VERSION ""

NS_ :

BS_:

BU_: ESM HIB HIP HIS SaGE CBC DASM DIAGNOST EBCM ECM EPS ESC ESL ETM HALF HCP IC OCM ORC PTS RF_HUB SCCM SGW

BO_ 1468 ECU_APPL_BSMO: 8 ESC
 SG_ ECU_APPL_BSMO : 7|64@0+ (1,0) [0|0] ""  DIAGNOST,SGW

BO_ 1409 ECU_APPL_CBC: 8 CBC
 SG_ ECU_APPL_CBC : 7|64@0+ (1,0) [0|0] ""  DIAGNOST,SGW

BO_ 1427 ECU_APPL_DASM: 8 DASM
 SG_ ECU_APPL_DASM : 7|64@0+ (1,0) [0|0] ""  DIAGNOST,SGW

BO_ 1467 ECU_APPL_EBCM: 8 EBCM
 SG_ ECU_APPL_EBCM : 7|64@0+ (1,0) [0|0] ""  DIAGNOST,SGW

BO_ 1464 ECU_APPL_ECM: 8 ECM
 SG_ ECU_APPL_ECM : 7|64@0+ (1,0) [0|0] ""  DIAGNOST,SGW

BO_ 1434 ECU_APPL_EPS: 8 EPS
 SG_ ECU_APPL_EPS : 7|64@0+ (1,0) [0|0] ""  DIAGNOST,SGW

BO_ 1416 ECU_APPL_ESL: 8 ESL
 SG_ ECU_APPL_ESL : 7|64@0+ (1,0) [0|0] ""  DIAGNOST,SGW

BO_ 1417 ECU_APPL_ESM: 8 ESM
 SG_ ECU_APPL_ESM : 7|64@0+ (1,0) [0|0] ""  DIAGNOST,SGW

BO_ 1466 ECU_APPL_HCP: 8 HCP
 SG_ ECU_APPL_HCP : 7|64@0+ (1,0) [0|0] ""  DIAGNOST,SGW

BO_ 1444 ECU_APPL_HaLF: 8 HALF
 SG_ ECU_APPL_HaLF : 7|64@0+ (1,0) [0|0] ""  DIAGNOST,SGW

BO_ 1410 ECU_APPL_IC: 8 IC
 SG_ ECU_APPL_IC : 7|64@0+ (1,0) [0|0] ""  DIAGNOST,SGW

BO_ 1438 ECU_APPL_OCM: 8 OCM
 SG_ ECU_APPL_OCM : 7|64@0+ (1,0) [0|0] ""  DIAGNOST,SGW

BO_ 1412 ECU_APPL_ORC: 8 ORC
 SG_ ECU_APPL_ORC : 7|64@0+ (1,0) [0|0] ""  DIAGNOST,SGW

BO_ 1442 ECU_APPL_PTS: 8 PTS
 SG_ ECU_APPL_PTS : 7|64@0+ (1,0) [0|0] ""  DIAGNOST,SGW

BO_ 1408 ECU_APPL_RF_HUB: 8 RF_HUB
 SG_ ECU_APPL_RF_HUB : 7|64@0+ (1,0) [0|0] ""  DIAGNOST,SGW

BO_ 1443 ECU_APPL_SCCM: 8 SCCM
 SG_ ECU_APPL_SCCM : 7|64@0+ (1,0) [0|0] ""  DIAGNOST,SGW

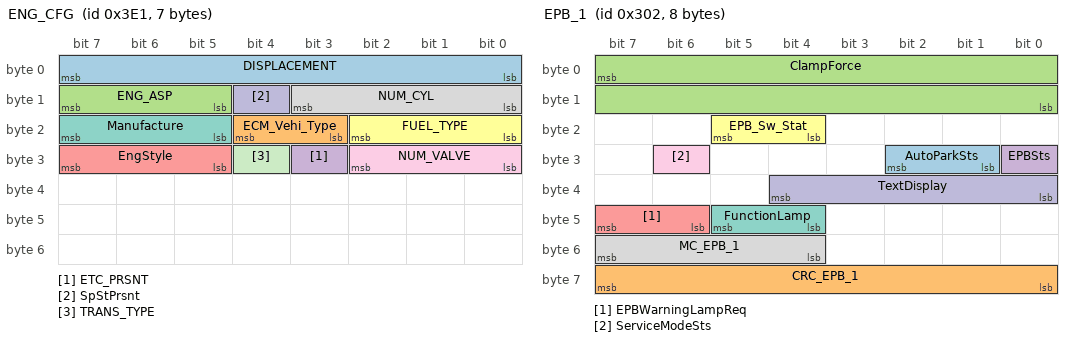
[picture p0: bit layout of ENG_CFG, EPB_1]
BO_ 993 ENG_CFG: 7 ECM
 SG_ DISPLACEMENT : 0|8@1+ (0.1,0) [0|25] "liters"  HIB,ESC,ETM,HALF,ORC,SGW
 SG_ ECM_Vehi_Type : 19|2@1+ (1,0) [0|0] ""  SGW
 SG_ ENG_ASP : 13|3@1+ (1,0) [0|0] ""  ESC,SGW
 SG_ ETC_PRSNT : 27|1@1+ (1,0) [0|0] ""  SGW
 SG_ EngStyle : 29|3@1+ (1,0) [0|0] ""  CBC,ESC,SGW
 SG_ FUEL_TYPE : 16|3@1+ (1,0) [0|0] ""  CBC,ESC,ETM,IC,ORC,SGW
 SG_ Manufacture : 21|3@1+ (1,0) [0|0] ""  SGW
 SG_ NUM_CYL : 8|4@1+ (1,0) [0|14] "cylinders"  HIB,ESC,ETM,HALF,IC,SGW
 SG_ NUM_VALVE : 24|3@1+ (1,0) [0|6] "valve-per-cylinder"  SGW
 SG_ SpStPrsnt : 12|1@1+ (1,0) [0|0] ""  HIB,CBC,EPS,ESC,HALF,IC,PTS,SGW
 SG_ TRANS_TYPE : 28|1@1+ (1,0) [0|0] ""  ETM,SGW

BO_ 770 EPB_1: 8 ESC
 SG_ AutoParkSts : 25|2@1+ (1,0) [0|0] ""  CBC,SGW
 SG_ CRC_EPB_1 : 56|8@1+ (1,0) [0|0] ""  HIB,DASM,ECM,IC,SGW
 SG_ ClampForce : 7|16@0+ (1,0) [0|65535] "N"  ORC,SGW
 SG_ EPBSts : 24|1@1+ (1,0) [0|0] ""  HIB,DASM,ECM,ETM,HCP,SGW
 SG_ EPBWarningLampReq : 46|2@1+ (1,0) [0|0] ""  IC,ORC,SGW
 SG_ EPB_Sw_Stat : 20|2@1+ (1,0) [0|0] ""  ORC,SGW
 SG_ FunctionLamp : 44|2@1+ (1,0) [0|0] ""  IC,SGW
 SG_ MC_EPB_1 : 52|4@1+ (1,0) [0|15] ""  HIB,DASM,ECM,IC,SGW
 SG_ ServiceModeSts : 30|1@1+ (1,0) [0|0] ""  CBC,SGW
 SG_ TextDisplay : 32|5@1+ (1,0) [0|0] ""  CBC,IC,SGW

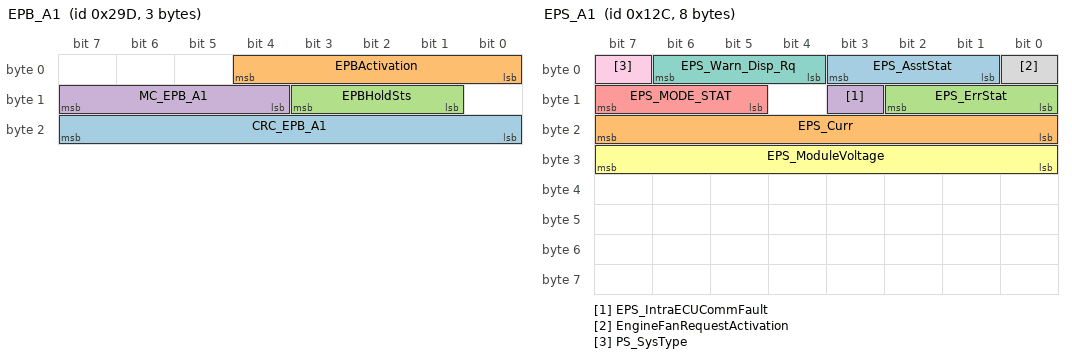
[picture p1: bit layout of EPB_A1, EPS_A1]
BO_ 669 EPB_A1: 3 ESC
 SG_ CRC_EPB_A1 : 16|8@1+ (1,0) [0|0] ""  HIB,DASM,ECM,HCP,PTS,SGW
 SG_ EPBActivation : 0|5@1+ (1,0) [0|0] ""  SGW
 SG_ EPBHoldSts : 9|3@1+ (1,0) [0|0] ""  HIB,CBC,DASM,ECM,HCP,ORC,PTS,SGW
 SG_ MC_EPB_A1 : 12|4@1+ (1,0) [0|15] ""  HIB,DASM,ECM,HCP,PTS,SGW

BO_ 544 EPS_1: 8 EPS
 SG_ DSTTorqueOverlayIntActivated : 37|1@1+ (1,0) [0|0] ""  HALF,ESC
 SG_ AssistanceTorque : 19|12@0+ (0.05,-100) [-100|104.65] "Nm"  HIS,ESC
 SG_ DSTTorqueOverlayFault : 21|1@1+ (1,0) [0|0] ""  HALF,ESC
 SG_ TOI_Act_Sts : 3|4@1+ (1,0) [0|0] ""  ORC,ESC
 SG_ CRC_EPS_1 : 56|8@1+ (1,0) [0|0] ""  HIB,ECM,ESC,HALF,PTS,SGW
 SG_ EPSHandsOnRecognition : 48|1@1+ (1,0) [0|0] ""  PTS,SGW
 SG_ EPSMotorTorque : 34|11@0+ (0.001953125,-2) [-2|1.998047] "Nm"  HIB,HALF,ORC,SGW
 SG_ EPSMotorTorqueValidData : 39|1@1+ (1,0) [0|0] ""  HIB,HALF,SGW
 SG_ EPSTemporaryDeactivationLDW : 38|1@1+ (1,0) [0|0] ""  HIB,HALF,SGW
 SG_ EPSTemporaryDeactivationPPPA : 49|1@1+ (1,0) [0|0] ""  PTS,SGW
 SG_ HALFTorqueOverlayFault : 22|1@1+ (1,0) [0|0] ""  HIB,HALF,SGW
 SG_ HALFTorqueOverlayIntActivated : 23|1@1+ (1,0) [0|0] ""  HIB,HALF,ORC,SGW
 SG_ MC_EPS_1 : 52|4@1+ (1,0) [0|15] ""  HIB,ECM,ESC,HALF,PTS,SGW
 SG_ PTSDriveStyleSts : 20|1@1+ (1,0) [0|0] ""  PTS,SGW
 SG_ PTSTorqueOverlayFault : 50|1@1+ (1,0) [0|0] ""  PTS,SGW
 SG_ PTSTorqueOverlayIntActivated : 51|1@1+ (1,0) [0|0] ""  PTS,SGW
 SG_ StrClmTrq : 2|11@0+ (0.0078125,-8) [-8|7.98] "Nm"  HIB,ECM,HALF,ORC,PTS,SGW
 SG_ StrClmTrqVD : 7|1@1+ (1,0) [0|0] ""  HIB,ECM,HALF,PTS,SGW

BO_ 300 EPS_A1: 8 EPS
 SG_ EPS_AsstStat : 1|3@1+ (1,0) [0|0] ""  HIS,ESC,SGW
 SG_ EPS_Curr : 16|8@1+ (1,-50) [-50|204] "Amp"  HIS,SGW
 SG_ EPS_ErrStat : 8|3@1+ (1,0) [0|0] ""  HIS,SGW
 SG_ EPS_IntraECUCommFault : 11|1@1+ (1,0) [0|0] ""  HIS,SGW
 SG_ EPS_MODE_STAT : 13|3@1+ (1,0) [0|0] ""  HIS,HIB,CBC,HALF,ORC,SGW
 SG_ EPS_ModuleVoltage : 24|8@1+ (0.1,0) [0|25.4] "Volts"  HIS,SGW
 SG_ EPS_Warn_Disp_Rq : 4|3@1+ (1,0) [0|0] ""  HIS,CBC,ETM,IC,ORC,SGW
 SG_ EngineFanRequestActivation : 0|1@1+ (1,0) [0|0] ""  HIS,ECM,SGW
 SG_ PS_SysType : 7|1@1+ (1,0) [0|0] ""  HIS,CBC,ESC,SGW

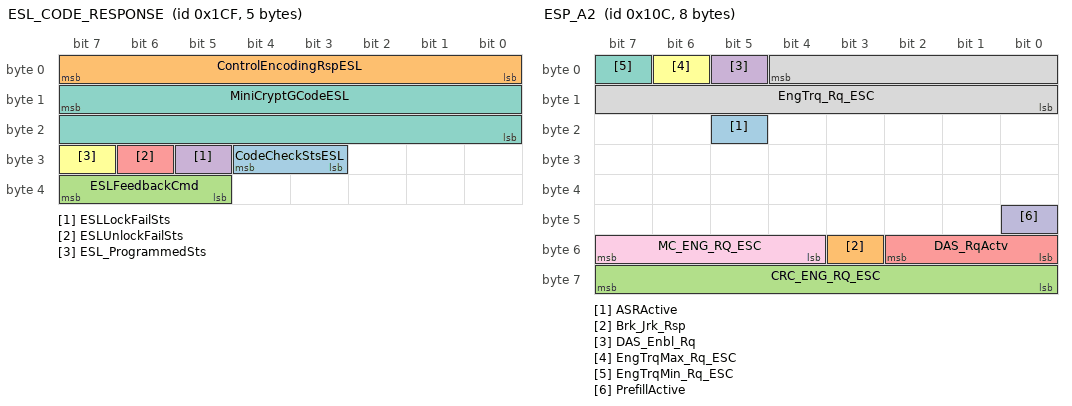
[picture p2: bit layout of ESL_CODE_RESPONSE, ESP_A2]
BO_ 463 ESL_CODE_RESPONSE: 5 ESL
 SG_ CodeCheckStsESL : 27|2@1+ (1,0) [0|0] ""  CBC,SGW
 SG_ ControlEncodingRspESL : 0|8@1+ (1,0) [0|0] ""  CBC,SGW
 SG_ ESLFeedbackCmd : 37|3@1+ (1,0) [0|0] ""  CBC,SGW
 SG_ ESLLockFailSts : 29|1@1+ (1,0) [0|0] ""  CBC,SGW
 SG_ ESLUnlockFailSts : 30|1@1+ (1,0) [0|0] ""  CBC,SGW
 SG_ ESL_ProgrammedSts : 31|1@1+ (1,0) [0|0] ""  SGW
 SG_ MiniCryptGCodeESL : 15|16@0+ (1,0) [0|0] ""  CBC,SGW

BO_ 320 ESP_A1: 8 ESC
 SG_ ABS_BrkEvt : 14|1@1+ (1,0) [0|0] ""  DASM,HALF,ORC,PTS,SGW
 SG_ BrkIntrvntn_Actv_AS : 6|1@1+ (1,0) [0|0] ""  HIB,DASM,ETM,SGW
 SG_ BrkIntrvntn_Actv_ESP : 5|1@1+ (1,0) [0|0] ""  HIB,ETM,HALF,ORC,PTS,SGW
 SG_ BrkIntrvntn_Enbl : 7|1@1+ (1,0) [0|0] ""  ECM,ORC,SGW
 SG_ BrkPdl_Flt : 4|1@1+ (1,0) [0|0] ""  HIB,DASM,ECM,ETM,HALF,SGW
 SG_ BrkPdl_Stat : 2|2@1+ (1,0) [0|0] ""  HIB,CBC,DASM,ECM,HALF,HCP,ORC,RF_HUB,SGW
 SG_ Brk_Stat : 0|2@1+ (1,0) [0|0] ""  HIB,CBC,DASM,ECM,HALF,PTS,SGW
 SG_ Brk_Thermdl : 25|1@1+ (1,0) [0|0] ""  HIB,DASM,SGW
 SG_ CRC_Brk_Stat : 56|8@1+ (1,0) [0|0] ""  HIB,DASM,ECM,HALF,HCP,IC,ORC,PTS,SGW
 SG_ DTR_CC_Enabled : 23|1@1+ (1,0) [0|0] ""  ECM,SGW
 SG_ DTR_CC_Engaged : 15|1@1+ (1,0) [0|0] ""  CBC,ECM,HCP,SGW
 SG_ ESP_Sys_Stat : 10|2@1+ (1,0) [0|0] ""  HIB,DASM,ECM,ETM,HALF,PTS,SGW
 SG_ EmgBrk_Actv : 8|1@1+ (1,0) [0|0] ""  ORC,SGW
 SG_ FullBrk_Actv : 9|1@1+ (1,0) [0|0] ""  ORC,SGW
 SG_ MC_Brk_Stat : 52|4@1+ (1,0) [0|15] ""  HIB,DASM,ECM,HALF,HCP,IC,ORC,PTS,SGW
 SG_ REF_VEH_SPEED : 33|10@0+ (0.5,0) [0|511] "km/h"  HCP,ORC,SGW
 SG_ RollTestMd_Actv : 30|2@1+ (1,0) [0|0] ""  HIB,DASM,SGW
 SG_ SPCR_AS_Off_Rq : 38|2@1+ (1,0) [0|0] ""  HIB,DASM,ECM,SGW

BO_ 268 ESP_A2: 8 ESC
 SG_ ASRActive : 21|1@1+ (1,0) [0|0] ""  HIB,DASM,ORC,SGW
 SG_ Brk_Jrk_Rsp : 51|1@1+ (1,0) [0|0] ""  HIB,DASM,ORC,SGW
 SG_ CRC_ENG_RQ_ESC : 56|8@1+ (1,0) [0|0] ""  HIB,DASM,ECM,SGW
 SG_ DAS_Enbl_Rq : 5|1@1+ (1,0) [0|0] ""  HIB,DASM,ECM,SGW
 SG_ DAS_RqActv : 48|3@1+ (1,0) [0|0] ""  HIB,DASM,HALF,ORC,SGW
 SG_ EngTrqMax_Rq_ESC : 6|1@1+ (1,0) [0|0] ""  SGW
 SG_ EngTrqMin_Rq_ESC : 7|1@1+ (1,0) [0|0] ""  SGW
 SG_ EngTrq_Rq_ESC : 4|13@0+ (0.25,-500) [-500|1547.5] "Nm"  ETM,SGW
 SG_ MC_ENG_RQ_ESC : 52|4@1+ (1,0) [0|15] ""  HIB,DASM,ECM,SGW
 SG_ PrefillActive : 40|1@1+ (1,0) [0|0] ""  HIB,DASM,SGW

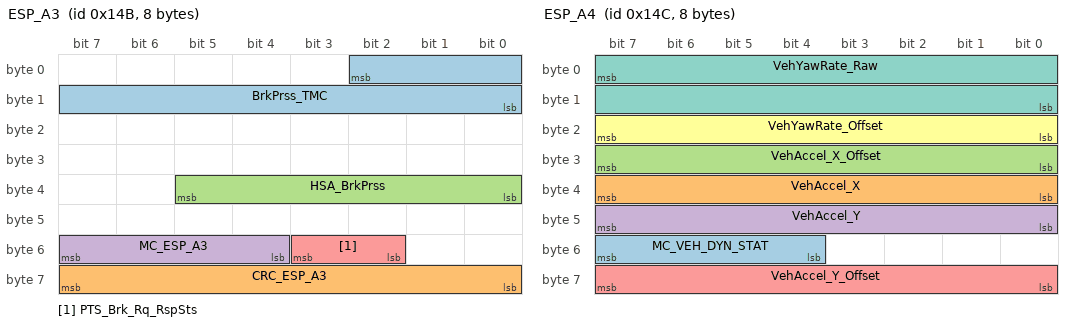
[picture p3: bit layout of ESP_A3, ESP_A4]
BO_ 331 ESP_A3: 8 ESC
 SG_ BrkPrss_TMC : 2|11@0+ (0.1,0) [0|200] "bar"  HIB,ECM,ETM,HALF,HCP,ORC,SGW
 SG_ CRC_ESP_A3 : 56|8@1+ (1,0) [0|0] ""  ECM,HCP,ORC,PTS,SGW
 SG_ HSA_BrkPrss : 32|6@1+ (1,0) [0|50] "bar"  ECM,ETM,ORC,SGW
 SG_ MC_ESP_A3 : 52|4@1+ (1,0) [0|15] ""  ECM,HCP,ORC,PTS,SGW
 SG_ PTS_Brk_Rq_RspSts : 50|2@1+ (1,0) [0|0] ""  IC,PTS,SGW

BO_ 332 ESP_A4: 8 ESC
 SG_ MC_VEH_DYN_STAT : 52|4@1+ (1,0) [0|15] ""  HIB,DASM,ECM,ETM,HALF,ORC,PTS,SGW
 SG_ VehAccel_X : 32|8@1+ (0.08,-10.24) [-10.24|10.08] "m/s²"  HIB,EBCM,CBC,DASM,ECM,HALF,HCP,PTS,SGW
 SG_ VehAccel_X_Offset : 24|8@1+ (0.02,-2.56) [-2.56|2.52] "m/s²"  HIB,EBCM,DASM,ECM,ETM,HALF,HCP,PTS,SGW
 SG_ VehAccel_Y : 40|8@1+ (0.08,-10.24) [-10.24|10.08] "m/s²"  HIB,DASM,ECM,EPS,HALF,HCP,SGW
 SG_ VehAccel_Y_Offset : 56|8@1+ (0.02,-2.56) [-2.56|2.52] "m/s²"  HIB,DASM,ECM,ETM,HALF,HCP,SGW
 SG_ VehYawRate_Offset : 16|8@1+ (0.08,-10.24) [-6.96|6.96] ""  HIB,DASM,HALF,ORC,SGW
 SG_ VehYawRate_Raw : 7|16@0+ (0.01,-327.68) [-327.68|327.66] "°/s"  HIB,CBC,DASM,ETM,HALF,PTS,SGW

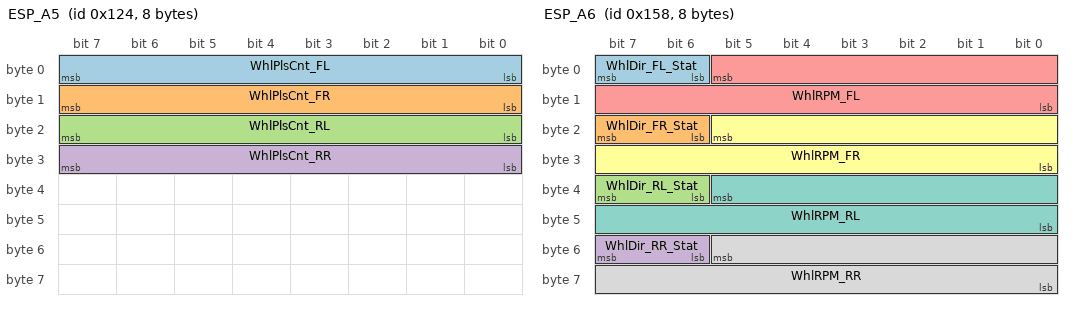
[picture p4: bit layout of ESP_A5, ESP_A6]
BO_ 292 ESP_A5: 8 ESC
 SG_ WhlPlsCnt_FL : 0|8@1+ (1,0) [0|254] "Impulse"  HIB,CBC,DASM,PTS,RF_HUB,SGW
 SG_ WhlPlsCnt_FR : 8|8@1+ (1,0) [0|254] "Impulse"  HIB,CBC,DASM,PTS,RF_HUB,SGW
 SG_ WhlPlsCnt_RL : 16|8@1+ (1,0) [0|254] "Impulse"  HIB,CBC,DASM,EPS,PTS,RF_HUB,SGW
 SG_ WhlPlsCnt_RR : 24|8@1+ (1,0) [0|254] "Impulse"  HIB,CBC,DASM,EPS,PTS,RF_HUB,SGW

BO_ 344 ESP_A6: 8 ESC
 SG_ WhlDir_FL_Stat : 6|2@1+ (1,0) [0|0] ""  HIB,DASM,HCP,SGW
 SG_ WhlDir_FR_Stat : 22|2@1+ (1,0) [0|0] ""  HIB,DASM,HCP,SGW
 SG_ WhlDir_RL_Stat : 38|2@1+ (1,0) [0|0] ""  HIB,DASM,EPS,HCP,ORC,PTS,SGW
 SG_ WhlDir_RR_Stat : 54|2@1+ (1,0) [0|0] ""  HIB,DASM,EPS,HCP,ORC,PTS,SGW
 SG_ WhlRPM_FL : 5|14@0+ (0.5,0) [0|8191] "rpm"  HIB,DASM,HCP,ORC,PTS,SGW
 SG_ WhlRPM_FR : 21|14@0+ (0.5,0) [0|8191] "rpm"  HIB,DASM,HCP,ORC,PTS,SGW
 SG_ WhlRPM_RL : 37|14@0+ (0.5,0) [0|8191] "rpm"  HIB,DASM,HCP,ORC,PTS,SGW
 SG_ WhlRPM_RR : 53|14@0+ (0.5,0) [0|8191] "rpm"  HIB,DASM,HCP,ORC,PTS,SGW

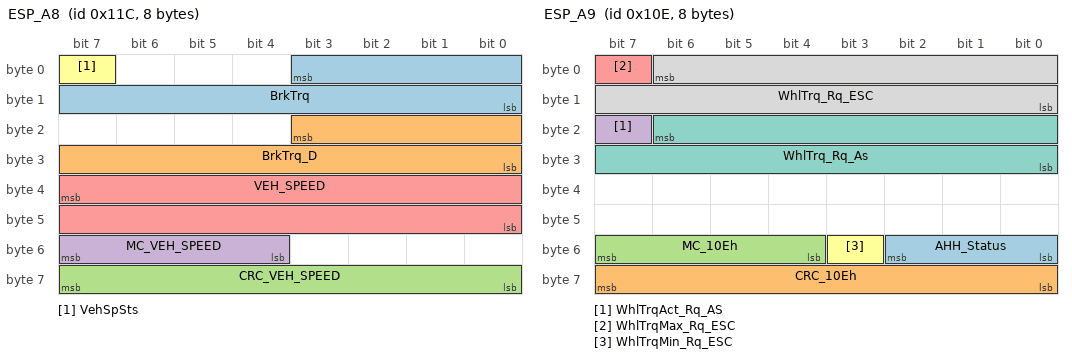
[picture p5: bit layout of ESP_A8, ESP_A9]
BO_ 284 ESP_A8: 8 ESC
 SG_ BrkTrq : 3|12@0+ (3,0) [0|12282] "Nm"  HIB,DASM,ORC,SGW
 SG_ BrkTrq_D : 19|12@0+ (3,0) [0|12282] "Nm"  HIB,DASM,SGW
 SG_ CRC_VEH_SPEED : 56|8@1+ (1,0) [0|0] ""  HIB,DASM,EBCM,ECM,EPS,ESL,HALF,HCP,IC,ORC,PTS,SGW
 SG_ MC_VEH_SPEED : 52|4@1+ (1,0) [0|15] ""  HIB,DASM,EBCM,ECM,EPS,ESL,HALF,HCP,IC,ORC,PTS,SGW
 SG_ VEH_SPEED : 39|16@0+ (0.0078125,0) [0|511.984375] "km/h"  HIB,CBC,DASM,EBCM,ECM,EPS,ESL,HALF,HCP,IC,ORC,PTS,RF_HUB,SGW
 SG_ VehSpSts : 7|1@1+ (1,0) [0|0] ""  HIB,DASM,SGW

BO_ 270 ESP_A9: 8 ESC
 SG_ AHH_Status : 48|3@1+ (1,0) [0|0] ""  HCP,SGW
 SG_ CRC_10Eh : 56|8@1+ (1,0) [0|255] ""  HIB,DASM,ECM,SGW
 SG_ MC_10Eh : 52|4@1+ (1,0) [0|15] ""  HIB,DASM,ECM,SGW
 SG_ WhlTrqAct_Rq_AS : 23|1@1+ (1,0) [0|0] ""  ECM,SGW
 SG_ WhlTrqMax_Rq_ESC : 7|1@1+ (1,0) [0|0] ""  HIB,DASM,ECM,SGW
 SG_ WhlTrqMin_Rq_ESC : 51|1@1+ (1,0) [0|0] ""  ECM,SGW
 SG_ WhlTrq_Rq_As : 22|15@0+ (1,-7767) [-7767|24999] "Nm"  ECM,ORC,SGW
 SG_ WhlTrq_Rq_ESC : 6|15@0+ (1,-7767) [-7767|24999] "Nm"  HIB,DASM,ECM,SGW

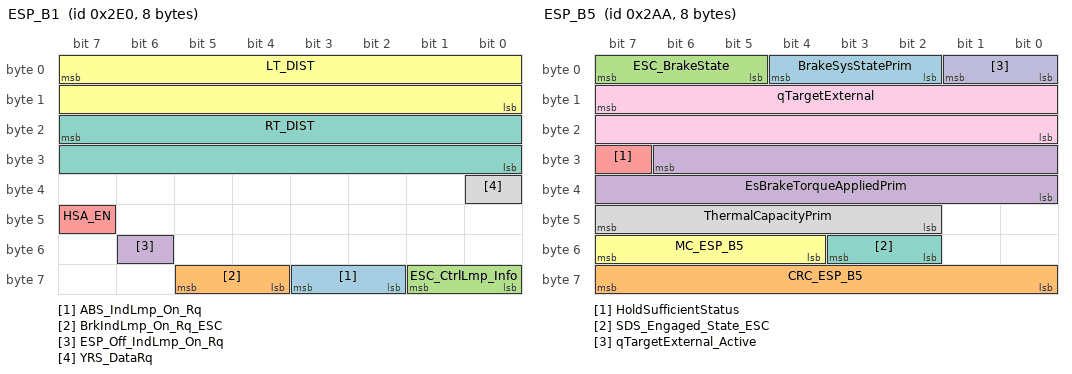
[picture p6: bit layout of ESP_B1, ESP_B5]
BO_ 736 ESP_B1: 8 ESC
 SG_ ABS_IndLmp_On_Rq : 58|2@1+ (1,0) [0|0] ""  ETM,IC,SGW
 SG_ BrkIndLmp_On_Rq_ESC : 60|2@1+ (1,0) [0|0] ""  ETM,IC,ORC,SGW
 SG_ ESC_CtrlLmp_Info : 56|2@1+ (1,0) [0|0] ""  ETM,IC,ORC,SGW
 SG_ ESP_Off_IndLmp_On_Rq : 54|1@1+ (1,0) [0|0] ""  CBC,IC,ORC,SGW
 SG_ HSA_EN : 47|1@1+ (1,0) [0|0] ""  CBC,SGW
 SG_ LT_DIST : 7|16@0+ (4,0) [0|262136] "cm"  CBC,ECM,IC,PTS,SGW
 SG_ RT_DIST : 23|16@0+ (4,0) [0|262136] "cm"  CBC,ECM,IC,PTS,SGW
 SG_ YRS_DataRq : 32|1@1+ (1,0) [0|0] ""  ORC,SGW

BO_ 737 ESP_B2: 8 ESC
 SG_ ESCSysEmsMlfAtv : 18|1@1+ (1,0) [0|0] ""  SGW
 SG_ MIL_OnRq_ESC : 2|1@1+ (1,0) [0|0] ""  ECM,HCP,SGW

BO_ 682 ESP_B5: 8 ESC
 SG_ BrakeSysStatePrim : 2|3@1+ (1,0) [0|0] ""  EBCM,SGW
 SG_ CRC_ESP_B5 : 56|8@1+ (1,0) [0|0] ""  EBCM,SGW
 SG_ ESC_BrakeState : 5|3@1+ (1,0) [0|0] ""  EBCM,SGW
 SG_ EsBrakeTorqueAppliedPrim : 30|15@0+ (2,-65534) [-65534|0] "Nm"  SGW
 SG_ HoldSufficientStatus : 31|1@1+ (1,0) [0|0] ""  SGW
 SG_ MC_ESP_B5 : 52|4@1+ (1,0) [0|15] ""  EBCM,SGW
 SG_ SDS_Engaged_State_ESC : 50|2@1+ (1,0) [0|0] ""  SGW
 SG_ ThermalCapacityPrim : 42|6@1+ (1.5873,0) [0|99.9999] "%"  SGW
 SG_ qTargetExternal : 15|16@0+ (0.0078125,-252) [-252|252] "ml/sec"  SGW
 SG_ qTargetExternal_Active : 0|2@1+ (1,0) [0|0] ""  SGW

BO_ 840 ESP_C1: 8 ESC
 SG_ FailSafeError : 7|16@0+ (1,0) [0|65534] ""  HIB,DASM,SGW

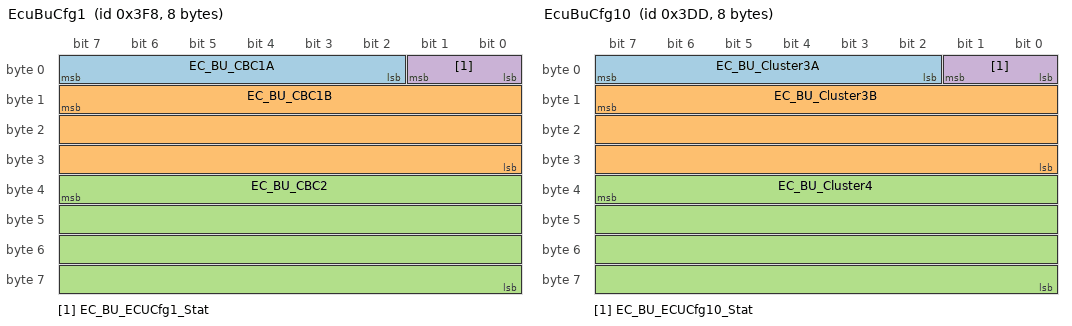
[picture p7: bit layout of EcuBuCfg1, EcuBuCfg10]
BO_ 1016 EcuBuCfg1: 8 RF_HUB
 SG_ EC_BU_CBC1A : 2|6@1+ (1,0) [0|0] ""  CBC,SGW
 SG_ EC_BU_CBC1B : 15|24@0+ (1,0) [0|0] ""  CBC,SGW
 SG_ EC_BU_CBC2 : 39|32@0+ (1,0) [0|0] ""  CBC,SGW
 SG_ EC_BU_ECUCfg1_Stat : 0|2@1+ (1,0) [0|0] ""  CBC,SGW

BO_ 989 EcuBuCfg10: 8 RF_HUB
 SG_ EC_BU_Cluster3A : 2|6@1+ (1,0) [0|0] ""  CBC,SGW
 SG_ EC_BU_Cluster3B : 15|24@0+ (1,0) [0|0] ""  CBC,SGW
 SG_ EC_BU_Cluster4 : 39|32@0+ (1,0) [0|0] ""  CBC,SGW
 SG_ EC_BU_ECUCfg10_Stat : 0|2@1+ (1,0) [0|0] ""  CBC,SGW

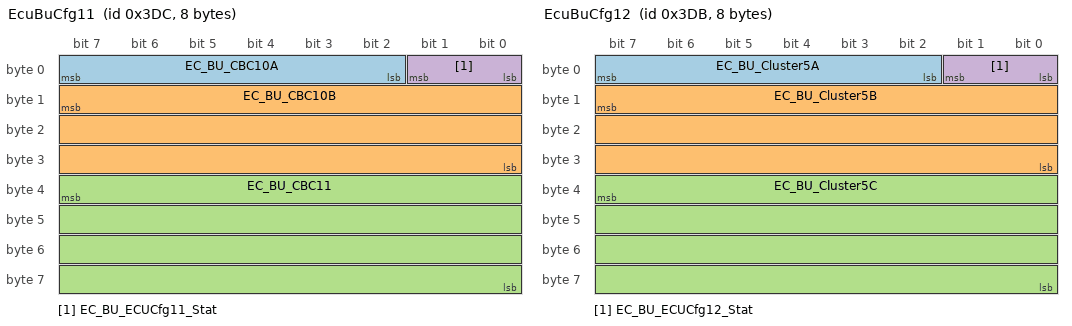
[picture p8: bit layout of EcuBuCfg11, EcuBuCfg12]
BO_ 988 EcuBuCfg11: 8 RF_HUB
 SG_ EC_BU_CBC10A : 2|6@1+ (1,0) [0|0] ""  CBC,SGW
 SG_ EC_BU_CBC10B : 15|24@0+ (1,0) [0|0] ""  CBC,SGW
 SG_ EC_BU_CBC11 : 39|32@0+ (1,0) [0|0] ""  CBC,SGW
 SG_ EC_BU_ECUCfg11_Stat : 0|2@1+ (1,0) [0|0] ""  CBC,SGW

BO_ 987 EcuBuCfg12: 8 RF_HUB
 SG_ EC_BU_Cluster5A : 2|6@1+ (1,0) [0|0] ""  CBC,SGW
 SG_ EC_BU_Cluster5B : 15|24@0+ (1,0) [0|0] ""  CBC,SGW
 SG_ EC_BU_Cluster5C : 39|32@0+ (1,0) [0|0] ""  CBC,SGW
 SG_ EC_BU_ECUCfg12_Stat : 0|2@1+ (1,0) [0|0] ""  CBC,SGW

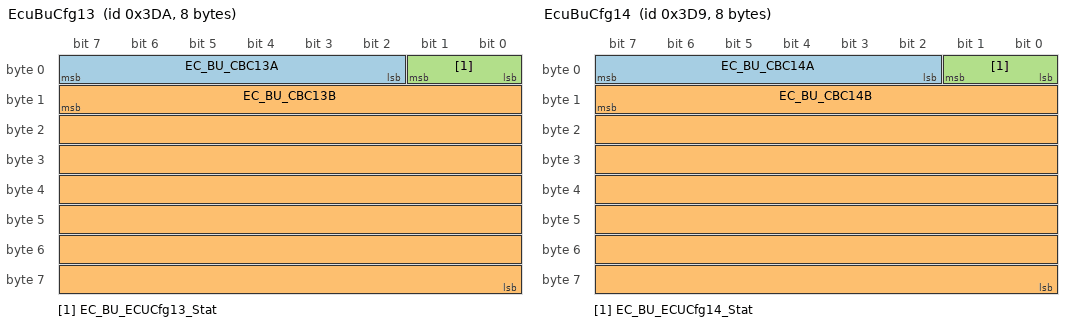
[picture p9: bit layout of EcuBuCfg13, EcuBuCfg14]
BO_ 986 EcuBuCfg13: 8 RF_HUB
 SG_ EC_BU_CBC13A : 2|6@1+ (1,0) [0|0] ""  CBC,SGW
 SG_ EC_BU_CBC13B : 15|56@0+ (1,0) [0|0] ""  CBC,SGW
 SG_ EC_BU_ECUCfg13_Stat : 0|2@1+ (1,0) [0|0] ""  CBC,SGW

BO_ 985 EcuBuCfg14: 8 RF_HUB
 SG_ EC_BU_CBC14A : 2|6@1+ (1,0) [0|0] ""  CBC,SGW
 SG_ EC_BU_CBC14B : 15|56@0+ (1,0) [0|0] ""  CBC,SGW
 SG_ EC_BU_ECUCfg14_Stat : 0|2@1+ (1,0) [0|0] ""  CBC,SGW

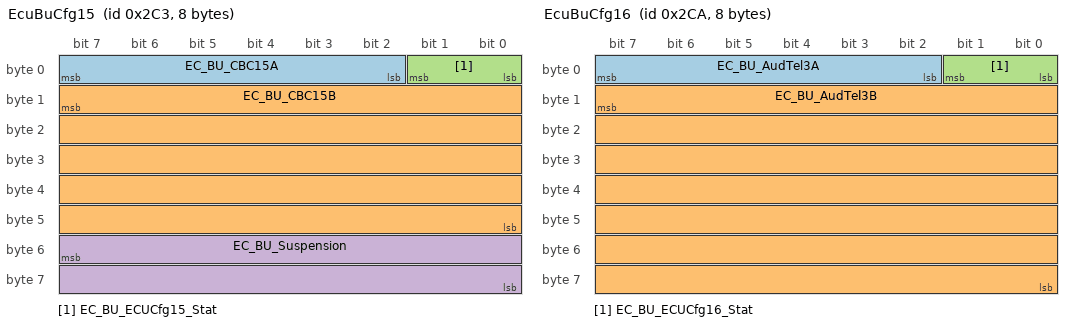
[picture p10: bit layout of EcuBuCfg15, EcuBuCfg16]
BO_ 707 EcuBuCfg15: 8 RF_HUB
 SG_ EC_BU_CBC15A : 2|6@1+ (1,0) [0|0] ""  CBC,SGW
 SG_ EC_BU_CBC15B : 15|40@0+ (1,0) [0|0] ""  CBC,SGW
 SG_ EC_BU_ECUCfg15_Stat : 0|2@1+ (1,0) [0|0] ""  CBC,SGW
 SG_ EC_BU_Suspension : 55|16@0+ (1,0) [0|0] ""  CBC,SGW

BO_ 714 EcuBuCfg16: 8 RF_HUB
 SG_ EC_BU_AudTel3A : 2|6@1+ (1,0) [0|0] ""  CBC,SGW
 SG_ EC_BU_AudTel3B : 15|56@0+ (1,0) [0|0] ""  CBC,SGW
 SG_ EC_BU_ECUCfg16_Stat : 0|2@1+ (1,0) [0|0] ""  CBC,SGW

BO_ 715 EcuBuCfg17: 8 RF_HUB
 SG_ EC_BU_ECUCfg17_Stat : 0|2@1+ (1,0) [0|0] ""  CBC,SGW
 SG_ EC_BU_PTS : 56|8@1+ (1,0) [0|0] ""  CBC,SGW

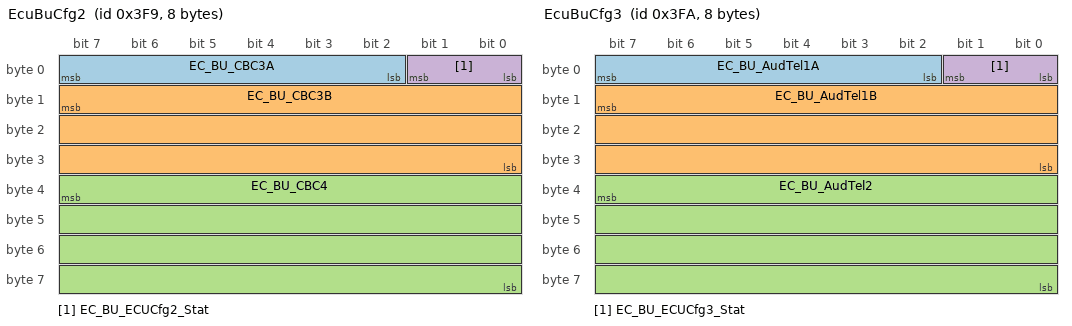
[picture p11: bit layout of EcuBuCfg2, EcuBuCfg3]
BO_ 1017 EcuBuCfg2: 8 RF_HUB
 SG_ EC_BU_CBC3A : 2|6@1+ (1,0) [0|0] ""  CBC,SGW
 SG_ EC_BU_CBC3B : 15|24@0+ (1,0) [0|0] ""  CBC,SGW
 SG_ EC_BU_CBC4 : 39|32@0+ (1,0) [0|0] ""  CBC,SGW
 SG_ EC_BU_ECUCfg2_Stat : 0|2@1+ (1,0) [0|0] ""  CBC,SGW

BO_ 1018 EcuBuCfg3: 8 RF_HUB
 SG_ EC_BU_AudTel1A : 2|6@1+ (1,0) [0|0] ""  CBC,SGW
 SG_ EC_BU_AudTel1B : 15|24@0+ (1,0) [0|0] ""  CBC,SGW
 SG_ EC_BU_AudTel2 : 39|32@0+ (1,0) [0|0] ""  CBC,SGW
 SG_ EC_BU_ECUCfg3_Stat : 0|2@1+ (1,0) [0|0] ""  CBC,SGW

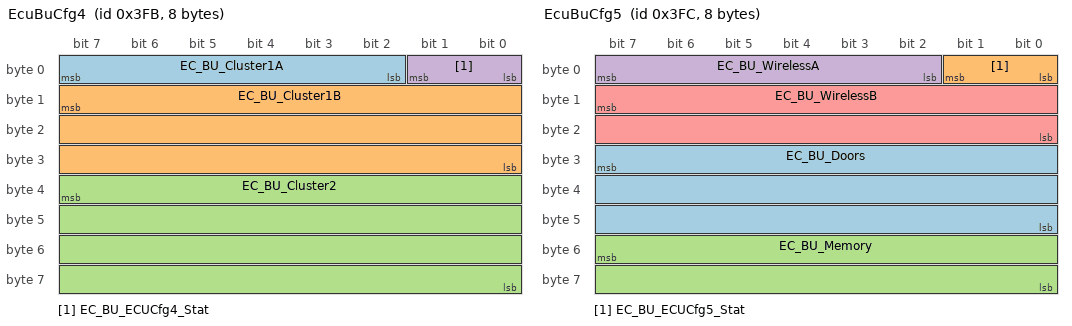
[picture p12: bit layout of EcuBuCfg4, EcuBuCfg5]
BO_ 1019 EcuBuCfg4: 8 RF_HUB
 SG_ EC_BU_Cluster1A : 2|6@1+ (1,0) [0|0] ""  CBC,SGW
 SG_ EC_BU_Cluster1B : 15|24@0+ (1,0) [0|0] ""  CBC,SGW
 SG_ EC_BU_Cluster2 : 39|32@0+ (1,0) [0|0] ""  CBC,SGW
 SG_ EC_BU_ECUCfg4_Stat : 0|2@1+ (1,0) [0|0] ""  CBC,SGW

BO_ 1020 EcuBuCfg5: 8 RF_HUB
 SG_ EC_BU_Doors : 31|24@0+ (1,0) [0|0] ""  CBC,SGW
 SG_ EC_BU_ECUCfg5_Stat : 0|2@1+ (1,0) [0|0] ""  CBC,SGW
 SG_ EC_BU_Memory : 55|16@0+ (1,0) [0|0] ""  CBC,SGW
 SG_ EC_BU_WirelessA : 2|6@1+ (1,0) [0|0] ""  CBC,SGW
 SG_ EC_BU_WirelessB : 15|16@0+ (1,0) [0|0] ""  CBC,SGW

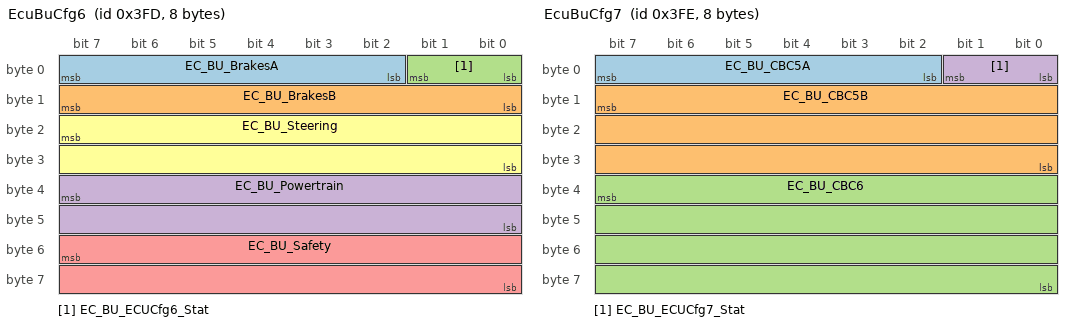
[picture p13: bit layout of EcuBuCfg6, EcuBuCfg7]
BO_ 1021 EcuBuCfg6: 8 RF_HUB
 SG_ EC_BU_BrakesA : 2|6@1+ (1,0) [0|0] ""  CBC,SGW
 SG_ EC_BU_BrakesB : 8|8@1+ (1,0) [0|0] ""  CBC,SGW
 SG_ EC_BU_ECUCfg6_Stat : 0|2@1+ (1,0) [0|0] ""  CBC,SGW
 SG_ EC_BU_Powertrain : 39|16@0+ (1,0) [0|0] ""  CBC,SGW
 SG_ EC_BU_Safety : 55|16@0+ (1,0) [0|0] ""  CBC,SGW
 SG_ EC_BU_Steering : 23|16@0+ (1,0) [0|0] ""  CBC,SGW

BO_ 1022 EcuBuCfg7: 8 RF_HUB
 SG_ EC_BU_CBC5A : 2|6@1+ (1,0) [0|0] ""  CBC,SGW
 SG_ EC_BU_CBC5B : 15|24@0+ (1,0) [0|0] ""  CBC,SGW
 SG_ EC_BU_CBC6 : 39|32@0+ (1,0) [0|0] ""  CBC,SGW
 SG_ EC_BU_ECUCfg7_Stat : 0|2@1+ (1,0) [0|0] ""  CBC,SGW

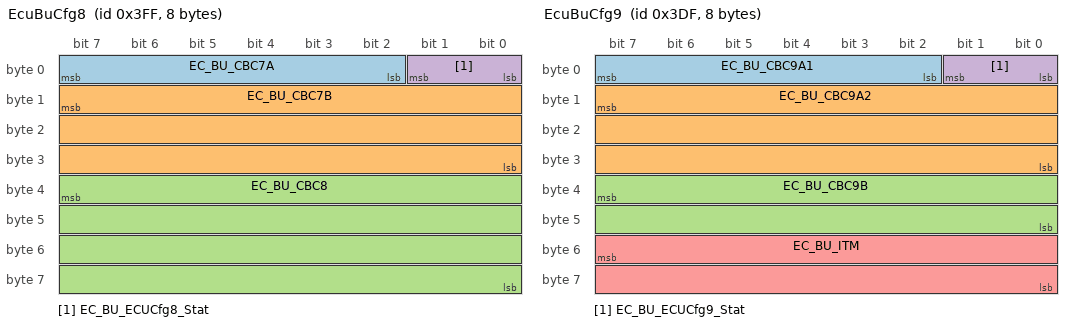
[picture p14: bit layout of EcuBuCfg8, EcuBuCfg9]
BO_ 1023 EcuBuCfg8: 8 RF_HUB
 SG_ EC_BU_CBC7A : 2|6@1+ (1,0) [0|0] ""  CBC,SGW
 SG_ EC_BU_CBC7B : 15|24@0+ (1,0) [0|0] ""  CBC,SGW
 SG_ EC_BU_CBC8 : 39|32@0+ (1,0) [0|0] ""  CBC,SGW
 SG_ EC_BU_ECUCfg8_Stat : 0|2@1+ (1,0) [0|0] ""  CBC,SGW

BO_ 991 EcuBuCfg9: 8 RF_HUB
 SG_ EC_BU_CBC9A1 : 2|6@1+ (1,0) [0|0] ""  CBC,SGW
 SG_ EC_BU_CBC9A2 : 15|24@0+ (1,0) [0|0] ""  CBC,SGW
 SG_ EC_BU_CBC9B : 39|16@0+ (1,0) [0|0] ""  CBC,SGW
 SG_ EC_BU_ECUCfg9_Stat : 0|2@1+ (1,0) [0|0] ""  CBC,SGW
 SG_ EC_BU_ITM : 55|16@0+ (1,0) [0|0] ""  CBC,SGW

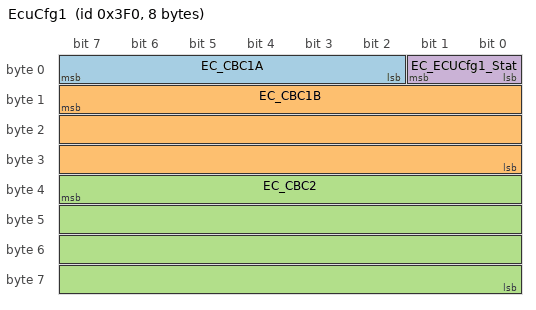
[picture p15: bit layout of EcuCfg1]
BO_ 1008 EcuCfg1: 8 CBC
 SG_ EC_CBC1A : 2|6@1+ (1,0) [0|0] ""  RF_HUB,SGW
 SG_ EC_CBC1B : 15|24@0+ (1,0) [0|0] ""  RF_HUB,SGW
 SG_ EC_CBC2 : 39|32@0+ (1,0) [0|0] ""  RF_HUB,SGW
 SG_ EC_ECUCfg1_Stat : 0|2@1+ (1,0) [0|0] ""  RF_HUB,SGW

CM_ SG_ 1468 ECU_APPL_BSMO "ECU to External Application";
CM_ SG_ 1409 ECU_APPL_CBC "ECU to External Application";
CM_ SG_ 1427 ECU_APPL_DASM "ECU to External Application";
CM_ SG_ 1467 ECU_APPL_EBCM "ECU to External Application";
CM_ SG_ 1464 ECU_APPL_ECM "ECU to External Application";
CM_ SG_ 1434 ECU_APPL_EPS "ECU to External Application";
CM_ SG_ 1416 ECU_APPL_ESL "ECU to External Application";
CM_ SG_ 1417 ECU_APPL_ESM "ECU to External Application";
CM_ SG_ 1466 ECU_APPL_HCP "ECU to External Application";
CM_ SG_ 1444 ECU_APPL_HaLF "ECU to External Application";
CM_ SG_ 1410 ECU_APPL_IC "ECU to External Application";
CM_ SG_ 1438 ECU_APPL_OCM "ECU to External Application";
CM_ SG_ 1412 ECU_APPL_ORC "ECU to External Application";
CM_ SG_ 1442 ECU_APPL_PTS "ECU to External Application";
CM_ SG_ 1408 ECU_APPL_RF_HUB "ECU to External Application";
CM_ SG_ 1443 ECU_APPL_SCCM "ECU to External Application";
CM_ SG_ 993 DISPLACEMENT "Engine displacement";
CM_ SG_ 993 ECM_Vehi_Type "Engine vehicle type";
CM_ SG_ 993 ENG_ASP "Engine aspiration method";
CM_ SG_ 993 ETC_PRSNT "Electronic throttle control";
CM_ SG_ 993 EngStyle "Engine output version";
CM_ SG_ 993 FUEL_TYPE "Fuel type";
CM_ SG_ 993 Manufacture "Engine manufacture";
CM_ SG_ 993 NUM_CYL "Number of engine cylinders";
CM_ SG_ 993 NUM_VALVE "Number of valves per cylinder";
CM_ SG_ 993 SpStPrsnt "Stop start feature present";
CM_ SG_ 993 TRANS_TYPE "Transmission type; [0] = manual, [1] = automatic";
CM_ SG_ 770 AutoParkSts "EPB auto park brake function available status";
CM_ SG_ 770 CRC_EPB_1 "CRC-checksum byte 1 to 7 according to SAE J1850";
CM_ SG_ 770 ClampForce "EPB clamp force";
CM_ SG_ 770 EPBSts "EPB status; Enable = [1]";
CM_ SG_ 770 EPBWarningLampReq "EPB warning (fault) lamp active request";
CM_ SG_ 770 EPB_Sw_Stat "EPB switch state";
CM_ SG_ 770 FunctionLamp "EPB function lamp active request";
CM_ SG_ 770 MC_EPB_1 "Message counter";
CM_ SG_ 770 ServiceModeSts "EPB service mode; Service mode = [1]";
CM_ SG_ 770 TextDisplay "Text message display request";
CM_ SG_ 669 CRC_EPB_A1 "CRC-checksum byte 1 to 2 according to SAE J1850";
CM_ SG_ 669 EPBActivation "EPB activation reason";
CM_ SG_ 669 EPBHoldSts "EPB hold status";
CM_ SG_ 669 MC_EPB_A1 "Message counter";
CM_ SG_ 544 DSTTorqueOverlayIntActivated "DST torque overlay interface activated; True = [1]";
CM_ SG_ 544 AssistanceTorque "Torque provided by EPS system to the shaft for the driver";
CM_ SG_ 544 DSTTorqueOverlayFault "Torque overlay fault; True = 1";
CM_ SG_ 544 TOI_Act_Sts "Torque overlay interface status";
CM_ SG_ 544 CRC_EPS_1 "CRC-checksum byte 1 to 7 according to SAE J1850";
CM_ SG_ 544 EPSHandsOnRecognition "Driver interference during the semiautomatic parking maneuver; True = [1]";
CM_ SG_ 544 EPSMotorTorque "EPS motor torque";
CM_ SG_ 544 EPSMotorTorqueValidData "Motor torque: valid data [1]";
CM_ SG_ 544 EPSTemporaryDeactivationLDW "Temporary deactivation of the EPS LDW torque overlay function";
CM_ SG_ 544 EPSTemporaryDeactivationPPPA "Temporary deactivation of the EPS PPPA torque overlay function; True = [1]";
CM_ SG_ 544 HALFTorqueOverlayFault "Fault of the HALF torque overlay interface";
CM_ SG_ 544 HALFTorqueOverlayIntActivated "Torque overlay interface has been successfully activated; True = [1]";
CM_ SG_ 544 MC_EPS_1 "Message counter";
CM_ SG_ 544 PTSDriveStyleSts "PTS_TOC Actived = [1]";
CM_ SG_ 544 PTSTorqueOverlayFault "Fault of the PTS torque overlay interface; True = [1]";
CM_ SG_ 544 PTSTorqueOverlayIntActivated "Torque overlay interface has been successfully activated; True = [1]";
CM_ SG_ 544 StrClmTrq "Steering column torque; counterclockwise positive [Nm]";
CM_ SG_ 544 StrClmTrqVD "Steering column torque: valid data [1]";
CM_ SG_ 300 EPS_AsstStat "Electric Power Steering Assistance Status";
CM_ SG_ 300 EPS_Curr "Electric power steering current";
CM_ SG_ 300 EPS_ErrStat "Electric power steering warning display request - specific to sending module";
CM_ SG_ 300 EPS_IntraECUCommFault "EPS Internal ECU-ECU Fault Status, OK = [0], Fault = [1];";
CM_ SG_ 300 EPS_MODE_STAT "EPS mode personalization status";
CM_ SG_ 300 EPS_ModuleVoltage "Electric power steering voltage";
CM_ SG_ 300 EPS_Warn_Disp_Rq "Electric power steering warning display request";
CM_ SG_ 300 EngineFanRequestActivation "Engine fan activation request for cooling; True = [1]";
CM_ SG_ 300 PS_SysType "Power steering system type; EHPS = [0]: EPS = [1]";
CM_ SG_ 463 CodeCheckStsESL "Result of code check";
CM_ SG_ 463 ControlEncodingRspESL "ESL response to BCM MiniCrypt input";
CM_ SG_ 463 ESLFeedbackCmd "ESL status of executing lock/unlock";
CM_ SG_ 463 ESLLockFailSts "Display info on failed lock; Failed = [1]";
CM_ SG_ 463 ESLUnlockFailSts "Display info on failed unlock; Failed = [1]";
CM_ SG_ 463 ESL_ProgrammedSts "ESL programmed with security code; Programmed = [1]";
CM_ SG_ 463 MiniCryptGCodeESL "ESL MiniCrypt code";
CM_ SG_ 320 ABS_BrkEvt "Any ABS brake event";
CM_ SG_ 320 BrkIntrvntn_Actv_AS "Brake intervention by assistance system active";
CM_ SG_ 320 BrkIntrvntn_Actv_ESP "Brake intervention by ESP active";
CM_ SG_ 320 BrkIntrvntn_Enbl "Brake intervention enabled";
CM_ SG_ 320 BrkPdl_Flt "Brake Pedal Fault is active, 1=Faulted";
CM_ SG_ 320 BrkPdl_Stat "Brake pedal state";
CM_ SG_ 320 Brk_Stat "Brake state";
CM_ SG_ 320 Brk_Thermdl "Brake thermal over target";
CM_ SG_ 320 CRC_Brk_Stat "CRC-checksum byte 1 to 7 according to SAE J1850";
CM_ SG_ 320 DTR_CC_Enabled "ACC is enabled; True = [1]";
CM_ SG_ 320 DTR_CC_Engaged "ACC is engaged; True = [1]";
CM_ SG_ 320 ESP_Sys_Stat "ESP system state";
CM_ SG_ 320 EmgBrk_Actv "Emergency braking";
CM_ SG_ 320 FullBrk_Actv "Maximum (hard) braking (ALS controls all wheels)";
CM_ SG_ 320 MC_Brk_Stat "Message counter";
CM_ SG_ 320 REF_VEH_SPEED "Reference vehicle actual speed";
CM_ SG_ 320 RollTestMd_Actv "Roller test bench mode active";
CM_ SG_ 320 SPCR_AS_Off_Rq "Assistance system off request";
CM_ SG_ 268 ASRActive "Traction control is active";
CM_ SG_ 268 Brk_Jrk_Rsp "Brake jerk response; True = [1]";
CM_ SG_ 268 CRC_ENG_RQ_ESC "CRC-checksum byte 1 to 7 according to SAE J1850";
CM_ SG_ 268 DAS_Enbl_Rq "Enable DAS request; True = [1]";
CM_ SG_ 268 DAS_RqActv "DAS request active";
CM_ SG_ 268 EngTrqMax_Rq_ESC "Engine torque requet maximum";
CM_ SG_ 268 EngTrqMin_Rq_ESC "Engine torque requet minimum";
CM_ SG_ 268 EngTrq_Rq_ESC "DUMMY Signal Not Used on EVA";
CM_ SG_ 268 MC_ENG_RQ_ESC "Message counter";
CM_ SG_ 268 PrefillActive "Brake prefill is active - True = [1]";
CM_ SG_ 331 BrkPrss_TMC "Master cylinder pressure";
CM_ SG_ 331 CRC_ESP_A3 "CRC-checksum byte 1 to 7 according to SAE J1850";
CM_ SG_ 331 HSA_BrkPrss "Hill start assist brake pressure";
CM_ SG_ 331 MC_ESP_A3 "Message counter";
CM_ SG_ 331 PTS_Brk_Rq_RspSts "Brake request response status by ESC for park stop & release";
CM_ SG_ 332 MC_VEH_DYN_STAT "Message counter";
CM_ SG_ 332 VehAccel_X "Vehicle longitudinal acceleration (+ means forward)";
CM_ SG_ 332 VehAccel_X_Offset "Offset of vehicle longitudinal acceleration (+ means forward)";
CM_ SG_ 332 VehAccel_Y "Vehicle lateral acceleration (+ means left, specific to center of gravity, offset-corrected )";
CM_ SG_ 332 VehAccel_Y_Offset "Offset of vehicle lateral acceleration (+ means left)";
CM_ SG_ 332 VehYawRate_Offset "Offset of vehicle yaw rate unfiltered/unadjusted (+ means left)";
CM_ SG_ 332 VehYawRate_Raw "Vehicle yaw rate unfiltered/unadjusted (+ means left)";
CM_ SG_ 292 WhlPlsCnt_FL "Wheel pulse counter front left (96 per rotation)";
CM_ SG_ 292 WhlPlsCnt_FR "Wheel pulse counter front right (96 per rotation)";
CM_ SG_ 292 WhlPlsCnt_RL "Wheel pulse counter rear left (96 per rotation)";
CM_ SG_ 292 WhlPlsCnt_RR "Wheel pulse counter rear right (96 per rotation)";
CM_ SG_ 344 WhlDir_FL_Stat "Direction of rotation of front left wheel";
CM_ SG_ 344 WhlDir_FR_Stat "Direction of rotation of front right wheel";
CM_ SG_ 344 WhlDir_RL_Stat "Direction of rotation of rear left wheel";
CM_ SG_ 344 WhlDir_RR_Stat "Direction of rotation of rear right wheel";
CM_ SG_ 344 WhlRPM_FL "Wheel rpm front left";
CM_ SG_ 344 WhlRPM_FR "Wheel rpm front right";
CM_ SG_ 344 WhlRPM_RL "Wheel rpm rear left";
CM_ SG_ 344 WhlRPM_RR "Wheel rpm rear right";
CM_ SG_ 284 BrkTrq "Actual brake torque";
CM_ SG_ 284 BrkTrq_D "Brake torque requested by driver";
CM_ SG_ 284 CRC_VEH_SPEED "CRC-checksum byte 1 to 7 according to SAE J1850";
CM_ SG_ 284 MC_VEH_SPEED "Message counter";
CM_ SG_ 284 VEH_SPEED "Vehicle speed";
CM_ SG_ 284 VehSpSts "Vehicle is stopped status signal";
CM_ SG_ 270 AHH_Status "AHH status";
CM_ SG_ 270 CRC_10Eh "CRC-checksum byte 1 to 7 according to SAE J1850";
CM_ SG_ 270 MC_10Eh "Message counter";
CM_ SG_ 270 WhlTrqAct_Rq_AS "Wheel torque request active; True = [1]";
CM_ SG_ 270 WhlTrqMax_Rq_ESC "Wheel torque request maximum";
CM_ SG_ 270 WhlTrqMin_Rq_ESC "Wheel torque request minimum";
CM_ SG_ 270 WhlTrq_Rq_As "Wheel torque request";
CM_ SG_ 270 WhlTrq_Rq_ESC "Wheel torque request";
CM_ SG_ 736 ABS_IndLmp_On_Rq "ABS indication lamp on request";
CM_ SG_ 736 BrkIndLmp_On_Rq_ESC "Brake indication lamp (red) on request";
CM_ SG_ 736 ESC_CtrlLmp_Info "ESC control lamp information";
CM_ SG_ 736 ESP_Off_IndLmp_On_Rq "ESP-OFF indication lamp on request";
CM_ SG_ 736 HSA_EN "Hill Start Assist enabled (1=enabled)";
CM_ SG_ 736 LT_DIST "Distance Traveled by Left Wheel";
CM_ SG_ 736 RT_DIST "Distance Traveled by Right Wheel";
CM_ SG_ 736 YRS_DataRq "Request from ESC for YRS information";
CM_ SG_ 737 ESCSysEmsMlfAtv "ESC emissions related malfunction active";
CM_ SG_ 737 MIL_OnRq_ESC "MIL on request from the ESC";
CM_ SG_ 682 BrakeSysStatePrim "Brake System State from Primary actuator";
CM_ SG_ 682 CRC_ESP_B5 "CRC-checksum byte 1 to 7 according to SAE J1850";
CM_ SG_ 682 ESC_BrakeState "ESC Brake State";
CM_ SG_ 682 HoldSufficientStatus "1 – Indicates ESC has sufficient torque, for RHSC to command release of park brake or move out of park. ";
CM_ SG_ 682 MC_ESP_B5 "Message counter";
CM_ SG_ 682 SDS_Engaged_State_ESC "SDS Engaged Status";
CM_ SG_ 682 qTargetExternal "Target volume flow speed of the brake system to be applied by iBooster for EBR.";
CM_ SG_ 682 qTargetExternal_Active "Activates the external brake volume flow request when equal to 1";
CM_ SG_ 840 FailSafeError "Fail safe error";
CM_ SG_ 1016 EC_BU_CBC1A "Backup for CBC ecu configuration 1A";
CM_ SG_ 1016 EC_BU_CBC1B "Backup for CBC ecu configuration 1B";
CM_ SG_ 1016 EC_BU_CBC2 "Backup for CBC ecu configuration 2";
CM_ SG_ 1016 EC_BU_ECUCfg1_Stat "Backup for ECU Configuration messages status 1";
CM_ SG_ 989 EC_BU_Cluster3A "Backup for Instrument cluster ecu configuration 3A";
CM_ SG_ 989 EC_BU_Cluster3B "Backup for Instrument cluster ecu configuration 3B";
CM_ SG_ 989 EC_BU_Cluster4 "Backup for Instrument cluster ecu configuration 4";
CM_ SG_ 989 EC_BU_ECUCfg10_Stat "Backup for ECU Configuration messages status 10";
CM_ SG_ 988 EC_BU_CBC10A "Backup for CBC ecu configuration 10A";
CM_ SG_ 988 EC_BU_CBC10B "Backup for CBC ecu configuration 10B";
CM_ SG_ 988 EC_BU_CBC11 "Backup for CBC ecu configuration 11";
CM_ SG_ 988 EC_BU_ECUCfg11_Stat "Backup for ECU Configuration messages status 11";
CM_ SG_ 987 EC_BU_Cluster5A "Backup for Instrument cluster ecu configuration 5A";
CM_ SG_ 987 EC_BU_Cluster5B "Backup for Instrument cluster ecu configuration 5B";
CM_ SG_ 987 EC_BU_Cluster5C "Backup for Instrument cluster ecu configuration 5C";
CM_ SG_ 987 EC_BU_ECUCfg12_Stat "Backup for ECU Configuration messages status 12";
CM_ SG_ 986 EC_BU_CBC13A "Backup for CBC ecu configuration 13A";
CM_ SG_ 986 EC_BU_CBC13B "Backup for CBC ecu configuration 13B";
CM_ SG_ 986 EC_BU_ECUCfg13_Stat "Backup for ECU Configuration messages status 13";
CM_ SG_ 985 EC_BU_CBC14A "Backup for CBC ecu configuration 14A";
CM_ SG_ 985 EC_BU_CBC14B "Backup for CBC ecu configuration 14B";
CM_ SG_ 985 EC_BU_ECUCfg14_Stat "Backup for ECU Configuration messages status 14";
CM_ SG_ 707 EC_BU_CBC15A "Backup for CBC ecu configuration 15A";
CM_ SG_ 707 EC_BU_CBC15B "Backup for CBC ecu configuration 15B";
CM_ SG_ 707 EC_BU_ECUCfg15_Stat "Backup for ECU Configuration messages status 15";
CM_ SG_ 707 EC_BU_Suspension "Backup for Suspension ecu configuration";
CM_ SG_ 714 EC_BU_AudTel3A "Backup for audio and telematics ecu configuration 3A";
CM_ SG_ 714 EC_BU_AudTel3B "Backup for audio and telematics ecu configuration 3B";
CM_ SG_ 714 EC_BU_ECUCfg16_Stat "Backup for ECU Configuration messages status 16";
CM_ SG_ 715 EC_BU_ECUCfg17_Stat "Backup for ECU Configuration messages status 17";
CM_ SG_ 715 EC_BU_PTS "Backup for park assist ecu configuration";
CM_ SG_ 1017 EC_BU_CBC3A "Backup for CBC ecu configuration 3A";
CM_ SG_ 1017 EC_BU_CBC3B "Backup for CBC ecu configuration 3B";
CM_ SG_ 1017 EC_BU_CBC4 "Backup for CBC ecu configuration 4";
CM_ SG_ 1017 EC_BU_ECUCfg2_Stat "Backup for ECU Configuration messages status 2";
CM_ SG_ 1018 EC_BU_AudTel1A "Backup for Audio and telematics ecu configuration 1A";
CM_ SG_ 1018 EC_BU_AudTel1B "Backup for Audio and telematics ecu configuration 1B";
CM_ SG_ 1018 EC_BU_AudTel2 "Backup for Audio and telematics ecu configuration 2";
CM_ SG_ 1018 EC_BU_ECUCfg3_Stat "Backup for ECU Configuration messages status 3";
CM_ SG_ 1019 EC_BU_Cluster1A "Backup for Instrument cluster ecu configuration 1A";
CM_ SG_ 1019 EC_BU_Cluster1B "Backup for Instrument cluster ecu configuration 1B";
CM_ SG_ 1019 EC_BU_Cluster2 "Backup for Instrument cluster ecu configuration 2";
CM_ SG_ 1019 EC_BU_ECUCfg4_Stat "Backup for ECU Configuration messages status 4";
CM_ SG_ 1020 EC_BU_Doors "Backup for Doors ecu configuration";
CM_ SG_ 1020 EC_BU_ECUCfg5_Stat "Backup for ECU Configuration messages status 5";
CM_ SG_ 1020 EC_BU_Memory "Backup for Memory ecu configuration";
CM_ SG_ 1020 EC_BU_WirelessA "Backup for Wireless ecu configurationA";
CM_ SG_ 1020 EC_BU_WirelessB "Backup for Wireless ecu configurationB";
CM_ SG_ 1021 EC_BU_BrakesA "Backup for Brake system ecu configurationA";
CM_ SG_ 1021 EC_BU_BrakesB "Backup for Brake system ecu configurationB";
CM_ SG_ 1021 EC_BU_ECUCfg6_Stat "Backup for ECU Configuration messages status 6";
CM_ SG_ 1021 EC_BU_Powertrain "Backup for Powertrain ecu configuration";
CM_ SG_ 1021 EC_BU_Safety "Backup for Safety ecu configuration";
CM_ SG_ 1021 EC_BU_Steering "Backup for steering ecu configuration";
CM_ SG_ 1022 EC_BU_CBC5A "Backup for CBC ecu configuration 5A";
CM_ SG_ 1022 EC_BU_CBC5B "Backup for CBC ecu configuration 5B";
CM_ SG_ 1022 EC_BU_CBC6 "Backup for CBC ecu configuration 6";
CM_ SG_ 1022 EC_BU_ECUCfg7_Stat "Backup for ECU Configuration messages status 7";
CM_ SG_ 1023 EC_BU_CBC7A "Backup for CBC ecu configuration 7A";
CM_ SG_ 1023 EC_BU_CBC7B "Backup for CBC ecu configuration 7B";
CM_ SG_ 1023 EC_BU_CBC8 "Backup for CBC ecu configuration 8";
CM_ SG_ 1023 EC_BU_ECUCfg8_Stat "Backup for ECU Configuration messages status 8";
CM_ SG_ 991 EC_BU_CBC9A1 "Backup for CBC configuration 9A1";
CM_ SG_ 991 EC_BU_CBC9A2 "Backup for CBC configuration 9A2";
CM_ SG_ 991 EC_BU_CBC9B "Backup for CBC configuration 9B";
CM_ SG_ 991 EC_BU_ECUCfg9_Stat "Backup for ECU Configuration messages status 9";
CM_ SG_ 991 EC_BU_ITM "Backup for ITM ecu configuration";
CM_ SG_ 1008 EC_CBC1A "CBC ecu configuration 1A";
CM_ SG_ 1008 EC_CBC1B "CBC ecu configuration 1B";
CM_ SG_ 1008 EC_CBC2 "CBC ecu configuration 2";
CM_ SG_ 1008 EC_ECUCfg1_Stat "ECU Configuration messages status 1";
BA_DEF_ BO_  "App-Botschaft" ENUM  "nein","ja";
BA_DEF_ BO_  "CanMsgMinLen" INT 0 8;
BA_DEF_ BO_  "DiagRequest" ENUM  "nein","ja";
BA_DEF_ BO_  "DiagResponse" ENUM  "nein","ja";
BA_DEF_ BO_  "DiagState" ENUM  "nein","ja";
BA_DEF_ BO_  "GenMsgCycleTime" INT 0 65535;
BA_DEF_ BO_  "GenMsgCycleTimeActive" INT 0 65535;
BA_DEF_ BO_  "GenMsgDelayTime" INT 0 65535;
BA_DEF_ BO_  "GenMsgNrOfRepetitions" INT 0 65535;
BA_DEF_ BO_  "GenMsgSendType" ENUM  "cyclicX","spontanX","cyclicIfActiveX","spontanWithDelay","cyclicAndSpontanX","cyclicAndSpontanWithDelay","spontanWithRepitition","cyclicIfActiveAndSpontanWD","cyclicIfActiveFast","cyclicWithRepeatOnDemand","none";
BA_DEF_ BO_  "GenMsgStartDelayTime" INT 0 65535;
BA_DEF_ BO_  "GenMsgStartValue" STRING ;
BA_DEF_ BO_  "NWM-Botschaft" ENUM  "nein","ja";
BA_DEF_ BO_  "TpTxIndex" INT 0 99;
BA_DEF_ SG_  "FlexKomComment" STRING ;
BA_DEF_ SG_  "FlexKomIsMotorola" ENUM  "nein","ja";
BA_DEF_ SG_  "FlexKomSID" INT 0 2147483647;
BA_DEF_ SG_  "FlexKomSigLaenge" INT 0 64;
BA_DEF_ SG_  "FlexKomSigName" STRING ;
BA_DEF_ SG_  "FlexKomSigStartPos" INT 0 63;
BA_DEF_ SG_  "FlexKomSigStartValue" STRING ;
BA_DEF_ SG_  "GenSigCycleTime" INT 0 65535;
BA_DEF_ SG_  "GenSigCycleTimeActive" INT 0 65535;
BA_DEF_ SG_  "GenSigSendType" ENUM  "cyclicX","spontanX","cyclicIfActiveX","spontanWithDelay","cyclicAndSpontanX","cyclicAndSpontanWithDelay","spontanWithRepitition","cyclicIfActiveAndSpontanWD","cyclicIfActiveFast","cyclicWithRepeatOnDemand","none";
BA_DEF_ SG_  "GenSigSNA" STRING ;
BA_DEF_ SG_  "GenSigStartValue" HEX 0 2147483648;
BA_DEF_ SG_  "GenSigTimeout_CBC" INT 0 65535;
BA_DEF_ SG_  "GenSigTimeout_EPS" INT 0 65535;
BA_DEF_ SG_  "GenSigTimeout_ESC" INT 0 65535;
BA_DEF_ SG_  "GenSigTimeout_ESL" INT 0 65535;
BA_DEF_ SG_  "GenSigTimeout_RHSC2" INT 0 65535;
BA_DEF_ SG_  "GenSigTimeout_ETM" INT 0 65535;
BA_DEF_ SG_  "GenSigTimeout_HaLF" INT 0 65535;
BA_DEF_ SG_  "GenSigTimeout_IC" INT 0 65535;
BA_DEF_ SG_  "GenSigTimeout_OCM" INT 0 65535;
BA_DEF_ SG_  "GenSigTimeout_ORC" INT 0 65535;
BA_DEF_ SG_  "GenSigTimeout_PTS" INT 0 65535;
BA_DEF_ SG_  "GenSigTimeout_RF_HUB" INT 0 65535;
BA_DEF_ SG_  "GenSigTimeout_SCCM" INT 0 65535;
BA_DEF_ SG_  "RID" STRING ;
BA_DEF_DEF_  "App-Botschaft" "nein";
BA_DEF_DEF_  "CanMsgMinLen" 0;
BA_DEF_DEF_  "DiagRequest" "nein";
BA_DEF_DEF_  "DiagResponse" "nein";
BA_DEF_DEF_  "DiagState" "nein";
BA_DEF_DEF_  "GenMsgCycleTime" 0;
BA_DEF_DEF_  "GenMsgCycleTimeActive" 0;
BA_DEF_DEF_  "GenMsgDelayTime" 0;
BA_DEF_DEF_  "GenMsgNrOfRepetitions" 0;
BA_DEF_DEF_  "GenMsgSendType" "cyclicX";
BA_DEF_DEF_  "GenMsgStartDelayTime" 0;
BA_DEF_DEF_  "GenMsgStartValue" "";
BA_DEF_DEF_  "NWM-Botschaft" "nein";
BA_DEF_DEF_  "TpTxIndex" 0;
BA_DEF_DEF_  "FlexKomComment" "";
BA_DEF_DEF_  "FlexKomIsMotorola" "nein";
BA_DEF_DEF_  "FlexKomSID" 0;
BA_DEF_DEF_  "FlexKomSigLaenge" 0;
BA_DEF_DEF_  "FlexKomSigName" "";
BA_DEF_DEF_  "FlexKomSigStartPos" 0;
BA_DEF_DEF_  "FlexKomSigStartValue" "";
BA_DEF_DEF_  "GenSigCycleTime" 0;
BA_DEF_DEF_  "GenSigCycleTimeActive" 0;
BA_DEF_DEF_  "GenSigSendType" "cyclicX";
BA_DEF_DEF_  "GenSigSNA" "";
BA_DEF_DEF_  "GenSigStartValue" 0;
BA_DEF_DEF_  "GenSigTimeout_CBC" 0;
BA_DEF_DEF_  "GenSigTimeout_EPS" 0;
BA_DEF_DEF_  "GenSigTimeout_ESC" 0;
BA_DEF_DEF_  "GenSigTimeout_ESL" 0;
BA_DEF_DEF_  "GenSigTimeout_RHSC2" 0;
BA_DEF_DEF_  "GenSigTimeout_ETM" 0;
BA_DEF_DEF_  "GenSigTimeout_HaLF" 0;
BA_DEF_DEF_  "GenSigTimeout_IC" 0;
BA_DEF_DEF_  "GenSigTimeout_OCM" 0;
BA_DEF_DEF_  "GenSigTimeout_ORC" 0;
BA_DEF_DEF_  "GenSigTimeout_PTS" 0;
BA_DEF_DEF_  "GenSigTimeout_RF_HUB" 0;
BA_DEF_DEF_  "GenSigTimeout_SCCM" 0;
BA_DEF_DEF_  "RID" "";
BA_ "App-Botschaft" BO_ 1468 1;
BA_ "GenMsgDelayTime" BO_ 1468 20;
BA_ "GenMsgNrOfRepetitions" BO_ 1468 2;
BA_ "GenMsgSendType" BO_ 1468 1;
BA_ "GenMsgStartValue" BO_ 1468 "0000000000000000h";
BA_ "App-Botschaft" BO_ 1409 1;
BA_ "GenMsgDelayTime" BO_ 1409 20;
BA_ "GenMsgNrOfRepetitions" BO_ 1409 2;
BA_ "GenMsgSendType" BO_ 1409 1;
BA_ "GenMsgStartValue" BO_ 1409 "0000000000000000h";
BA_ "App-Botschaft" BO_ 1427 1;
BA_ "GenMsgDelayTime" BO_ 1427 20;
BA_ "GenMsgNrOfRepetitions" BO_ 1427 2;
BA_ "GenMsgSendType" BO_ 1427 1;
BA_ "GenMsgStartValue" BO_ 1427 "0000000000000000h";
BA_ "App-Botschaft" BO_ 1467 1;
BA_ "GenMsgDelayTime" BO_ 1467 20;
BA_ "GenMsgNrOfRepetitions" BO_ 1467 2;
BA_ "GenMsgSendType" BO_ 1467 1;
BA_ "GenMsgStartValue" BO_ 1467 "0000000000000000h";
BA_ "App-Botschaft" BO_ 1464 1;
BA_ "GenMsgDelayTime" BO_ 1464 20;
BA_ "GenMsgNrOfRepetitions" BO_ 1464 2;
BA_ "GenMsgSendType" BO_ 1464 1;
BA_ "GenMsgStartValue" BO_ 1464 "0000000000000000h";
BA_ "App-Botschaft" BO_ 1434 1;
BA_ "GenMsgDelayTime" BO_ 1434 20;
BA_ "GenMsgNrOfRepetitions" BO_ 1434 2;
BA_ "GenMsgSendType" BO_ 1434 1;
BA_ "GenMsgStartValue" BO_ 1434 "0000000000000000h";
BA_ "App-Botschaft" BO_ 1416 1;
BA_ "GenMsgDelayTime" BO_ 1416 20;
BA_ "GenMsgNrOfRepetitions" BO_ 1416 2;
BA_ "GenMsgSendType" BO_ 1416 1;
BA_ "GenMsgStartValue" BO_ 1416 "0000000000000000h";
BA_ "App-Botschaft" BO_ 1417 1;
BA_ "GenMsgDelayTime" BO_ 1417 20;
BA_ "GenMsgNrOfRepetitions" BO_ 1417 2;
BA_ "GenMsgSendType" BO_ 1417 1;
BA_ "GenMsgStartValue" BO_ 1417 "0000000000000000h";
BA_ "App-Botschaft" BO_ 1466 1;
BA_ "GenMsgDelayTime" BO_ 1466 20;
BA_ "GenMsgNrOfRepetitions" BO_ 1466 2;
BA_ "GenMsgSendType" BO_ 1466 1;
BA_ "GenMsgStartValue" BO_ 1466 "0000000000000000h";
BA_ "App-Botschaft" BO_ 1444 1;
BA_ "GenMsgDelayTime" BO_ 1444 20;
BA_ "GenMsgNrOfRepetitions" BO_ 1444 2;
BA_ "GenMsgSendType" BO_ 1444 1;
BA_ "GenMsgStartValue" BO_ 1444 "0000000000000000h";
BA_ "App-Botschaft" BO_ 1410 1;
BA_ "GenMsgDelayTime" BO_ 1410 20;
BA_ "GenMsgNrOfRepetitions" BO_ 1410 2;
BA_ "GenMsgSendType" BO_ 1410 1;
BA_ "GenMsgStartValue" BO_ 1410 "0000000000000000h";
BA_ "App-Botschaft" BO_ 1438 1;
BA_ "GenMsgDelayTime" BO_ 1438 20;
BA_ "GenMsgNrOfRepetitions" BO_ 1438 2;
BA_ "GenMsgSendType" BO_ 1438 1;
BA_ "GenMsgStartValue" BO_ 1438 "0000000000000000h";
BA_ "App-Botschaft" BO_ 1412 1;
BA_ "GenMsgDelayTime" BO_ 1412 20;
BA_ "GenMsgNrOfRepetitions" BO_ 1412 2;
BA_ "GenMsgSendType" BO_ 1412 1;
BA_ "GenMsgStartValue" BO_ 1412 "0000000000000000h";
BA_ "App-Botschaft" BO_ 1442 1;
BA_ "GenMsgDelayTime" BO_ 1442 20;
BA_ "GenMsgNrOfRepetitions" BO_ 1442 2;
BA_ "GenMsgSendType" BO_ 1442 1;
BA_ "GenMsgStartValue" BO_ 1442 "0000000000000000h";
BA_ "App-Botschaft" BO_ 1408 1;
BA_ "GenMsgDelayTime" BO_ 1408 20;
BA_ "GenMsgNrOfRepetitions" BO_ 1408 2;
BA_ "GenMsgSendType" BO_ 1408 1;
BA_ "GenMsgStartValue" BO_ 1408 "0000000000000000h";
BA_ "App-Botschaft" BO_ 1443 1;
BA_ "GenMsgDelayTime" BO_ 1443 20;
BA_ "GenMsgNrOfRepetitions" BO_ 1443 2;
BA_ "GenMsgSendType" BO_ 1443 1;
BA_ "GenMsgStartValue" BO_ 1443 "0000000000000000h";
BA_ "GenMsgCycleTime" BO_ 993 100;
BA_ "GenMsgDelayTime" BO_ 993 20;
BA_ "GenMsgNrOfRepetitions" BO_ 993 2;
BA_ "GenMsgStartValue" BO_ 993 "FFEFE7E71F0000h";
BA_ "GenMsgCycleTime" BO_ 770 250;
BA_ "GenMsgDelayTime" BO_ 770 20;
BA_ "GenMsgNrOfRepetitions" BO_ 770 2;
BA_ "GenMsgStartValue" BO_ 770 "00000000000000FFh";
BA_ "GenMsgCycleTime" BO_ 669 40;
BA_ "GenMsgDelayTime" BO_ 669 20;
BA_ "GenMsgNrOfRepetitions" BO_ 669 2;
BA_ "GenMsgStartValue" BO_ 669 "0000FFh";
BA_ "GenMsgCycleTime" BO_ 544 10;
BA_ "GenMsgDelayTime" BO_ 544 20;
BA_ "GenMsgNrOfRepetitions" BO_ 544 2;
BA_ "GenMsgStartValue" BO_ 544 "07FF07FF040000FFh";
BA_ "GenMsgCycleTime" BO_ 300 100;
BA_ "GenMsgDelayTime" BO_ 300 20;
BA_ "GenMsgNrOfRepetitions" BO_ 300 2;
BA_ "GenMsgStartValue" BO_ 300 "0200FFFF00000000h";
BA_ "GenMsgDelayTime" BO_ 463 20;
BA_ "GenMsgNrOfRepetitions" BO_ 463 2;
BA_ "GenMsgSendType" BO_ 463 1;
BA_ "GenMsgStartValue" BO_ 463 "0000000000h";
BA_ "GenMsgCycleTime" BO_ 320 20;
BA_ "GenMsgDelayTime" BO_ 320 20;
BA_ "GenMsgNrOfRepetitions" BO_ 320 2;
BA_ "GenMsgStartValue" BO_ 320 "0F3400C003FF00FFh";
BA_ "GenMsgCycleTime" BO_ 268 20;
BA_ "GenMsgDelayTime" BO_ 268 20;
BA_ "GenMsgNrOfRepetitions" BO_ 268 2;
BA_ "GenMsgStartValue" BO_ 268 "00000000FF0000FFh";
BA_ "GenMsgCycleTime" BO_ 331 20;
BA_ "GenMsgDelayTime" BO_ 331 20;
BA_ "GenMsgNrOfRepetitions" BO_ 331 2;
BA_ "GenMsgStartValue" BO_ 331 "0000FFFF00FF00FFh";
BA_ "GenMsgCycleTime" BO_ 332 20;
BA_ "GenMsgDelayTime" BO_ 332 20;
BA_ "GenMsgNrOfRepetitions" BO_ 332 2;
BA_ "GenMsgStartValue" BO_ 332 "FFFFFFFFFFFF00FFh";
BA_ "GenMsgCycleTime" BO_ 292 20;
BA_ "GenMsgDelayTime" BO_ 292 20;
BA_ "GenMsgNrOfRepetitions" BO_ 292 2;
BA_ "GenMsgStartValue" BO_ 292 "0000000000FFFFFFh";
BA_ "GenMsgCycleTime" BO_ 344 20;
BA_ "GenMsgDelayTime" BO_ 344 20;
BA_ "GenMsgNrOfRepetitions" BO_ 344 2;
BA_ "GenMsgStartValue" BO_ 344 "FFFFFFFFFFFFFFFFh";
BA_ "GenMsgCycleTime" BO_ 284 20;
BA_ "GenMsgDelayTime" BO_ 284 20;
BA_ "GenMsgNrOfRepetitions" BO_ 284 2;
BA_ "GenMsgStartValue" BO_ 284 "0FFF0FFFFFFF00FFh";
BA_ "GenMsgCycleTime" BO_ 270 20;
BA_ "GenMsgDelayTime" BO_ 270 20;
BA_ "GenMsgNrOfRepetitions" BO_ 270 2;
BA_ "GenMsgStartValue" BO_ 270 "00000000000000FFh";
BA_ "GenMsgCycleTime" BO_ 736 50;
BA_ "GenMsgDelayTime" BO_ 736 20;
BA_ "GenMsgNrOfRepetitions" BO_ 736 2;
BA_ "GenMsgStartValue" BO_ 736 "FFFFFFFF0000003Fh";
BA_ "GenMsgCycleTime" BO_ 737 100;
BA_ "GenMsgDelayTime" BO_ 737 20;
BA_ "GenMsgNrOfRepetitions" BO_ 737 2;
BA_ "GenMsgStartValue" BO_ 737 "C1FE01FE00000000h";
BA_ "GenMsgCycleTime" BO_ 682 20;
BA_ "GenMsgDelayTime" BO_ 682 20;
BA_ "GenMsgNrOfRepetitions" BO_ 682 2;
BA_ "GenMsgStartValue" BO_ 682 "FFFF8000000000FFh";
BA_ "GenMsgDelayTime" BO_ 840 20;
BA_ "GenMsgNrOfRepetitions" BO_ 840 2;
BA_ "GenMsgSendType" BO_ 840 1;
BA_ "GenMsgStartValue" BO_ 840 "0000000000000000h";
BA_ "GenMsgDelayTime" BO_ 1016 20;
BA_ "GenMsgNrOfRepetitions" BO_ 1016 2;
BA_ "GenMsgSendType" BO_ 1016 1;
BA_ "GenMsgStartValue" BO_ 1016 "0300000000000000h";
BA_ "GenMsgDelayTime" BO_ 989 20;
BA_ "GenMsgNrOfRepetitions" BO_ 989 2;
BA_ "GenMsgSendType" BO_ 989 1;
BA_ "GenMsgStartValue" BO_ 989 "0300000000000000h";
BA_ "GenMsgDelayTime" BO_ 988 20;
BA_ "GenMsgNrOfRepetitions" BO_ 988 2;
BA_ "GenMsgSendType" BO_ 988 1;
BA_ "GenMsgStartValue" BO_ 988 "0300000000000000h";
BA_ "GenMsgDelayTime" BO_ 987 20;
BA_ "GenMsgNrOfRepetitions" BO_ 987 2;
BA_ "GenMsgSendType" BO_ 987 1;
BA_ "GenMsgStartValue" BO_ 987 "0300000000000000h";
BA_ "GenMsgDelayTime" BO_ 986 20;
BA_ "GenMsgNrOfRepetitions" BO_ 986 2;
BA_ "GenMsgSendType" BO_ 986 1;
BA_ "GenMsgStartValue" BO_ 986 "0300000000000000h";
BA_ "GenMsgDelayTime" BO_ 985 20;
BA_ "GenMsgNrOfRepetitions" BO_ 985 2;
BA_ "GenMsgSendType" BO_ 985 1;
BA_ "GenMsgStartValue" BO_ 985 "0300000000000000h";
BA_ "GenMsgDelayTime" BO_ 707 20;
BA_ "GenMsgNrOfRepetitions" BO_ 707 2;
BA_ "GenMsgSendType" BO_ 707 1;
BA_ "GenMsgStartValue" BO_ 707 "0300000000000000h";
BA_ "GenMsgDelayTime" BO_ 714 20;
BA_ "GenMsgNrOfRepetitions" BO_ 714 2;
BA_ "GenMsgSendType" BO_ 714 1;
BA_ "GenMsgStartValue" BO_ 714 "0300000000000000h";
BA_ "GenMsgDelayTime" BO_ 715 20;
BA_ "GenMsgNrOfRepetitions" BO_ 715 2;
BA_ "GenMsgSendType" BO_ 715 1;
BA_ "GenMsgStartValue" BO_ 715 "0300000000000000h";
BA_ "GenMsgDelayTime" BO_ 1017 20;
BA_ "GenMsgNrOfRepetitions" BO_ 1017 2;
BA_ "GenMsgSendType" BO_ 1017 1;
BA_ "GenMsgStartValue" BO_ 1017 "0300000000000000h";
BA_ "GenMsgDelayTime" BO_ 1018 20;
BA_ "GenMsgNrOfRepetitions" BO_ 1018 2;
BA_ "GenMsgSendType" BO_ 1018 1;
BA_ "GenMsgStartValue" BO_ 1018 "0300000000000000h";
BA_ "GenMsgDelayTime" BO_ 1019 20;
BA_ "GenMsgNrOfRepetitions" BO_ 1019 2;
BA_ "GenMsgSendType" BO_ 1019 1;
BA_ "GenMsgStartValue" BO_ 1019 "0300000000000000h";
BA_ "GenMsgDelayTime" BO_ 1020 20;
BA_ "GenMsgNrOfRepetitions" BO_ 1020 2;
BA_ "GenMsgSendType" BO_ 1020 1;
BA_ "GenMsgStartValue" BO_ 1020 "0300000000000000h";
BA_ "GenMsgDelayTime" BO_ 1021 20;
BA_ "GenMsgNrOfRepetitions" BO_ 1021 2;
BA_ "GenMsgSendType" BO_ 1021 1;
BA_ "GenMsgStartValue" BO_ 1021 "0300000000000000h";
BA_ "GenMsgDelayTime" BO_ 1022 20;
BA_ "GenMsgNrOfRepetitions" BO_ 1022 2;
BA_ "GenMsgSendType" BO_ 1022 1;
BA_ "GenMsgStartValue" BO_ 1022 "0300000000000000h";
BA_ "GenMsgDelayTime" BO_ 1023 20;
BA_ "GenMsgNrOfRepetitions" BO_ 1023 2;
BA_ "GenMsgSendType" BO_ 1023 1;
BA_ "GenMsgStartValue" BO_ 1023 "0300000000000000h";
BA_ "GenMsgDelayTime" BO_ 991 20;
BA_ "GenMsgNrOfRepetitions" BO_ 991 2;
BA_ "GenMsgSendType" BO_ 991 1;
BA_ "GenMsgStartValue" BO_ 991 "0300000000000000h";
BA_ "GenMsgCycleTime" BO_ 1008 2000;
BA_ "GenMsgDelayTime" BO_ 1008 20;
BA_ "GenMsgNrOfRepetitions" BO_ 1008 2;
BA_ "GenMsgStartDelayTime" BO_ 1008 140;
BA_ "GenMsgStartValue" BO_ 1008 "0300000000000000h";
BA_ "FlexKomComment" SG_ 1468 ECU_APPL_BSMO "ECU to External Application";
BA_ "FlexKomIsMotorola" SG_ 1468 ECU_APPL_BSMO 1;
BA_ "FlexKomSID" SG_ 1468 ECU_APPL_BSMO 2283;
BA_ "FlexKomSigLaenge" SG_ 1468 ECU_APPL_BSMO 64;
BA_ "FlexKomSigName" SG_ 1468 ECU_APPL_BSMO "ECU_APPL_BSMO";
BA_ "FlexKomSigStartPos" SG_ 1468 ECU_APPL_BSMO 7;
BA_ "FlexKomSigStartValue" SG_ 1468 ECU_APPL_BSMO "0000000000000000h";
BA_ "GenSigSendType" SG_ 1468 ECU_APPL_BSMO 1;
BA_ "GenSigSNA" SG_ 1468 ECU_APPL_BSMO "0h";
BA_ "FlexKomComment" SG_ 1409 ECU_APPL_CBC "ECU to External Application";
BA_ "FlexKomIsMotorola" SG_ 1409 ECU_APPL_CBC 1;
BA_ "FlexKomSID" SG_ 1409 ECU_APPL_CBC 344;
BA_ "FlexKomSigLaenge" SG_ 1409 ECU_APPL_CBC 64;
BA_ "FlexKomSigName" SG_ 1409 ECU_APPL_CBC "ECU_APPL_CBC";
BA_ "FlexKomSigStartPos" SG_ 1409 ECU_APPL_CBC 7;
BA_ "FlexKomSigStartValue" SG_ 1409 ECU_APPL_CBC "0000000000000000h";
BA_ "GenSigSendType" SG_ 1409 ECU_APPL_CBC 1;
BA_ "GenSigSNA" SG_ 1409 ECU_APPL_CBC "0h";
BA_ "FlexKomComment" SG_ 1427 ECU_APPL_DASM "ECU to External Application";
BA_ "FlexKomIsMotorola" SG_ 1427 ECU_APPL_DASM 1;
BA_ "FlexKomSID" SG_ 1427 ECU_APPL_DASM 364;
BA_ "FlexKomSigLaenge" SG_ 1427 ECU_APPL_DASM 64;
BA_ "FlexKomSigName" SG_ 1427 ECU_APPL_DASM "ECU_APPL_DASM";
BA_ "FlexKomSigStartPos" SG_ 1427 ECU_APPL_DASM 7;
BA_ "FlexKomSigStartValue" SG_ 1427 ECU_APPL_DASM "0000000000000000h";
BA_ "GenSigSendType" SG_ 1427 ECU_APPL_DASM 1;
BA_ "GenSigSNA" SG_ 1427 ECU_APPL_DASM "0h";
BA_ "FlexKomComment" SG_ 1467 ECU_APPL_EBCM "ECU to External Application";
BA_ "FlexKomIsMotorola" SG_ 1467 ECU_APPL_EBCM 1;
BA_ "FlexKomSID" SG_ 1467 ECU_APPL_EBCM 2150;
BA_ "FlexKomSigLaenge" SG_ 1467 ECU_APPL_EBCM 64;
BA_ "FlexKomSigName" SG_ 1467 ECU_APPL_EBCM "ECU_APPL_EBCM";
BA_ "FlexKomSigStartPos" SG_ 1467 ECU_APPL_EBCM 7;
BA_ "FlexKomSigStartValue" SG_ 1467 ECU_APPL_EBCM "0000000000000000h";
BA_ "GenSigSendType" SG_ 1467 ECU_APPL_EBCM 1;
BA_ "GenSigSNA" SG_ 1467 ECU_APPL_EBCM "0h";
BA_ "FlexKomComment" SG_ 1464 ECU_APPL_ECM "ECU to External Application";
BA_ "FlexKomIsMotorola" SG_ 1464 ECU_APPL_ECM 1;
BA_ "FlexKomSID" SG_ 1464 ECU_APPL_ECM 352;
BA_ "FlexKomSigLaenge" SG_ 1464 ECU_APPL_ECM 64;
BA_ "FlexKomSigName" SG_ 1464 ECU_APPL_ECM "ECU_APPL_ECM";
BA_ "FlexKomSigStartPos" SG_ 1464 ECU_APPL_ECM 7;
BA_ "FlexKomSigStartValue" SG_ 1464 ECU_APPL_ECM "0000000000000000h";
BA_ "GenSigSendType" SG_ 1464 ECU_APPL_ECM 1;
BA_ "GenSigSNA" SG_ 1464 ECU_APPL_ECM "0h";
BA_ "FlexKomComment" SG_ 1434 ECU_APPL_EPS "ECU to External Application";
BA_ "FlexKomIsMotorola" SG_ 1434 ECU_APPL_EPS 1;
BA_ "FlexKomSID" SG_ 1434 ECU_APPL_EPS 354;
BA_ "FlexKomSigLaenge" SG_ 1434 ECU_APPL_EPS 64;
BA_ "FlexKomSigName" SG_ 1434 ECU_APPL_EPS "ECU_APPL_EPS";
BA_ "FlexKomSigStartPos" SG_ 1434 ECU_APPL_EPS 7;
BA_ "FlexKomSigStartValue" SG_ 1434 ECU_APPL_EPS "0000000000000000h";
BA_ "GenSigSendType" SG_ 1434 ECU_APPL_EPS 1;
BA_ "GenSigSNA" SG_ 1434 ECU_APPL_EPS "0h";
BA_ "FlexKomComment" SG_ 1416 ECU_APPL_ESL "ECU to External Application";
BA_ "FlexKomIsMotorola" SG_ 1416 ECU_APPL_ESL 1;
BA_ "FlexKomSID" SG_ 1416 ECU_APPL_ESL 2341;
BA_ "FlexKomSigLaenge" SG_ 1416 ECU_APPL_ESL 64;
BA_ "FlexKomSigName" SG_ 1416 ECU_APPL_ESL "ECU_APPL_ESL";
BA_ "FlexKomSigStartPos" SG_ 1416 ECU_APPL_ESL 7;
BA_ "FlexKomSigStartValue" SG_ 1416 ECU_APPL_ESL "0000000000000000h";
BA_ "GenSigSendType" SG_ 1416 ECU_APPL_ESL 1;
BA_ "GenSigSNA" SG_ 1416 ECU_APPL_ESL "0h";
BA_ "FlexKomComment" SG_ 1417 ECU_APPL_ESM "ECU to External Application";
BA_ "FlexKomIsMotorola" SG_ 1417 ECU_APPL_ESM 1;
BA_ "FlexKomSID" SG_ 1417 ECU_APPL_ESM 355;
BA_ "FlexKomSigLaenge" SG_ 1417 ECU_APPL_ESM 64;
BA_ "FlexKomSigName" SG_ 1417 ECU_APPL_ESM "ECU_APPL_ESM";
BA_ "FlexKomSigStartPos" SG_ 1417 ECU_APPL_ESM 7;
BA_ "FlexKomSigStartValue" SG_ 1417 ECU_APPL_ESM "0000000000000000h";
BA_ "GenSigSendType" SG_ 1417 ECU_APPL_ESM 1;
BA_ "GenSigSNA" SG_ 1417 ECU_APPL_ESM "0h";
BA_ "RID" SG_ 1417 ECU_APPL_ESM "9610";
BA_ "FlexKomComment" SG_ 1466 ECU_APPL_HCP "ECU to External Application";
BA_ "FlexKomIsMotorola" SG_ 1466 ECU_APPL_HCP 1;
BA_ "FlexKomSID" SG_ 1466 ECU_APPL_HCP 2120;
BA_ "FlexKomSigLaenge" SG_ 1466 ECU_APPL_HCP 64;
BA_ "FlexKomSigName" SG_ 1466 ECU_APPL_HCP "ECU_APPL_HCP";
BA_ "FlexKomSigStartPos" SG_ 1466 ECU_APPL_HCP 7;
BA_ "FlexKomSigStartValue" SG_ 1466 ECU_APPL_HCP "0000000000000000h";
BA_ "GenSigSendType" SG_ 1466 ECU_APPL_HCP 1;
BA_ "GenSigSNA" SG_ 1466 ECU_APPL_HCP "0h";
BA_ "FlexKomComment" SG_ 1444 ECU_APPL_HaLF "ECU to External Application";
BA_ "FlexKomIsMotorola" SG_ 1444 ECU_APPL_HaLF 1;
BA_ "FlexKomSID" SG_ 1444 ECU_APPL_HaLF 1634;
BA_ "FlexKomSigLaenge" SG_ 1444 ECU_APPL_HaLF 64;
BA_ "FlexKomSigName" SG_ 1444 ECU_APPL_HaLF "ECU_APPL_HaLF";
BA_ "FlexKomSigStartPos" SG_ 1444 ECU_APPL_HaLF 7;
BA_ "FlexKomSigStartValue" SG_ 1444 ECU_APPL_HaLF "0000000000000000h";
BA_ "GenSigSendType" SG_ 1444 ECU_APPL_HaLF 1;
BA_ "GenSigSNA" SG_ 1444 ECU_APPL_HaLF "0h";
BA_ "FlexKomComment" SG_ 1410 ECU_APPL_IC "ECU to External Application";
BA_ "FlexKomIsMotorola" SG_ 1410 ECU_APPL_IC 1;
BA_ "FlexKomSID" SG_ 1410 ECU_APPL_IC 361;
BA_ "FlexKomSigLaenge" SG_ 1410 ECU_APPL_IC 64;
BA_ "FlexKomSigName" SG_ 1410 ECU_APPL_IC "ECU_APPL_IC";
BA_ "FlexKomSigStartPos" SG_ 1410 ECU_APPL_IC 7;
BA_ "FlexKomSigStartValue" SG_ 1410 ECU_APPL_IC "0000000000000000h";
BA_ "GenSigSendType" SG_ 1410 ECU_APPL_IC 1;
BA_ "GenSigSNA" SG_ 1410 ECU_APPL_IC "0h";
BA_ "FlexKomComment" SG_ 1438 ECU_APPL_OCM "ECU to External Application";
BA_ "FlexKomIsMotorola" SG_ 1438 ECU_APPL_OCM 1;
BA_ "FlexKomSID" SG_ 1438 ECU_APPL_OCM 1540;
BA_ "FlexKomSigLaenge" SG_ 1438 ECU_APPL_OCM 64;
BA_ "FlexKomSigName" SG_ 1438 ECU_APPL_OCM "ECU_APPL_OCM";
BA_ "FlexKomSigStartPos" SG_ 1438 ECU_APPL_OCM 7;
BA_ "FlexKomSigStartValue" SG_ 1438 ECU_APPL_OCM "0000000000000000h";
BA_ "GenSigSendType" SG_ 1438 ECU_APPL_OCM 1;
BA_ "GenSigSNA" SG_ 1438 ECU_APPL_OCM "0h";
BA_ "FlexKomComment" SG_ 1412 ECU_APPL_ORC "ECU to External Application";
BA_ "FlexKomIsMotorola" SG_ 1412 ECU_APPL_ORC 1;
BA_ "FlexKomSID" SG_ 1412 ECU_APPL_ORC 368;
BA_ "FlexKomSigLaenge" SG_ 1412 ECU_APPL_ORC 64;
BA_ "FlexKomSigName" SG_ 1412 ECU_APPL_ORC "ECU_APPL_ORC";
BA_ "FlexKomSigStartPos" SG_ 1412 ECU_APPL_ORC 7;
BA_ "FlexKomSigStartValue" SG_ 1412 ECU_APPL_ORC "0000000000000000h";
BA_ "GenSigSendType" SG_ 1412 ECU_APPL_ORC 1;
BA_ "GenSigSNA" SG_ 1412 ECU_APPL_ORC "0h";
BA_ "FlexKomComment" SG_ 1442 ECU_APPL_PTS "ECU to External Application";
BA_ "FlexKomIsMotorola" SG_ 1442 ECU_APPL_PTS 1;
BA_ "FlexKomSID" SG_ 1442 ECU_APPL_PTS 376;
BA_ "FlexKomSigLaenge" SG_ 1442 ECU_APPL_PTS 64;
BA_ "FlexKomSigName" SG_ 1442 ECU_APPL_PTS "ECU_APPL_PTS";
BA_ "FlexKomSigStartPos" SG_ 1442 ECU_APPL_PTS 7;
BA_ "FlexKomSigStartValue" SG_ 1442 ECU_APPL_PTS "0000000000000000h";
BA_ "GenSigSendType" SG_ 1442 ECU_APPL_PTS 1;
BA_ "GenSigSNA" SG_ 1442 ECU_APPL_PTS "0h";
BA_ "FlexKomComment" SG_ 1408 ECU_APPL_RF_HUB "ECU to External Application";
BA_ "FlexKomIsMotorola" SG_ 1408 ECU_APPL_RF_HUB 1;
BA_ "FlexKomSID" SG_ 1408 ECU_APPL_RF_HUB 358;
BA_ "FlexKomSigLaenge" SG_ 1408 ECU_APPL_RF_HUB 64;
BA_ "FlexKomSigName" SG_ 1408 ECU_APPL_RF_HUB "ECU_APPL_RF_HUB";
BA_ "FlexKomSigStartPos" SG_ 1408 ECU_APPL_RF_HUB 7;
BA_ "FlexKomSigStartValue" SG_ 1408 ECU_APPL_RF_HUB "0000000000000000h";
BA_ "GenSigSendType" SG_ 1408 ECU_APPL_RF_HUB 1;
BA_ "GenSigSNA" SG_ 1408 ECU_APPL_RF_HUB "0h";
BA_ "FlexKomComment" SG_ 1443 ECU_APPL_SCCM "ECU to External Application";
BA_ "FlexKomIsMotorola" SG_ 1443 ECU_APPL_SCCM 1;
BA_ "FlexKomSID" SG_ 1443 ECU_APPL_SCCM 380;
BA_ "FlexKomSigLaenge" SG_ 1443 ECU_APPL_SCCM 64;
BA_ "FlexKomSigName" SG_ 1443 ECU_APPL_SCCM "ECU_APPL_SCCM";
BA_ "FlexKomSigStartPos" SG_ 1443 ECU_APPL_SCCM 7;
BA_ "FlexKomSigStartValue" SG_ 1443 ECU_APPL_SCCM "0000000000000000h";
BA_ "GenSigSendType" SG_ 1443 ECU_APPL_SCCM 1;
BA_ "GenSigSNA" SG_ 1443 ECU_APPL_SCCM "0h";
BA_ "FlexKomComment" SG_ 993 DISPLACEMENT "Engine Configuration Information";
BA_ "FlexKomIsMotorola" SG_ 993 DISPLACEMENT 1;
BA_ "FlexKomSID" SG_ 993 DISPLACEMENT 617;
BA_ "FlexKomSigLaenge" SG_ 993 DISPLACEMENT 32;
BA_ "FlexKomSigName" SG_ 993 DISPLACEMENT "ENG_CFG";
BA_ "FlexKomSigStartPos" SG_ 993 DISPLACEMENT 7;
BA_ "FlexKomSigStartValue" SG_ 993 DISPLACEMENT "FFEFE7E7h";
BA_ "GenSigCycleTime" SG_ 993 DISPLACEMENT 100;
BA_ "GenSigSNA" SG_ 993 DISPLACEMENT "FFh";
BA_ "GenSigStartValue" SG_ 993 DISPLACEMENT 255;
BA_ "GenSigTimeout_CBC" SG_ 993 DISPLACEMENT 1050;
BA_ "GenSigTimeout_EPS" SG_ 993 DISPLACEMENT 1050;
BA_ "GenSigTimeout_ETM" SG_ 993 DISPLACEMENT 1050;
BA_ "GenSigTimeout_IC" SG_ 993 DISPLACEMENT 1050;
BA_ "GenSigTimeout_ORC" SG_ 993 DISPLACEMENT 350;
BA_ "RID" SG_ 993 DISPLACEMENT "1899";
BA_ "FlexKomComment" SG_ 993 ECM_Vehi_Type "Engine Configuration Information";
BA_ "FlexKomIsMotorola" SG_ 993 ECM_Vehi_Type 1;
BA_ "FlexKomSID" SG_ 993 ECM_Vehi_Type 617;
BA_ "FlexKomSigLaenge" SG_ 993 ECM_Vehi_Type 32;
BA_ "FlexKomSigName" SG_ 993 ECM_Vehi_Type "ENG_CFG";
BA_ "FlexKomSigStartPos" SG_ 993 ECM_Vehi_Type 7;
BA_ "FlexKomSigStartValue" SG_ 993 ECM_Vehi_Type "FFEFE7E7h";
BA_ "GenSigCycleTime" SG_ 993 ECM_Vehi_Type 100;
BA_ "GenSigSNA" SG_ 993 ECM_Vehi_Type "3h";
BA_ "GenSigTimeout_IC" SG_ 993 ECM_Vehi_Type 1050;
BA_ "FlexKomComment" SG_ 993 ENG_ASP "Engine Configuration Information";
BA_ "FlexKomIsMotorola" SG_ 993 ENG_ASP 1;
BA_ "FlexKomSID" SG_ 993 ENG_ASP 617;
BA_ "FlexKomSigLaenge" SG_ 993 ENG_ASP 32;
BA_ "FlexKomSigName" SG_ 993 ENG_ASP "ENG_CFG";
BA_ "FlexKomSigStartPos" SG_ 993 ENG_ASP 7;
BA_ "FlexKomSigStartValue" SG_ 993 ENG_ASP "FFEFE7E7h";
BA_ "GenSigCycleTime" SG_ 993 ENG_ASP 100;
BA_ "GenSigSNA" SG_ 993 ENG_ASP "7h";
BA_ "GenSigStartValue" SG_ 993 ENG_ASP 7;
BA_ "GenSigTimeout_ETM" SG_ 993 ENG_ASP 1050;
BA_ "FlexKomComment" SG_ 993 ETC_PRSNT "Engine Configuration Information";
BA_ "FlexKomIsMotorola" SG_ 993 ETC_PRSNT 1;
BA_ "FlexKomSID" SG_ 993 ETC_PRSNT 617;
BA_ "FlexKomSigLaenge" SG_ 993 ETC_PRSNT 32;
BA_ "FlexKomSigName" SG_ 993 ETC_PRSNT "ENG_CFG";
BA_ "FlexKomSigStartPos" SG_ 993 ETC_PRSNT 7;
BA_ "FlexKomSigStartValue" SG_ 993 ETC_PRSNT "FFEFE7E7h";
BA_ "GenSigCycleTime" SG_ 993 ETC_PRSNT 100;
BA_ "GenSigSNA" SG_ 993 ETC_PRSNT "0h";
BA_ "GenSigTimeout_IC" SG_ 993 ETC_PRSNT 1050;
BA_ "FlexKomComment" SG_ 993 EngStyle "Engine Configuration Information";
BA_ "FlexKomIsMotorola" SG_ 993 EngStyle 1;
BA_ "FlexKomSID" SG_ 993 EngStyle 617;
BA_ "FlexKomSigLaenge" SG_ 993 EngStyle 32;
BA_ "FlexKomSigName" SG_ 993 EngStyle "ENG_CFG";
BA_ "FlexKomSigStartPos" SG_ 993 EngStyle 7;
BA_ "FlexKomSigStartValue" SG_ 993 EngStyle "FFEFE7E7h";
BA_ "GenSigCycleTime" SG_ 993 EngStyle 100;
BA_ "GenSigSNA" SG_ 993 EngStyle "7h";
BA_ "GenSigStartValue" SG_ 993 EngStyle 7;
BA_ "GenSigTimeout_CBC" SG_ 993 EngStyle 1050;
BA_ "RID" SG_ 993 EngStyle "1062";
BA_ "FlexKomComment" SG_ 993 FUEL_TYPE "Engine Configuration Information";
BA_ "FlexKomIsMotorola" SG_ 993 FUEL_TYPE 1;
BA_ "FlexKomSID" SG_ 993 FUEL_TYPE 617;
BA_ "FlexKomSigLaenge" SG_ 993 FUEL_TYPE 32;
BA_ "FlexKomSigName" SG_ 993 FUEL_TYPE "ENG_CFG";
BA_ "FlexKomSigStartPos" SG_ 993 FUEL_TYPE 7;
BA_ "FlexKomSigStartValue" SG_ 993 FUEL_TYPE "FFEFE7E7h";
BA_ "GenSigCycleTime" SG_ 993 FUEL_TYPE 100;
BA_ "GenSigSNA" SG_ 993 FUEL_TYPE "7h";
BA_ "GenSigStartValue" SG_ 993 FUEL_TYPE 7;
BA_ "GenSigTimeout_CBC" SG_ 993 FUEL_TYPE 1050;
BA_ "GenSigTimeout_IC" SG_ 993 FUEL_TYPE 1050;
BA_ "GenSigTimeout_ORC" SG_ 993 FUEL_TYPE 350;
BA_ "RID" SG_ 993 FUEL_TYPE "1261";
BA_ "FlexKomComment" SG_ 993 Manufacture "Engine Configuration Information";
BA_ "FlexKomIsMotorola" SG_ 993 Manufacture 1;
BA_ "FlexKomSID" SG_ 993 Manufacture 617;
BA_ "FlexKomSigLaenge" SG_ 993 Manufacture 32;
BA_ "FlexKomSigName" SG_ 993 Manufacture "ENG_CFG";
BA_ "FlexKomSigStartPos" SG_ 993 Manufacture 7;
BA_ "FlexKomSigStartValue" SG_ 993 Manufacture "FFEFE7E7h";
BA_ "GenSigCycleTime" SG_ 993 Manufacture 100;
BA_ "GenSigSNA" SG_ 993 Manufacture "7h";
BA_ "GenSigStartValue" SG_ 993 Manufacture 7;
BA_ "FlexKomComment" SG_ 993 NUM_CYL "Engine Configuration Information";
BA_ "FlexKomIsMotorola" SG_ 993 NUM_CYL 1;
BA_ "FlexKomSID" SG_ 993 NUM_CYL 617;
BA_ "FlexKomSigLaenge" SG_ 993 NUM_CYL 32;
BA_ "FlexKomSigName" SG_ 993 NUM_CYL "ENG_CFG";
BA_ "FlexKomSigStartPos" SG_ 993 NUM_CYL 7;
BA_ "FlexKomSigStartValue" SG_ 993 NUM_CYL "FFEFE7E7h";
BA_ "GenSigCycleTime" SG_ 993 NUM_CYL 100;
BA_ "GenSigSNA" SG_ 993 NUM_CYL "Fh";
BA_ "GenSigStartValue" SG_ 993 NUM_CYL 15;
BA_ "FlexKomComment" SG_ 993 NUM_VALVE "Engine Configuration Information";
BA_ "FlexKomIsMotorola" SG_ 993 NUM_VALVE 1;
BA_ "FlexKomSID" SG_ 993 NUM_VALVE 617;
BA_ "FlexKomSigLaenge" SG_ 993 NUM_VALVE 32;
BA_ "FlexKomSigName" SG_ 993 NUM_VALVE "ENG_CFG";
BA_ "FlexKomSigStartPos" SG_ 993 NUM_VALVE 7;
BA_ "FlexKomSigStartValue" SG_ 993 NUM_VALVE "FFEFE7E7h";
BA_ "GenSigCycleTime" SG_ 993 NUM_VALVE 100;
BA_ "GenSigSNA" SG_ 993 NUM_VALVE "7h";
BA_ "GenSigStartValue" SG_ 993 NUM_VALVE 7;
BA_ "FlexKomComment" SG_ 993 SpStPrsnt "Engine Configuration Information";
BA_ "FlexKomIsMotorola" SG_ 993 SpStPrsnt 1;
BA_ "FlexKomSID" SG_ 993 SpStPrsnt 617;
BA_ "FlexKomSigLaenge" SG_ 993 SpStPrsnt 32;
BA_ "FlexKomSigName" SG_ 993 SpStPrsnt "ENG_CFG";
BA_ "FlexKomSigStartPos" SG_ 993 SpStPrsnt 7;
BA_ "FlexKomSigStartValue" SG_ 993 SpStPrsnt "FFEFE7E7h";
BA_ "GenSigCycleTime" SG_ 993 SpStPrsnt 100;
BA_ "GenSigSNA" SG_ 993 SpStPrsnt "0h";
BA_ "GenSigTimeout_EPS" SG_ 993 SpStPrsnt 1050;
BA_ "GenSigTimeout_IC" SG_ 993 SpStPrsnt 1050;
BA_ "GenSigTimeout_ORC" SG_ 993 SpStPrsnt 350;
BA_ "RID" SG_ 993 SpStPrsnt "1164";
BA_ "FlexKomComment" SG_ 993 TRANS_TYPE "Engine Configuration Information";
BA_ "FlexKomIsMotorola" SG_ 993 TRANS_TYPE 1;
BA_ "FlexKomSID" SG_ 993 TRANS_TYPE 617;
BA_ "FlexKomSigLaenge" SG_ 993 TRANS_TYPE 32;
BA_ "FlexKomSigName" SG_ 993 TRANS_TYPE "ENG_CFG";
BA_ "FlexKomSigStartPos" SG_ 993 TRANS_TYPE 7;
BA_ "FlexKomSigStartValue" SG_ 993 TRANS_TYPE "FFEFE7E7h";
BA_ "GenSigCycleTime" SG_ 993 TRANS_TYPE 100;
BA_ "GenSigSNA" SG_ 993 TRANS_TYPE "0h";
BA_ "GenSigTimeout_IC" SG_ 993 TRANS_TYPE 1050;
BA_ "GenSigTimeout_ORC" SG_ 993 TRANS_TYPE 350;
BA_ "RID" SG_ 993 TRANS_TYPE "1094";
BA_ "FlexKomComment" SG_ 770 AutoParkSts "EPB_1 message packet";
BA_ "FlexKomIsMotorola" SG_ 770 AutoParkSts 1;
BA_ "FlexKomSID" SG_ 770 AutoParkSts 2083;
BA_ "FlexKomSigLaenge" SG_ 770 AutoParkSts 64;
BA_ "FlexKomSigName" SG_ 770 AutoParkSts "EPB_1";
BA_ "FlexKomSigStartPos" SG_ 770 AutoParkSts 7;
BA_ "FlexKomSigStartValue" SG_ 770 AutoParkSts "00000000000000FFh";
BA_ "GenSigCycleTime" SG_ 770 AutoParkSts 250;
BA_ "GenSigSNA" SG_ 770 AutoParkSts "3h";
BA_ "GenSigTimeout_IC" SG_ 770 AutoParkSts 2625;
BA_ "RID" SG_ 770 AutoParkSts "2161";
BA_ "FlexKomComment" SG_ 770 CRC_EPB_1 "EPB_1 message packet";
BA_ "FlexKomIsMotorola" SG_ 770 CRC_EPB_1 1;
BA_ "FlexKomSID" SG_ 770 CRC_EPB_1 2083;
BA_ "FlexKomSigLaenge" SG_ 770 CRC_EPB_1 64;
BA_ "FlexKomSigName" SG_ 770 CRC_EPB_1 "EPB_1";
BA_ "FlexKomSigStartPos" SG_ 770 CRC_EPB_1 7;
BA_ "FlexKomSigStartValue" SG_ 770 CRC_EPB_1 "00000000000000FFh";
BA_ "GenSigCycleTime" SG_ 770 CRC_EPB_1 250;
BA_ "GenSigSNA" SG_ 770 CRC_EPB_1 "FFh";
BA_ "GenSigStartValue" SG_ 770 CRC_EPB_1 255;
BA_ "GenSigTimeout_IC" SG_ 770 CRC_EPB_1 2625;
BA_ "FlexKomComment" SG_ 770 ClampForce "EPB_1 message packet";
BA_ "FlexKomIsMotorola" SG_ 770 ClampForce 1;
BA_ "FlexKomSID" SG_ 770 ClampForce 2083;
BA_ "FlexKomSigLaenge" SG_ 770 ClampForce 64;
BA_ "FlexKomSigName" SG_ 770 ClampForce "EPB_1";
BA_ "FlexKomSigStartPos" SG_ 770 ClampForce 7;
BA_ "FlexKomSigStartValue" SG_ 770 ClampForce "00000000000000FFh";
BA_ "GenSigCycleTime" SG_ 770 ClampForce 250;
BA_ "GenSigSNA" SG_ 770 ClampForce "0h";
BA_ "GenSigTimeout_IC" SG_ 770 ClampForce 2625;
BA_ "GenSigTimeout_ORC" SG_ 770 ClampForce 875;
BA_ "FlexKomComment" SG_ 770 EPBSts "EPB_1 message packet";
BA_ "FlexKomIsMotorola" SG_ 770 EPBSts 1;
BA_ "FlexKomSID" SG_ 770 EPBSts 2083;
BA_ "FlexKomSigLaenge" SG_ 770 EPBSts 64;
BA_ "FlexKomSigName" SG_ 770 EPBSts "EPB_1";
BA_ "FlexKomSigStartPos" SG_ 770 EPBSts 7;
BA_ "FlexKomSigStartValue" SG_ 770 EPBSts "00000000000000FFh";
BA_ "GenSigCycleTime" SG_ 770 EPBSts 250;
BA_ "GenSigSNA" SG_ 770 EPBSts "0h";
BA_ "GenSigTimeout_IC" SG_ 770 EPBSts 2625;
BA_ "GenSigTimeout_ORC" SG_ 770 EPBSts 875;
BA_ "FlexKomComment" SG_ 770 EPBWarningLampReq "EPB_1 message packet";
BA_ "FlexKomIsMotorola" SG_ 770 EPBWarningLampReq 1;
BA_ "FlexKomSID" SG_ 770 EPBWarningLampReq 2083;
BA_ "FlexKomSigLaenge" SG_ 770 EPBWarningLampReq 64;
BA_ "FlexKomSigName" SG_ 770 EPBWarningLampReq "EPB_1";
BA_ "FlexKomSigStartPos" SG_ 770 EPBWarningLampReq 7;
BA_ "FlexKomSigStartValue" SG_ 770 EPBWarningLampReq "00000000000000FFh";
BA_ "GenSigCycleTime" SG_ 770 EPBWarningLampReq 250;
BA_ "GenSigSNA" SG_ 770 EPBWarningLampReq "3h";
BA_ "GenSigTimeout_IC" SG_ 770 EPBWarningLampReq 2625;
BA_ "GenSigTimeout_ORC" SG_ 770 EPBWarningLampReq 875;
BA_ "FlexKomComment" SG_ 770 EPB_Sw_Stat "EPB_1 message packet";
BA_ "FlexKomIsMotorola" SG_ 770 EPB_Sw_Stat 1;
BA_ "FlexKomSID" SG_ 770 EPB_Sw_Stat 2083;
BA_ "FlexKomSigLaenge" SG_ 770 EPB_Sw_Stat 64;
BA_ "FlexKomSigName" SG_ 770 EPB_Sw_Stat "EPB_1";
BA_ "FlexKomSigStartPos" SG_ 770 EPB_Sw_Stat 7;
BA_ "FlexKomSigStartValue" SG_ 770 EPB_Sw_Stat "00000000000000FFh";
BA_ "GenSigCycleTime" SG_ 770 EPB_Sw_Stat 250;
BA_ "GenSigSNA" SG_ 770 EPB_Sw_Stat "3h";
BA_ "GenSigTimeout_IC" SG_ 770 EPB_Sw_Stat 2625;
BA_ "GenSigTimeout_ORC" SG_ 770 EPB_Sw_Stat 875;
BA_ "FlexKomComment" SG_ 770 FunctionLamp "EPB_1 message packet";
BA_ "FlexKomIsMotorola" SG_ 770 FunctionLamp 1;
BA_ "FlexKomSID" SG_ 770 FunctionLamp 2083;
BA_ "FlexKomSigLaenge" SG_ 770 FunctionLamp 64;
BA_ "FlexKomSigName" SG_ 770 FunctionLamp "EPB_1";
BA_ "FlexKomSigStartPos" SG_ 770 FunctionLamp 7;
BA_ "FlexKomSigStartValue" SG_ 770 FunctionLamp "00000000000000FFh";
BA_ "GenSigCycleTime" SG_ 770 FunctionLamp 250;
BA_ "GenSigSNA" SG_ 770 FunctionLamp "3h";
BA_ "GenSigTimeout_IC" SG_ 770 FunctionLamp 2625;
BA_ "FlexKomComment" SG_ 770 MC_EPB_1 "EPB_1 message packet";
BA_ "FlexKomIsMotorola" SG_ 770 MC_EPB_1 1;
BA_ "FlexKomSID" SG_ 770 MC_EPB_1 2083;
BA_ "FlexKomSigLaenge" SG_ 770 MC_EPB_1 64;
BA_ "FlexKomSigName" SG_ 770 MC_EPB_1 "EPB_1";
BA_ "FlexKomSigStartPos" SG_ 770 MC_EPB_1 7;
BA_ "FlexKomSigStartValue" SG_ 770 MC_EPB_1 "00000000000000FFh";
BA_ "GenSigCycleTime" SG_ 770 MC_EPB_1 250;
BA_ "GenSigSNA" SG_ 770 MC_EPB_1 "0h";
BA_ "GenSigTimeout_IC" SG_ 770 MC_EPB_1 2625;
BA_ "RID" SG_ 770 MC_EPB_1 "9772";
BA_ "FlexKomComment" SG_ 770 ServiceModeSts "EPB_1 message packet";
BA_ "FlexKomIsMotorola" SG_ 770 ServiceModeSts 1;
BA_ "FlexKomSID" SG_ 770 ServiceModeSts 2083;
BA_ "FlexKomSigLaenge" SG_ 770 ServiceModeSts 64;
BA_ "FlexKomSigName" SG_ 770 ServiceModeSts "EPB_1";
BA_ "FlexKomSigStartPos" SG_ 770 ServiceModeSts 7;
BA_ "FlexKomSigStartValue" SG_ 770 ServiceModeSts "00000000000000FFh";
BA_ "GenSigCycleTime" SG_ 770 ServiceModeSts 250;
BA_ "GenSigSNA" SG_ 770 ServiceModeSts "0h";
BA_ "GenSigTimeout_IC" SG_ 770 ServiceModeSts 2625;
BA_ "RID" SG_ 770 ServiceModeSts "2162";
BA_ "FlexKomComment" SG_ 770 TextDisplay "EPB_1 message packet";
BA_ "FlexKomIsMotorola" SG_ 770 TextDisplay 1;
BA_ "FlexKomSID" SG_ 770 TextDisplay 2083;
BA_ "FlexKomSigLaenge" SG_ 770 TextDisplay 64;
BA_ "FlexKomSigName" SG_ 770 TextDisplay "EPB_1";
BA_ "FlexKomSigStartPos" SG_ 770 TextDisplay 7;
BA_ "FlexKomSigStartValue" SG_ 770 TextDisplay "00000000000000FFh";
BA_ "GenSigCycleTime" SG_ 770 TextDisplay 250;
BA_ "GenSigSNA" SG_ 770 TextDisplay "1Fh";
BA_ "GenSigTimeout_IC" SG_ 770 TextDisplay 2625;
BA_ "RID" SG_ 770 TextDisplay "2158";
BA_ "FlexKomComment" SG_ 669 CRC_EPB_A1 "EPB_A1 message packet";
BA_ "FlexKomIsMotorola" SG_ 669 CRC_EPB_A1 1;
BA_ "FlexKomSID" SG_ 669 CRC_EPB_A1 2013;
BA_ "FlexKomSigLaenge" SG_ 669 CRC_EPB_A1 24;
BA_ "FlexKomSigName" SG_ 669 CRC_EPB_A1 "EPB_A1_Pkt";
BA_ "FlexKomSigStartPos" SG_ 669 CRC_EPB_A1 7;
BA_ "FlexKomSigStartValue" SG_ 669 CRC_EPB_A1 "0000FFh";
BA_ "GenSigCycleTime" SG_ 669 CRC_EPB_A1 40;
BA_ "GenSigSNA" SG_ 669 CRC_EPB_A1 "FFh";
BA_ "GenSigStartValue" SG_ 669 CRC_EPB_A1 255;
BA_ "FlexKomComment" SG_ 669 EPBActivation "EPB_A1 message packet";
BA_ "FlexKomIsMotorola" SG_ 669 EPBActivation 1;
BA_ "FlexKomSID" SG_ 669 EPBActivation 2013;
BA_ "FlexKomSigLaenge" SG_ 669 EPBActivation 24;
BA_ "FlexKomSigName" SG_ 669 EPBActivation "EPB_A1_Pkt";
BA_ "FlexKomSigStartPos" SG_ 669 EPBActivation 7;
BA_ "FlexKomSigStartValue" SG_ 669 EPBActivation "0000FFh";
BA_ "GenSigCycleTime" SG_ 669 EPBActivation 40;
BA_ "GenSigSNA" SG_ 669 EPBActivation "1Fh";
BA_ "FlexKomComment" SG_ 669 EPBHoldSts "EPB_A1 message packet";
BA_ "FlexKomIsMotorola" SG_ 669 EPBHoldSts 1;
BA_ "FlexKomSID" SG_ 669 EPBHoldSts 2013;
BA_ "FlexKomSigLaenge" SG_ 669 EPBHoldSts 24;
BA_ "FlexKomSigName" SG_ 669 EPBHoldSts "EPB_A1_Pkt";
BA_ "FlexKomSigStartPos" SG_ 669 EPBHoldSts 7;
BA_ "FlexKomSigStartValue" SG_ 669 EPBHoldSts "0000FFh";
BA_ "GenSigCycleTime" SG_ 669 EPBHoldSts 40;
BA_ "GenSigSNA" SG_ 669 EPBHoldSts "0h";
BA_ "GenSigTimeout_ORC" SG_ 669 EPBHoldSts 140;
BA_ "RID" SG_ 669 EPBHoldSts "2160";
BA_ "FlexKomComment" SG_ 669 MC_EPB_A1 "EPB_A1 message packet";
BA_ "FlexKomIsMotorola" SG_ 669 MC_EPB_A1 1;
BA_ "FlexKomSID" SG_ 669 MC_EPB_A1 2013;
BA_ "FlexKomSigLaenge" SG_ 669 MC_EPB_A1 24;
BA_ "FlexKomSigName" SG_ 669 MC_EPB_A1 "EPB_A1_Pkt";
BA_ "FlexKomSigStartPos" SG_ 669 MC_EPB_A1 7;
BA_ "FlexKomSigStartValue" SG_ 669 MC_EPB_A1 "0000FFh";
BA_ "GenSigCycleTime" SG_ 669 MC_EPB_A1 40;
BA_ "GenSigSNA" SG_ 669 MC_EPB_A1 "0h";
BA_ "RID" SG_ 669 MC_EPB_A1 "9774";
BA_ "GenSigSNA" SG_ 544 DSTTorqueOverlayIntActivated "0h";
BA_ "FlexKomSigStartValue" SG_ 544 DSTTorqueOverlayIntActivated "07FF0FFF040000FFh";
BA_ "FlexKomSigStartPos" SG_ 544 DSTTorqueOverlayIntActivated 7;
BA_ "FlexKomSigName" SG_ 544 DSTTorqueOverlayIntActivated "EPS_1_PKT";
BA_ "FlexKomSigLaenge" SG_ 544 DSTTorqueOverlayIntActivated 64;
BA_ "FlexKomSID" SG_ 544 DSTTorqueOverlayIntActivated 1415;
BA_ "FlexKomComment" SG_ 544 DSTTorqueOverlayIntActivated "EPS_1 packet";
BA_ "GenSigCycleTime" SG_ 544 DSTTorqueOverlayIntActivated 10;
BA_ "FlexKomIsMotorola" SG_ 544 DSTTorqueOverlayIntActivated 1;
BA_ "GenSigTimeout_HaLF" SG_ 544 DSTTorqueOverlayIntActivated 105;
BA_ "GenSigCycleTime" SG_ 544 AssistanceTorque 10;
BA_ "GenSigStartValue" SG_ 544 AssistanceTorque 4095;
BA_ "FlexKomComment" SG_ 544 AssistanceTorque "EPS_1 packet";
BA_ "FlexKomIsMotorola" SG_ 544 AssistanceTorque 1;
BA_ "FlexKomSID" SG_ 544 AssistanceTorque 1415;
BA_ "FlexKomSigLaenge" SG_ 544 AssistanceTorque 64;
BA_ "FlexKomSigName" SG_ 544 AssistanceTorque "EPS_1_PKT";
BA_ "FlexKomSigStartPos" SG_ 544 AssistanceTorque 7;
BA_ "FlexKomSigStartValue" SG_ 544 AssistanceTorque "07FF0FFF040000FFh";
BA_ "GenSigSNA" SG_ 544 AssistanceTorque "FFFh";
BA_ "GenSigTimeout_HaLF" SG_ 544 AssistanceTorque 105;
BA_ "GenSigTimeout_PTS" SG_ 544 AssistanceTorque 105;
BA_ "GenSigTimeout_PTS" SG_ 544 DSTTorqueOverlayFault 105;
BA_ "GenSigTimeout_HaLF" SG_ 544 DSTTorqueOverlayFault 105;
BA_ "GenSigSNA" SG_ 544 DSTTorqueOverlayFault "0h";
BA_ "FlexKomSigStartValue" SG_ 544 DSTTorqueOverlayFault "07FF0FFF040000FFh";
BA_ "FlexKomSigStartPos" SG_ 544 DSTTorqueOverlayFault 7;
BA_ "FlexKomSigName" SG_ 544 DSTTorqueOverlayFault "EPS_1_PKT";
BA_ "FlexKomSigLaenge" SG_ 544 DSTTorqueOverlayFault 64;
BA_ "FlexKomSID" SG_ 544 DSTTorqueOverlayFault 1415;
BA_ "FlexKomIsMotorola" SG_ 544 DSTTorqueOverlayFault 1;
BA_ "FlexKomComment" SG_ 544 DSTTorqueOverlayFault "EPS_1 packet";
BA_ "GenSigCycleTime" SG_ 544 DSTTorqueOverlayFault 10;
BA_ "FlexKomComment" SG_ 544 TOI_Act_Sts "EPS_1 packet";
BA_ "FlexKomIsMotorola" SG_ 544 TOI_Act_Sts 1;
BA_ "FlexKomSID" SG_ 544 TOI_Act_Sts 1415;
BA_ "FlexKomSigLaenge" SG_ 544 TOI_Act_Sts 64;
BA_ "FlexKomSigName" SG_ 544 TOI_Act_Sts "EPS_1_PKT";
BA_ "FlexKomSigStartPos" SG_ 544 TOI_Act_Sts 7;
BA_ "FlexKomSigStartValue" SG_ 544 TOI_Act_Sts "07FF0FFF040000FFh";
BA_ "GenSigCycleTime" SG_ 544 TOI_Act_Sts 10;
BA_ "GenSigSNA" SG_ 544 TOI_Act_Sts "Fh";
BA_ "GenSigTimeout_HaLF" SG_ 544 TOI_Act_Sts 105;
BA_ "GenSigTimeout_PTS" SG_ 544 TOI_Act_Sts 105;
BA_ "FlexKomComment" SG_ 544 CRC_EPS_1 "EPS_1 packet";
BA_ "FlexKomIsMotorola" SG_ 544 CRC_EPS_1 1;
BA_ "FlexKomSID" SG_ 544 CRC_EPS_1 1415;
BA_ "FlexKomSigLaenge" SG_ 544 CRC_EPS_1 64;
BA_ "FlexKomSigName" SG_ 544 CRC_EPS_1 "EPS_1_PKT";
BA_ "FlexKomSigStartPos" SG_ 544 CRC_EPS_1 7;
BA_ "FlexKomSigStartValue" SG_ 544 CRC_EPS_1 "07FF07FF040000FFh";
BA_ "GenSigCycleTime" SG_ 544 CRC_EPS_1 10;
BA_ "GenSigSNA" SG_ 544 CRC_EPS_1 "FFh";
BA_ "GenSigStartValue" SG_ 544 CRC_EPS_1 255;
BA_ "GenSigTimeout_HaLF" SG_ 544 CRC_EPS_1 105;
BA_ "GenSigTimeout_PTS" SG_ 544 CRC_EPS_1 105;
BA_ "FlexKomComment" SG_ 544 EPSHandsOnRecognition "EPS_1 packet";
BA_ "FlexKomIsMotorola" SG_ 544 EPSHandsOnRecognition 1;
BA_ "FlexKomSID" SG_ 544 EPSHandsOnRecognition 1415;
BA_ "FlexKomSigLaenge" SG_ 544 EPSHandsOnRecognition 64;
BA_ "FlexKomSigName" SG_ 544 EPSHandsOnRecognition "EPS_1_PKT";
BA_ "FlexKomSigStartPos" SG_ 544 EPSHandsOnRecognition 7;
BA_ "FlexKomSigStartValue" SG_ 544 EPSHandsOnRecognition "07FF07FF040000FFh";
BA_ "GenSigCycleTime" SG_ 544 EPSHandsOnRecognition 10;
BA_ "GenSigSNA" SG_ 544 EPSHandsOnRecognition "0h";
BA_ "GenSigTimeout_HaLF" SG_ 544 EPSHandsOnRecognition 105;
BA_ "GenSigTimeout_PTS" SG_ 544 EPSHandsOnRecognition 105;
BA_ "FlexKomComment" SG_ 544 EPSMotorTorque "EPS_1 packet";
BA_ "FlexKomIsMotorola" SG_ 544 EPSMotorTorque 1;
BA_ "FlexKomSID" SG_ 544 EPSMotorTorque 1415;
BA_ "FlexKomSigLaenge" SG_ 544 EPSMotorTorque 64;
BA_ "FlexKomSigName" SG_ 544 EPSMotorTorque "EPS_1_PKT";
BA_ "FlexKomSigStartPos" SG_ 544 EPSMotorTorque 7;
BA_ "FlexKomSigStartValue" SG_ 544 EPSMotorTorque "07FF07FF040000FFh";
BA_ "GenSigCycleTime" SG_ 544 EPSMotorTorque 10;
BA_ "GenSigSNA" SG_ 544 EPSMotorTorque "400h";
BA_ "GenSigStartValue" SG_ 544 EPSMotorTorque 1024;
BA_ "GenSigTimeout_HaLF" SG_ 544 EPSMotorTorque 105;
BA_ "FlexKomComment" SG_ 544 EPSMotorTorqueValidData "EPS_1 packet";
BA_ "FlexKomIsMotorola" SG_ 544 EPSMotorTorqueValidData 1;
BA_ "FlexKomSID" SG_ 544 EPSMotorTorqueValidData 1415;
BA_ "FlexKomSigLaenge" SG_ 544 EPSMotorTorqueValidData 64;
BA_ "FlexKomSigName" SG_ 544 EPSMotorTorqueValidData "EPS_1_PKT";
BA_ "FlexKomSigStartPos" SG_ 544 EPSMotorTorqueValidData 7;
BA_ "FlexKomSigStartValue" SG_ 544 EPSMotorTorqueValidData "07FF07FF040000FFh";
BA_ "GenSigCycleTime" SG_ 544 EPSMotorTorqueValidData 10;
BA_ "GenSigSNA" SG_ 544 EPSMotorTorqueValidData "0h";
BA_ "GenSigTimeout_HaLF" SG_ 544 EPSMotorTorqueValidData 105;
BA_ "FlexKomComment" SG_ 544 EPSTemporaryDeactivationLDW "EPS_1 packet";
BA_ "FlexKomIsMotorola" SG_ 544 EPSTemporaryDeactivationLDW 1;
BA_ "FlexKomSID" SG_ 544 EPSTemporaryDeactivationLDW 1415;
BA_ "FlexKomSigLaenge" SG_ 544 EPSTemporaryDeactivationLDW 64;
BA_ "FlexKomSigName" SG_ 544 EPSTemporaryDeactivationLDW "EPS_1_PKT";
BA_ "FlexKomSigStartPos" SG_ 544 EPSTemporaryDeactivationLDW 7;
BA_ "FlexKomSigStartValue" SG_ 544 EPSTemporaryDeactivationLDW "07FF07FF040000FFh";
BA_ "GenSigCycleTime" SG_ 544 EPSTemporaryDeactivationLDW 10;
BA_ "GenSigSNA" SG_ 544 EPSTemporaryDeactivationLDW "0h";
BA_ "FlexKomComment" SG_ 544 EPSTemporaryDeactivationPPPA "EPS_1 packet";
BA_ "FlexKomIsMotorola" SG_ 544 EPSTemporaryDeactivationPPPA 1;
BA_ "FlexKomSID" SG_ 544 EPSTemporaryDeactivationPPPA 1415;
BA_ "FlexKomSigLaenge" SG_ 544 EPSTemporaryDeactivationPPPA 64;
BA_ "FlexKomSigName" SG_ 544 EPSTemporaryDeactivationPPPA "EPS_1_PKT";
BA_ "FlexKomSigStartPos" SG_ 544 EPSTemporaryDeactivationPPPA 7;
BA_ "FlexKomSigStartValue" SG_ 544 EPSTemporaryDeactivationPPPA "07FF07FF040000FFh";
BA_ "GenSigCycleTime" SG_ 544 EPSTemporaryDeactivationPPPA 10;
BA_ "GenSigSNA" SG_ 544 EPSTemporaryDeactivationPPPA "0h";
BA_ "GenSigTimeout_HaLF" SG_ 544 EPSTemporaryDeactivationPPPA 105;
BA_ "GenSigTimeout_PTS" SG_ 544 EPSTemporaryDeactivationPPPA 105;
BA_ "FlexKomComment" SG_ 544 HALFTorqueOverlayFault "EPS_1 packet";
BA_ "FlexKomIsMotorola" SG_ 544 HALFTorqueOverlayFault 1;
BA_ "FlexKomSID" SG_ 544 HALFTorqueOverlayFault 1415;
BA_ "FlexKomSigLaenge" SG_ 544 HALFTorqueOverlayFault 64;
BA_ "FlexKomSigName" SG_ 544 HALFTorqueOverlayFault "EPS_1_PKT";
BA_ "FlexKomSigStartPos" SG_ 544 HALFTorqueOverlayFault 7;
BA_ "FlexKomSigStartValue" SG_ 544 HALFTorqueOverlayFault "07FF07FF040000FFh";
BA_ "GenSigCycleTime" SG_ 544 HALFTorqueOverlayFault 10;
BA_ "GenSigSNA" SG_ 544 HALFTorqueOverlayFault "0h";
BA_ "GenSigTimeout_HaLF" SG_ 544 HALFTorqueOverlayFault 105;
BA_ "GenSigTimeout_PTS" SG_ 544 HALFTorqueOverlayFault 105;
BA_ "FlexKomComment" SG_ 544 HALFTorqueOverlayIntActivated "EPS_1 packet";
BA_ "FlexKomIsMotorola" SG_ 544 HALFTorqueOverlayIntActivated 1;
BA_ "FlexKomSID" SG_ 544 HALFTorqueOverlayIntActivated 1415;
BA_ "FlexKomSigLaenge" SG_ 544 HALFTorqueOverlayIntActivated 64;
BA_ "FlexKomSigName" SG_ 544 HALFTorqueOverlayIntActivated "EPS_1_PKT";
BA_ "FlexKomSigStartPos" SG_ 544 HALFTorqueOverlayIntActivated 7;
BA_ "FlexKomSigStartValue" SG_ 544 HALFTorqueOverlayIntActivated "07FF07FF040000FFh";
BA_ "GenSigCycleTime" SG_ 544 HALFTorqueOverlayIntActivated 10;
BA_ "GenSigSNA" SG_ 544 HALFTorqueOverlayIntActivated "0h";
BA_ "GenSigTimeout_HaLF" SG_ 544 HALFTorqueOverlayIntActivated 105;
BA_ "GenSigTimeout_PTS" SG_ 544 HALFTorqueOverlayIntActivated 105;
BA_ "FlexKomComment" SG_ 544 MC_EPS_1 "EPS_1 packet";
BA_ "FlexKomIsMotorola" SG_ 544 MC_EPS_1 1;
BA_ "FlexKomSID" SG_ 544 MC_EPS_1 1415;
BA_ "FlexKomSigLaenge" SG_ 544 MC_EPS_1 64;
BA_ "FlexKomSigName" SG_ 544 MC_EPS_1 "EPS_1_PKT";
BA_ "FlexKomSigStartPos" SG_ 544 MC_EPS_1 7;
BA_ "FlexKomSigStartValue" SG_ 544 MC_EPS_1 "07FF07FF040000FFh";
BA_ "GenSigCycleTime" SG_ 544 MC_EPS_1 10;
BA_ "GenSigSNA" SG_ 544 MC_EPS_1 "0h";
BA_ "GenSigTimeout_HaLF" SG_ 544 MC_EPS_1 105;
BA_ "GenSigTimeout_PTS" SG_ 544 MC_EPS_1 105;
BA_ "FlexKomComment" SG_ 544 PTSDriveStyleSts "EPS_1 packet";
BA_ "FlexKomIsMotorola" SG_ 544 PTSDriveStyleSts 1;
BA_ "FlexKomSID" SG_ 544 PTSDriveStyleSts 1415;
BA_ "FlexKomSigLaenge" SG_ 544 PTSDriveStyleSts 64;
BA_ "FlexKomSigName" SG_ 544 PTSDriveStyleSts "EPS_1_PKT";
BA_ "FlexKomSigStartPos" SG_ 544 PTSDriveStyleSts 7;
BA_ "FlexKomSigStartValue" SG_ 544 PTSDriveStyleSts "07FF07FF040000FFh";
BA_ "GenSigCycleTime" SG_ 544 PTSDriveStyleSts 10;
BA_ "GenSigSNA" SG_ 544 PTSDriveStyleSts "0h";
BA_ "GenSigTimeout_HaLF" SG_ 544 PTSDriveStyleSts 105;
BA_ "GenSigTimeout_PTS" SG_ 544 PTSDriveStyleSts 105;
BA_ "FlexKomComment" SG_ 544 PTSTorqueOverlayFault "EPS_1 packet";
BA_ "FlexKomIsMotorola" SG_ 544 PTSTorqueOverlayFault 1;
BA_ "FlexKomSID" SG_ 544 PTSTorqueOverlayFault 1415;
BA_ "FlexKomSigLaenge" SG_ 544 PTSTorqueOverlayFault 64;
BA_ "FlexKomSigName" SG_ 544 PTSTorqueOverlayFault "EPS_1_PKT";
BA_ "FlexKomSigStartPos" SG_ 544 PTSTorqueOverlayFault 7;
BA_ "FlexKomSigStartValue" SG_ 544 PTSTorqueOverlayFault "07FF07FF040000FFh";
BA_ "GenSigCycleTime" SG_ 544 PTSTorqueOverlayFault 10;
BA_ "GenSigSNA" SG_ 544 PTSTorqueOverlayFault "0h";
BA_ "GenSigTimeout_HaLF" SG_ 544 PTSTorqueOverlayFault 105;
BA_ "GenSigTimeout_PTS" SG_ 544 PTSTorqueOverlayFault 105;
BA_ "FlexKomComment" SG_ 544 PTSTorqueOverlayIntActivated "EPS_1 packet";
BA_ "FlexKomIsMotorola" SG_ 544 PTSTorqueOverlayIntActivated 1;
BA_ "FlexKomSID" SG_ 544 PTSTorqueOverlayIntActivated 1415;
BA_ "FlexKomSigLaenge" SG_ 544 PTSTorqueOverlayIntActivated 64;
BA_ "FlexKomSigName" SG_ 544 PTSTorqueOverlayIntActivated "EPS_1_PKT";
BA_ "FlexKomSigStartPos" SG_ 544 PTSTorqueOverlayIntActivated 7;
BA_ "FlexKomSigStartValue" SG_ 544 PTSTorqueOverlayIntActivated "07FF07FF040000FFh";
BA_ "GenSigCycleTime" SG_ 544 PTSTorqueOverlayIntActivated 10;
BA_ "GenSigSNA" SG_ 544 PTSTorqueOverlayIntActivated "0h";
BA_ "GenSigTimeout_HaLF" SG_ 544 PTSTorqueOverlayIntActivated 105;
BA_ "GenSigTimeout_PTS" SG_ 544 PTSTorqueOverlayIntActivated 105;
BA_ "FlexKomComment" SG_ 544 StrClmTrq "EPS_1 packet";
BA_ "FlexKomIsMotorola" SG_ 544 StrClmTrq 1;
BA_ "FlexKomSID" SG_ 544 StrClmTrq 1415;
BA_ "FlexKomSigLaenge" SG_ 544 StrClmTrq 64;
BA_ "FlexKomSigName" SG_ 544 StrClmTrq "EPS_1_PKT";
BA_ "FlexKomSigStartPos" SG_ 544 StrClmTrq 7;
BA_ "FlexKomSigStartValue" SG_ 544 StrClmTrq "07FF07FF040000FFh";
BA_ "GenSigCycleTime" SG_ 544 StrClmTrq 10;
BA_ "GenSigSNA" SG_ 544 StrClmTrq "7FFh";
BA_ "GenSigStartValue" SG_ 544 StrClmTrq 2047;
BA_ "GenSigTimeout_HaLF" SG_ 544 StrClmTrq 105;
BA_ "GenSigTimeout_PTS" SG_ 544 StrClmTrq 105;
BA_ "FlexKomComment" SG_ 544 StrClmTrqVD "EPS_1 packet";
BA_ "FlexKomIsMotorola" SG_ 544 StrClmTrqVD 1;
BA_ "FlexKomSID" SG_ 544 StrClmTrqVD 1415;
BA_ "FlexKomSigLaenge" SG_ 544 StrClmTrqVD 64;
BA_ "FlexKomSigName" SG_ 544 StrClmTrqVD "EPS_1_PKT";
BA_ "FlexKomSigStartPos" SG_ 544 StrClmTrqVD 7;
BA_ "FlexKomSigStartValue" SG_ 544 StrClmTrqVD "07FF07FF040000FFh";
BA_ "GenSigCycleTime" SG_ 544 StrClmTrqVD 10;
BA_ "GenSigSNA" SG_ 544 StrClmTrqVD "0h";
BA_ "GenSigTimeout_HaLF" SG_ 544 StrClmTrqVD 105;
BA_ "GenSigTimeout_PTS" SG_ 544 StrClmTrqVD 105;
BA_ "FlexKomComment" SG_ 300 EPS_AsstStat "EPS_A1_PKT";
BA_ "FlexKomIsMotorola" SG_ 300 EPS_AsstStat 1;
BA_ "FlexKomSID" SG_ 300 EPS_AsstStat 846;
BA_ "FlexKomSigLaenge" SG_ 300 EPS_AsstStat 64;
BA_ "FlexKomSigName" SG_ 300 EPS_AsstStat "EPS_A1_PKT";
BA_ "FlexKomSigStartPos" SG_ 300 EPS_AsstStat 7;
BA_ "FlexKomSigStartValue" SG_ 300 EPS_AsstStat "0200FFFF00000000h";
BA_ "GenSigCycleTime" SG_ 300 EPS_AsstStat 100;
BA_ "GenSigSNA" SG_ 300 EPS_AsstStat "7h";
BA_ "GenSigStartValue" SG_ 300 EPS_AsstStat 1;
BA_ "GenSigTimeout_IC" SG_ 300 EPS_AsstStat 1050;
BA_ "GenSigTimeout_ORC" SG_ 300 EPS_AsstStat 350;
BA_ "FlexKomComment" SG_ 300 EPS_Curr "EPS_A1_PKT";
BA_ "FlexKomIsMotorola" SG_ 300 EPS_Curr 1;
BA_ "FlexKomSID" SG_ 300 EPS_Curr 846;
BA_ "FlexKomSigLaenge" SG_ 300 EPS_Curr 64;
BA_ "FlexKomSigName" SG_ 300 EPS_Curr "EPS_A1_PKT";
BA_ "FlexKomSigStartPos" SG_ 300 EPS_Curr 7;
BA_ "FlexKomSigStartValue" SG_ 300 EPS_Curr "0200FFFF00000000h";
BA_ "GenSigCycleTime" SG_ 300 EPS_Curr 100;
BA_ "GenSigSNA" SG_ 300 EPS_Curr "FFh";
BA_ "GenSigStartValue" SG_ 300 EPS_Curr 255;
BA_ "FlexKomComment" SG_ 300 EPS_ErrStat "EPS_A1_PKT";
BA_ "FlexKomIsMotorola" SG_ 300 EPS_ErrStat 1;
BA_ "FlexKomSID" SG_ 300 EPS_ErrStat 846;
BA_ "FlexKomSigLaenge" SG_ 300 EPS_ErrStat 64;
BA_ "FlexKomSigName" SG_ 300 EPS_ErrStat "EPS_A1_PKT";
BA_ "FlexKomSigStartPos" SG_ 300 EPS_ErrStat 7;
BA_ "FlexKomSigStartValue" SG_ 300 EPS_ErrStat "0200FFFF00000000h";
BA_ "GenSigCycleTime" SG_ 300 EPS_ErrStat 100;
BA_ "GenSigSNA" SG_ 300 EPS_ErrStat "7h";
BA_ "GenSigTimeout_CBC" SG_ 300 EPS_ErrStat 1050;
BA_ "GenSigTimeout_IC" SG_ 300 EPS_ErrStat 1050;
BA_ "GenSigTimeout_ORC" SG_ 300 EPS_ErrStat 350;
BA_ "FlexKomComment" SG_ 300 EPS_IntraECUCommFault "EPS_A1_PKT";
BA_ "FlexKomIsMotorola" SG_ 300 EPS_IntraECUCommFault 1;
BA_ "FlexKomSID" SG_ 300 EPS_IntraECUCommFault 846;
BA_ "FlexKomSigLaenge" SG_ 300 EPS_IntraECUCommFault 64;
BA_ "FlexKomSigName" SG_ 300 EPS_IntraECUCommFault "EPS_A1_PKT";
BA_ "FlexKomSigStartPos" SG_ 300 EPS_IntraECUCommFault 7;
BA_ "FlexKomSigStartValue" SG_ 300 EPS_IntraECUCommFault "0200FFFF00000000h";
BA_ "GenSigCycleTime" SG_ 300 EPS_IntraECUCommFault 100;
BA_ "GenSigSNA" SG_ 300 EPS_IntraECUCommFault "7h";
BA_ "GenSigTimeout_IC" SG_ 300 EPS_IntraECUCommFault 1050;
BA_ "GenSigTimeout_ORC" SG_ 300 EPS_IntraECUCommFault 350;
BA_ "FlexKomComment" SG_ 300 EPS_MODE_STAT "EPS_A1_PKT";
BA_ "FlexKomIsMotorola" SG_ 300 EPS_MODE_STAT 1;
BA_ "FlexKomSID" SG_ 300 EPS_MODE_STAT 846;
BA_ "FlexKomSigLaenge" SG_ 300 EPS_MODE_STAT 64;
BA_ "FlexKomSigName" SG_ 300 EPS_MODE_STAT "EPS_A1_PKT";
BA_ "FlexKomSigStartPos" SG_ 300 EPS_MODE_STAT 7;
BA_ "FlexKomSigStartValue" SG_ 300 EPS_MODE_STAT "0200FFFF00000000h";
BA_ "GenSigCycleTime" SG_ 300 EPS_MODE_STAT 100;
BA_ "GenSigSNA" SG_ 300 EPS_MODE_STAT "7h";
BA_ "GenSigTimeout_CBC" SG_ 300 EPS_MODE_STAT 1050;
BA_ "FlexKomComment" SG_ 300 EPS_ModuleVoltage "EPS_A1_PKT";
BA_ "FlexKomIsMotorola" SG_ 300 EPS_ModuleVoltage 1;
BA_ "FlexKomSID" SG_ 300 EPS_ModuleVoltage 846;
BA_ "FlexKomSigLaenge" SG_ 300 EPS_ModuleVoltage 64;
BA_ "FlexKomSigName" SG_ 300 EPS_ModuleVoltage "EPS_A1_PKT";
BA_ "FlexKomSigStartPos" SG_ 300 EPS_ModuleVoltage 7;
BA_ "FlexKomSigStartValue" SG_ 300 EPS_ModuleVoltage "0200FFFF00000000h";
BA_ "GenSigCycleTime" SG_ 300 EPS_ModuleVoltage 100;
BA_ "GenSigSNA" SG_ 300 EPS_ModuleVoltage "FFh";
BA_ "GenSigStartValue" SG_ 300 EPS_ModuleVoltage 255;
BA_ "FlexKomComment" SG_ 300 EPS_Warn_Disp_Rq "EPS_A1_PKT";
BA_ "FlexKomIsMotorola" SG_ 300 EPS_Warn_Disp_Rq 1;
BA_ "FlexKomSID" SG_ 300 EPS_Warn_Disp_Rq 846;
BA_ "FlexKomSigLaenge" SG_ 300 EPS_Warn_Disp_Rq 64;
BA_ "FlexKomSigName" SG_ 300 EPS_Warn_Disp_Rq "EPS_A1_PKT";
BA_ "FlexKomSigStartPos" SG_ 300 EPS_Warn_Disp_Rq 7;
BA_ "FlexKomSigStartValue" SG_ 300 EPS_Warn_Disp_Rq "0200FFFF00000000h";
BA_ "GenSigCycleTime" SG_ 300 EPS_Warn_Disp_Rq 100;
BA_ "GenSigSNA" SG_ 300 EPS_Warn_Disp_Rq "7h";
BA_ "GenSigTimeout_CBC" SG_ 300 EPS_Warn_Disp_Rq 1050;
BA_ "GenSigTimeout_IC" SG_ 300 EPS_Warn_Disp_Rq 1050;
BA_ "GenSigTimeout_ORC" SG_ 300 EPS_Warn_Disp_Rq 350;
BA_ "RID" SG_ 300 EPS_Warn_Disp_Rq "*";
BA_ "FlexKomComment" SG_ 300 EngineFanRequestActivation "EPS_A1_PKT";
BA_ "FlexKomIsMotorola" SG_ 300 EngineFanRequestActivation 1;
BA_ "FlexKomSID" SG_ 300 EngineFanRequestActivation 846;
BA_ "FlexKomSigLaenge" SG_ 300 EngineFanRequestActivation 64;
BA_ "FlexKomSigName" SG_ 300 EngineFanRequestActivation "EPS_A1_PKT";
BA_ "FlexKomSigStartPos" SG_ 300 EngineFanRequestActivation 7;
BA_ "FlexKomSigStartValue" SG_ 300 EngineFanRequestActivation "0200FFFF00000000h";
BA_ "GenSigCycleTime" SG_ 300 EngineFanRequestActivation 100;
BA_ "GenSigSNA" SG_ 300 EngineFanRequestActivation "0h";
BA_ "FlexKomComment" SG_ 300 PS_SysType "EPS_A1_PKT";
BA_ "FlexKomIsMotorola" SG_ 300 PS_SysType 1;
BA_ "FlexKomSID" SG_ 300 PS_SysType 846;
BA_ "FlexKomSigLaenge" SG_ 300 PS_SysType 64;
BA_ "FlexKomSigName" SG_ 300 PS_SysType "EPS_A1_PKT";
BA_ "FlexKomSigStartPos" SG_ 300 PS_SysType 7;
BA_ "FlexKomSigStartValue" SG_ 300 PS_SysType "0200FFFF00000000h";
BA_ "GenSigCycleTime" SG_ 300 PS_SysType 100;
BA_ "GenSigSNA" SG_ 300 PS_SysType "0h";
BA_ "GenSigTimeout_IC" SG_ 300 PS_SysType 1050;
BA_ "RID" SG_ 300 PS_SysType "*";
BA_ "FlexKomComment" SG_ 463 CodeCheckStsESL "ESL code response packet";
BA_ "FlexKomIsMotorola" SG_ 463 CodeCheckStsESL 1;
BA_ "FlexKomSID" SG_ 463 CodeCheckStsESL 2367;
BA_ "FlexKomSigLaenge" SG_ 463 CodeCheckStsESL 40;
BA_ "FlexKomSigName" SG_ 463 CodeCheckStsESL "ESL_CodeRespPkt";
BA_ "FlexKomSigStartPos" SG_ 463 CodeCheckStsESL 7;
BA_ "FlexKomSigStartValue" SG_ 463 CodeCheckStsESL "0000000000h";
BA_ "GenSigSendType" SG_ 463 CodeCheckStsESL 1;
BA_ "GenSigSNA" SG_ 463 CodeCheckStsESL "0h";
BA_ "FlexKomComment" SG_ 463 ControlEncodingRspESL "ESL code response packet";
BA_ "FlexKomIsMotorola" SG_ 463 ControlEncodingRspESL 1;
BA_ "FlexKomSID" SG_ 463 ControlEncodingRspESL 2367;
BA_ "FlexKomSigLaenge" SG_ 463 ControlEncodingRspESL 40;
BA_ "FlexKomSigName" SG_ 463 ControlEncodingRspESL "ESL_CodeRespPkt";
BA_ "FlexKomSigStartPos" SG_ 463 ControlEncodingRspESL 7;
BA_ "FlexKomSigStartValue" SG_ 463 ControlEncodingRspESL "0000000000h";
BA_ "GenSigSendType" SG_ 463 ControlEncodingRspESL 1;
BA_ "GenSigSNA" SG_ 463 ControlEncodingRspESL "0h";
BA_ "FlexKomComment" SG_ 463 ESLFeedbackCmd "ESL code response packet";
BA_ "FlexKomIsMotorola" SG_ 463 ESLFeedbackCmd 1;
BA_ "FlexKomSID" SG_ 463 ESLFeedbackCmd 2367;
BA_ "FlexKomSigLaenge" SG_ 463 ESLFeedbackCmd 40;
BA_ "FlexKomSigName" SG_ 463 ESLFeedbackCmd "ESL_CodeRespPkt";
BA_ "FlexKomSigStartPos" SG_ 463 ESLFeedbackCmd 7;
BA_ "FlexKomSigStartValue" SG_ 463 ESLFeedbackCmd "0000000000h";
BA_ "GenSigSendType" SG_ 463 ESLFeedbackCmd 1;
BA_ "GenSigSNA" SG_ 463 ESLFeedbackCmd "7h";
BA_ "FlexKomComment" SG_ 463 ESLLockFailSts "ESL code response packet";
BA_ "FlexKomIsMotorola" SG_ 463 ESLLockFailSts 1;
BA_ "FlexKomSID" SG_ 463 ESLLockFailSts 2367;
BA_ "FlexKomSigLaenge" SG_ 463 ESLLockFailSts 40;
BA_ "FlexKomSigName" SG_ 463 ESLLockFailSts "ESL_CodeRespPkt";
BA_ "FlexKomSigStartPos" SG_ 463 ESLLockFailSts 7;
BA_ "FlexKomSigStartValue" SG_ 463 ESLLockFailSts "0000000000h";
BA_ "GenSigSendType" SG_ 463 ESLLockFailSts 1;
BA_ "GenSigSNA" SG_ 463 ESLLockFailSts "0h";
BA_ "FlexKomComment" SG_ 463 ESLUnlockFailSts "ESL code response packet";
BA_ "FlexKomIsMotorola" SG_ 463 ESLUnlockFailSts 1;
BA_ "FlexKomSID" SG_ 463 ESLUnlockFailSts 2367;
BA_ "FlexKomSigLaenge" SG_ 463 ESLUnlockFailSts 40;
BA_ "FlexKomSigName" SG_ 463 ESLUnlockFailSts "ESL_CodeRespPkt";
BA_ "FlexKomSigStartPos" SG_ 463 ESLUnlockFailSts 7;
BA_ "FlexKomSigStartValue" SG_ 463 ESLUnlockFailSts "0000000000h";
BA_ "GenSigSendType" SG_ 463 ESLUnlockFailSts 1;
BA_ "GenSigSNA" SG_ 463 ESLUnlockFailSts "0h";
BA_ "FlexKomComment" SG_ 463 ESL_ProgrammedSts "ESL code response packet";
BA_ "FlexKomIsMotorola" SG_ 463 ESL_ProgrammedSts 1;
BA_ "FlexKomSID" SG_ 463 ESL_ProgrammedSts 2367;
BA_ "FlexKomSigLaenge" SG_ 463 ESL_ProgrammedSts 40;
BA_ "FlexKomSigName" SG_ 463 ESL_ProgrammedSts "ESL_CodeRespPkt";
BA_ "FlexKomSigStartPos" SG_ 463 ESL_ProgrammedSts 7;
BA_ "FlexKomSigStartValue" SG_ 463 ESL_ProgrammedSts "0000000000h";
BA_ "GenSigSendType" SG_ 463 ESL_ProgrammedSts 1;
BA_ "GenSigSNA" SG_ 463 ESL_ProgrammedSts "0h";
BA_ "FlexKomComment" SG_ 463 MiniCryptGCodeESL "ESL code response packet";
BA_ "FlexKomIsMotorola" SG_ 463 MiniCryptGCodeESL 1;
BA_ "FlexKomSID" SG_ 463 MiniCryptGCodeESL 2367;
BA_ "FlexKomSigLaenge" SG_ 463 MiniCryptGCodeESL 40;
BA_ "FlexKomSigName" SG_ 463 MiniCryptGCodeESL "ESL_CodeRespPkt";
BA_ "FlexKomSigStartPos" SG_ 463 MiniCryptGCodeESL 7;
BA_ "FlexKomSigStartValue" SG_ 463 MiniCryptGCodeESL "0000000000h";
BA_ "GenSigSendType" SG_ 463 MiniCryptGCodeESL 1;
BA_ "GenSigSNA" SG_ 463 MiniCryptGCodeESL "0h";
BA_ "FlexKomComment" SG_ 320 ABS_BrkEvt "ESP Brake Status Information";
BA_ "FlexKomIsMotorola" SG_ 320 ABS_BrkEvt 1;
BA_ "FlexKomSigLaenge" SG_ 320 ABS_BrkEvt 64;
BA_ "FlexKomSigName" SG_ 320 ABS_BrkEvt "ESP_BRK_STAT";
BA_ "FlexKomSigStartPos" SG_ 320 ABS_BrkEvt 7;
BA_ "FlexKomSigStartValue" SG_ 320 ABS_BrkEvt "0F3400C003FF00FFh";
BA_ "GenSigCycleTime" SG_ 320 ABS_BrkEvt 20;
BA_ "GenSigSNA" SG_ 320 ABS_BrkEvt "0h";
BA_ "GenSigTimeout_ETM" SG_ 320 ABS_BrkEvt 210;
BA_ "GenSigTimeout_ORC" SG_ 320 ABS_BrkEvt 70;
BA_ "RID" SG_ 320 ABS_BrkEvt "5034";
BA_ "FlexKomComment" SG_ 320 BrkIntrvntn_Actv_AS "ESP Brake Status Information";
BA_ "FlexKomIsMotorola" SG_ 320 BrkIntrvntn_Actv_AS 1;
BA_ "FlexKomSigLaenge" SG_ 320 BrkIntrvntn_Actv_AS 64;
BA_ "FlexKomSigName" SG_ 320 BrkIntrvntn_Actv_AS "ESP_BRK_STAT";
BA_ "FlexKomSigStartPos" SG_ 320 BrkIntrvntn_Actv_AS 7;
BA_ "FlexKomSigStartValue" SG_ 320 BrkIntrvntn_Actv_AS "0F3400C003FF00FFh";
BA_ "GenSigCycleTime" SG_ 320 BrkIntrvntn_Actv_AS 20;
BA_ "GenSigSNA" SG_ 320 BrkIntrvntn_Actv_AS "0h";
BA_ "GenSigTimeout_ORC" SG_ 320 BrkIntrvntn_Actv_AS 70;
BA_ "FlexKomComment" SG_ 320 BrkIntrvntn_Actv_ESP "ESP Brake Status Information";
BA_ "FlexKomIsMotorola" SG_ 320 BrkIntrvntn_Actv_ESP 1;
BA_ "FlexKomSigLaenge" SG_ 320 BrkIntrvntn_Actv_ESP 64;
BA_ "FlexKomSigName" SG_ 320 BrkIntrvntn_Actv_ESP "ESP_BRK_STAT";
BA_ "FlexKomSigStartPos" SG_ 320 BrkIntrvntn_Actv_ESP 7;
BA_ "FlexKomSigStartValue" SG_ 320 BrkIntrvntn_Actv_ESP "0F3400C003FF00FFh";
BA_ "GenSigCycleTime" SG_ 320 BrkIntrvntn_Actv_ESP 20;
BA_ "GenSigSNA" SG_ 320 BrkIntrvntn_Actv_ESP "0h";
BA_ "GenSigTimeout_RHSC2" SG_ 320 BrkIntrvntn_Actv_ESP 210;
BA_ "GenSigTimeout_ORC" SG_ 320 BrkIntrvntn_Actv_ESP 70;
BA_ "FlexKomComment" SG_ 320 BrkIntrvntn_Enbl "ESP Brake Status Information";
BA_ "FlexKomIsMotorola" SG_ 320 BrkIntrvntn_Enbl 1;
BA_ "FlexKomSigLaenge" SG_ 320 BrkIntrvntn_Enbl 64;
BA_ "FlexKomSigName" SG_ 320 BrkIntrvntn_Enbl "ESP_BRK_STAT";
BA_ "FlexKomSigStartPos" SG_ 320 BrkIntrvntn_Enbl 7;
BA_ "FlexKomSigStartValue" SG_ 320 BrkIntrvntn_Enbl "0F3400C003FF00FFh";
BA_ "GenSigCycleTime" SG_ 320 BrkIntrvntn_Enbl 20;
BA_ "GenSigSNA" SG_ 320 BrkIntrvntn_Enbl "0h";
BA_ "GenSigTimeout_ORC" SG_ 320 BrkIntrvntn_Enbl 70;
BA_ "FlexKomComment" SG_ 320 BrkPdl_Flt "ESP Brake Status Information";
BA_ "FlexKomIsMotorola" SG_ 320 BrkPdl_Flt 1;
BA_ "FlexKomSigLaenge" SG_ 320 BrkPdl_Flt 64;
BA_ "FlexKomSigName" SG_ 320 BrkPdl_Flt "ESP_BRK_STAT";
BA_ "FlexKomSigStartPos" SG_ 320 BrkPdl_Flt 7;
BA_ "FlexKomSigStartValue" SG_ 320 BrkPdl_Flt "0F3400C003FF00FFh";
BA_ "GenSigCycleTime" SG_ 320 BrkPdl_Flt 20;
BA_ "GenSigSNA" SG_ 320 BrkPdl_Flt "0h";
BA_ "RID" SG_ 320 BrkPdl_Flt "5033";
BA_ "FlexKomComment" SG_ 320 BrkPdl_Stat "ESP Brake Status Information";
BA_ "FlexKomIsMotorola" SG_ 320 BrkPdl_Stat 1;
BA_ "FlexKomSigLaenge" SG_ 320 BrkPdl_Stat 64;
BA_ "FlexKomSigName" SG_ 320 BrkPdl_Stat "ESP_BRK_STAT";
BA_ "FlexKomSigStartPos" SG_ 320 BrkPdl_Stat 7;
BA_ "FlexKomSigStartValue" SG_ 320 BrkPdl_Stat "0F3400C003FF00FFh";
BA_ "GenSigCycleTime" SG_ 320 BrkPdl_Stat 20;
BA_ "GenSigSNA" SG_ 320 BrkPdl_Stat "3h";
BA_ "GenSigStartValue" SG_ 320 BrkPdl_Stat 3;
BA_ "GenSigTimeout_CBC" SG_ 320 BrkPdl_Stat 510;
BA_ "GenSigTimeout_RHSC2" SG_ 320 BrkPdl_Stat 210;
BA_ "GenSigTimeout_ETM" SG_ 320 BrkPdl_Stat 210;
BA_ "GenSigTimeout_IC" SG_ 320 BrkPdl_Stat 210;
BA_ "GenSigTimeout_ORC" SG_ 320 BrkPdl_Stat 70;
BA_ "RID" SG_ 320 BrkPdl_Stat "1135";
BA_ "FlexKomComment" SG_ 320 Brk_Stat "ESP Brake Status Information";
BA_ "FlexKomIsMotorola" SG_ 320 Brk_Stat 1;
BA_ "FlexKomSigLaenge" SG_ 320 Brk_Stat 64;
BA_ "FlexKomSigName" SG_ 320 Brk_Stat "ESP_BRK_STAT";
BA_ "FlexKomSigStartPos" SG_ 320 Brk_Stat 7;
BA_ "FlexKomSigStartValue" SG_ 320 Brk_Stat "0F3400C003FF00FFh";
BA_ "GenSigCycleTime" SG_ 320 Brk_Stat 20;
BA_ "GenSigSNA" SG_ 320 Brk_Stat "3h";
BA_ "GenSigStartValue" SG_ 320 Brk_Stat 3;
BA_ "GenSigTimeout_CBC" SG_ 320 Brk_Stat 210;
BA_ "GenSigTimeout_ORC" SG_ 320 Brk_Stat 70;
BA_ "RID" SG_ 320 Brk_Stat "1226";
BA_ "FlexKomComment" SG_ 320 Brk_Thermdl "ESP Brake Status Information";
BA_ "FlexKomIsMotorola" SG_ 320 Brk_Thermdl 1;
BA_ "FlexKomSigLaenge" SG_ 320 Brk_Thermdl 64;
BA_ "FlexKomSigName" SG_ 320 Brk_Thermdl "ESP_BRK_STAT";
BA_ "FlexKomSigStartPos" SG_ 320 Brk_Thermdl 7;
BA_ "FlexKomSigStartValue" SG_ 320 Brk_Thermdl "0F3400C003FF00FFh";
BA_ "GenSigCycleTime" SG_ 320 Brk_Thermdl 20;
BA_ "GenSigSNA" SG_ 320 Brk_Thermdl "0h";
BA_ "FlexKomComment" SG_ 320 CRC_Brk_Stat "ESP Brake Status Information";
BA_ "FlexKomIsMotorola" SG_ 320 CRC_Brk_Stat 1;
BA_ "FlexKomSigLaenge" SG_ 320 CRC_Brk_Stat 64;
BA_ "FlexKomSigName" SG_ 320 CRC_Brk_Stat "ESP_BRK_STAT";
BA_ "FlexKomSigStartPos" SG_ 320 CRC_Brk_Stat 7;
BA_ "FlexKomSigStartValue" SG_ 320 CRC_Brk_Stat "0F3400C003FF00FFh";
BA_ "GenSigCycleTime" SG_ 320 CRC_Brk_Stat 20;
BA_ "GenSigSNA" SG_ 320 CRC_Brk_Stat "FFh";
BA_ "GenSigStartValue" SG_ 320 CRC_Brk_Stat 255;
BA_ "GenSigTimeout_IC" SG_ 320 CRC_Brk_Stat 210;
BA_ "GenSigTimeout_ORC" SG_ 320 CRC_Brk_Stat 70;
BA_ "FlexKomComment" SG_ 320 DTR_CC_Enabled "ESP Brake Status Information";
BA_ "FlexKomIsMotorola" SG_ 320 DTR_CC_Enabled 1;
BA_ "FlexKomSigLaenge" SG_ 320 DTR_CC_Enabled 64;
BA_ "FlexKomSigName" SG_ 320 DTR_CC_Enabled "ESP_BRK_STAT";
BA_ "FlexKomSigStartPos" SG_ 320 DTR_CC_Enabled 7;
BA_ "FlexKomSigStartValue" SG_ 320 DTR_CC_Enabled "0F3400C003FF00FFh";
BA_ "GenSigCycleTime" SG_ 320 DTR_CC_Enabled 20;
BA_ "GenSigSNA" SG_ 320 DTR_CC_Enabled "0h";
BA_ "FlexKomComment" SG_ 320 DTR_CC_Engaged "ESP Brake Status Information";
BA_ "FlexKomIsMotorola" SG_ 320 DTR_CC_Engaged 1;
BA_ "FlexKomSigLaenge" SG_ 320 DTR_CC_Engaged 64;
BA_ "FlexKomSigName" SG_ 320 DTR_CC_Engaged "ESP_BRK_STAT";
BA_ "FlexKomSigStartPos" SG_ 320 DTR_CC_Engaged 7;
BA_ "FlexKomSigStartValue" SG_ 320 DTR_CC_Engaged "0F3400C003FF00FFh";
BA_ "GenSigCycleTime" SG_ 320 DTR_CC_Engaged 20;
BA_ "GenSigSNA" SG_ 320 DTR_CC_Engaged "0h";
BA_ "GenSigTimeout_ORC" SG_ 320 DTR_CC_Engaged 70;
BA_ "FlexKomComment" SG_ 320 ESP_Sys_Stat "ESP Brake Status Information";
BA_ "FlexKomIsMotorola" SG_ 320 ESP_Sys_Stat 1;
BA_ "FlexKomSigLaenge" SG_ 320 ESP_Sys_Stat 64;
BA_ "FlexKomSigName" SG_ 320 ESP_Sys_Stat "ESP_BRK_STAT";
BA_ "FlexKomSigStartPos" SG_ 320 ESP_Sys_Stat 7;
BA_ "FlexKomSigStartValue" SG_ 320 ESP_Sys_Stat "0F3400C003FF00FFh";
BA_ "GenSigCycleTime" SG_ 320 ESP_Sys_Stat 20;
BA_ "GenSigSNA" SG_ 320 ESP_Sys_Stat "1h";
BA_ "GenSigStartValue" SG_ 320 ESP_Sys_Stat 1;
BA_ "GenSigTimeout_IC" SG_ 320 ESP_Sys_Stat 210;
BA_ "GenSigTimeout_ORC" SG_ 320 ESP_Sys_Stat 70;
BA_ "FlexKomComment" SG_ 320 EmgBrk_Actv "ESP Brake Status Information";
BA_ "FlexKomIsMotorola" SG_ 320 EmgBrk_Actv 1;
BA_ "FlexKomSigLaenge" SG_ 320 EmgBrk_Actv 64;
BA_ "FlexKomSigName" SG_ 320 EmgBrk_Actv "ESP_BRK_STAT";
BA_ "FlexKomSigStartPos" SG_ 320 EmgBrk_Actv 7;
BA_ "FlexKomSigStartValue" SG_ 320 EmgBrk_Actv "0F3400C003FF00FFh";
BA_ "GenSigCycleTime" SG_ 320 EmgBrk_Actv 20;
BA_ "GenSigSNA" SG_ 320 EmgBrk_Actv "0h";
BA_ "GenSigTimeout_ORC" SG_ 320 EmgBrk_Actv 70;
BA_ "FlexKomComment" SG_ 320 FullBrk_Actv "ESP Brake Status Information";
BA_ "FlexKomIsMotorola" SG_ 320 FullBrk_Actv 1;
BA_ "FlexKomSigLaenge" SG_ 320 FullBrk_Actv 64;
BA_ "FlexKomSigName" SG_ 320 FullBrk_Actv "ESP_BRK_STAT";
BA_ "FlexKomSigStartPos" SG_ 320 FullBrk_Actv 7;
BA_ "FlexKomSigStartValue" SG_ 320 FullBrk_Actv "0F3400C003FF00FFh";
BA_ "GenSigCycleTime" SG_ 320 FullBrk_Actv 20;
BA_ "GenSigSNA" SG_ 320 FullBrk_Actv "0h";
BA_ "GenSigTimeout_CBC" SG_ 320 FullBrk_Actv 210;
BA_ "GenSigTimeout_IC" SG_ 320 FullBrk_Actv 210;
BA_ "GenSigTimeout_ORC" SG_ 320 FullBrk_Actv 70;
BA_ "FlexKomComment" SG_ 320 MC_Brk_Stat "ESP Brake Status Information";
BA_ "FlexKomIsMotorola" SG_ 320 MC_Brk_Stat 1;
BA_ "FlexKomSigLaenge" SG_ 320 MC_Brk_Stat 64;
BA_ "FlexKomSigName" SG_ 320 MC_Brk_Stat "ESP_BRK_STAT";
BA_ "FlexKomSigStartPos" SG_ 320 MC_Brk_Stat 7;
BA_ "FlexKomSigStartValue" SG_ 320 MC_Brk_Stat "0F3400C003FF00FFh";
BA_ "GenSigCycleTime" SG_ 320 MC_Brk_Stat 20;
BA_ "GenSigSNA" SG_ 320 MC_Brk_Stat "0h";
BA_ "GenSigTimeout_IC" SG_ 320 MC_Brk_Stat 210;
BA_ "GenSigTimeout_ORC" SG_ 320 MC_Brk_Stat 70;
BA_ "FlexKomComment" SG_ 320 REF_VEH_SPEED "ESP Brake Status Information";
BA_ "FlexKomIsMotorola" SG_ 320 REF_VEH_SPEED 1;
BA_ "FlexKomSigLaenge" SG_ 320 REF_VEH_SPEED 64;
BA_ "FlexKomSigName" SG_ 320 REF_VEH_SPEED "ESP_BRK_STAT";
BA_ "FlexKomSigStartPos" SG_ 320 REF_VEH_SPEED 7;
BA_ "FlexKomSigStartValue" SG_ 320 REF_VEH_SPEED "0F3400C003FF00FFh";
BA_ "GenSigCycleTime" SG_ 320 REF_VEH_SPEED 20;
BA_ "GenSigSNA" SG_ 320 REF_VEH_SPEED "3FFh";
BA_ "GenSigStartValue" SG_ 320 REF_VEH_SPEED 1023;
BA_ "GenSigTimeout_IC" SG_ 320 REF_VEH_SPEED 210;
BA_ "GenSigTimeout_ORC" SG_ 320 REF_VEH_SPEED 70;
BA_ "FlexKomComment" SG_ 320 RollTestMd_Actv "ESP Brake Status Information";
BA_ "FlexKomIsMotorola" SG_ 320 RollTestMd_Actv 1;
BA_ "FlexKomSigLaenge" SG_ 320 RollTestMd_Actv 64;
BA_ "FlexKomSigName" SG_ 320 RollTestMd_Actv "ESP_BRK_STAT";
BA_ "FlexKomSigStartPos" SG_ 320 RollTestMd_Actv 7;
BA_ "FlexKomSigStartValue" SG_ 320 RollTestMd_Actv "0F3400C003FF00FFh";
BA_ "GenSigCycleTime" SG_ 320 RollTestMd_Actv 20;
BA_ "GenSigSNA" SG_ 320 RollTestMd_Actv "3h";
BA_ "GenSigStartValue" SG_ 320 RollTestMd_Actv 3;
BA_ "FlexKomComment" SG_ 320 SPCR_AS_Off_Rq "ESP Brake Status Information";
BA_ "FlexKomIsMotorola" SG_ 320 SPCR_AS_Off_Rq 1;
BA_ "FlexKomSigLaenge" SG_ 320 SPCR_AS_Off_Rq 64;
BA_ "FlexKomSigName" SG_ 320 SPCR_AS_Off_Rq "ESP_BRK_STAT";
BA_ "FlexKomSigStartPos" SG_ 320 SPCR_AS_Off_Rq 7;
BA_ "FlexKomSigStartValue" SG_ 320 SPCR_AS_Off_Rq "0F3400C003FF00FFh";
BA_ "GenSigCycleTime" SG_ 320 SPCR_AS_Off_Rq 20;
BA_ "GenSigSNA" SG_ 320 SPCR_AS_Off_Rq "0h";
BA_ "FlexKomComment" SG_ 268 ASRActive "Engine torque request from ESC";
BA_ "FlexKomIsMotorola" SG_ 268 ASRActive 1;
BA_ "FlexKomSID" SG_ 268 ASRActive 1;
BA_ "FlexKomSigLaenge" SG_ 268 ASRActive 64;
BA_ "FlexKomSigName" SG_ 268 ASRActive "Eng_Trq_Rq";
BA_ "FlexKomSigStartPos" SG_ 268 ASRActive 7;
BA_ "FlexKomSigStartValue" SG_ 268 ASRActive "00000000FF0000FFh";
BA_ "GenSigCycleTime" SG_ 268 ASRActive 20;
BA_ "GenSigSNA" SG_ 268 ASRActive "0h";
BA_ "RID" SG_ 268 ASRActive "5029";
BA_ "FlexKomComment" SG_ 268 Brk_Jrk_Rsp "Engine torque request from ESC";
BA_ "FlexKomIsMotorola" SG_ 268 Brk_Jrk_Rsp 1;
BA_ "FlexKomSID" SG_ 268 Brk_Jrk_Rsp 1;
BA_ "FlexKomSigLaenge" SG_ 268 Brk_Jrk_Rsp 64;
BA_ "FlexKomSigName" SG_ 268 Brk_Jrk_Rsp "Eng_Trq_Rq";
BA_ "FlexKomSigStartPos" SG_ 268 Brk_Jrk_Rsp 7;
BA_ "FlexKomSigStartValue" SG_ 268 Brk_Jrk_Rsp "00000000FF0000FFh";
BA_ "GenSigCycleTime" SG_ 268 Brk_Jrk_Rsp 20;
BA_ "GenSigSNA" SG_ 268 Brk_Jrk_Rsp "0h";
BA_ "GenSigTimeout_ORC" SG_ 268 Brk_Jrk_Rsp 70;
BA_ "FlexKomComment" SG_ 268 CRC_ENG_RQ_ESC "Engine torque request from ESC";
BA_ "FlexKomIsMotorola" SG_ 268 CRC_ENG_RQ_ESC 1;
BA_ "FlexKomSID" SG_ 268 CRC_ENG_RQ_ESC 1;
BA_ "FlexKomSigLaenge" SG_ 268 CRC_ENG_RQ_ESC 64;
BA_ "FlexKomSigName" SG_ 268 CRC_ENG_RQ_ESC "Eng_Trq_Rq";
BA_ "FlexKomSigStartPos" SG_ 268 CRC_ENG_RQ_ESC 7;
BA_ "FlexKomSigStartValue" SG_ 268 CRC_ENG_RQ_ESC "00000000FF0000FFh";
BA_ "GenSigCycleTime" SG_ 268 CRC_ENG_RQ_ESC 20;
BA_ "GenSigSNA" SG_ 268 CRC_ENG_RQ_ESC "FFh";
BA_ "GenSigStartValue" SG_ 268 CRC_ENG_RQ_ESC 255;
BA_ "FlexKomComment" SG_ 268 DAS_Enbl_Rq "Engine torque request from ESC";
BA_ "FlexKomIsMotorola" SG_ 268 DAS_Enbl_Rq 1;
BA_ "FlexKomSID" SG_ 268 DAS_Enbl_Rq 1;
BA_ "FlexKomSigLaenge" SG_ 268 DAS_Enbl_Rq 64;
BA_ "FlexKomSigName" SG_ 268 DAS_Enbl_Rq "Eng_Trq_Rq";
BA_ "FlexKomSigStartPos" SG_ 268 DAS_Enbl_Rq 7;
BA_ "FlexKomSigStartValue" SG_ 268 DAS_Enbl_Rq "00000000FF0000FFh";
BA_ "GenSigCycleTime" SG_ 268 DAS_Enbl_Rq 20;
BA_ "GenSigSNA" SG_ 268 DAS_Enbl_Rq "0h";
BA_ "GenSigTimeout_ORC" SG_ 268 DAS_Enbl_Rq 70;
BA_ "FlexKomComment" SG_ 268 DAS_RqActv "Engine torque request from ESC";
BA_ "FlexKomIsMotorola" SG_ 268 DAS_RqActv 1;
BA_ "FlexKomSID" SG_ 268 DAS_RqActv 1;
BA_ "FlexKomSigLaenge" SG_ 268 DAS_RqActv 64;
BA_ "FlexKomSigName" SG_ 268 DAS_RqActv "Eng_Trq_Rq";
BA_ "FlexKomSigStartPos" SG_ 268 DAS_RqActv 7;
BA_ "FlexKomSigStartValue" SG_ 268 DAS_RqActv "00000000FF0000FFh";
BA_ "GenSigCycleTime" SG_ 268 DAS_RqActv 20;
BA_ "GenSigSNA" SG_ 268 DAS_RqActv "7h";
BA_ "GenSigTimeout_ORC" SG_ 268 DAS_RqActv 70;
BA_ "FlexKomComment" SG_ 268 EngTrqMax_Rq_ESC "Engine torque request from ESC";
BA_ "FlexKomIsMotorola" SG_ 268 EngTrqMax_Rq_ESC 1;
BA_ "FlexKomSID" SG_ 268 EngTrqMax_Rq_ESC 1;
BA_ "FlexKomSigLaenge" SG_ 268 EngTrqMax_Rq_ESC 64;
BA_ "FlexKomSigName" SG_ 268 EngTrqMax_Rq_ESC "Eng_Trq_Rq";
BA_ "FlexKomSigStartPos" SG_ 268 EngTrqMax_Rq_ESC 7;
BA_ "FlexKomSigStartValue" SG_ 268 EngTrqMax_Rq_ESC "00000000FF0000FFh";
BA_ "GenSigCycleTime" SG_ 268 EngTrqMax_Rq_ESC 20;
BA_ "GenSigSNA" SG_ 268 EngTrqMax_Rq_ESC "0h";
BA_ "FlexKomComment" SG_ 268 EngTrqMin_Rq_ESC "Engine torque request from ESC";
BA_ "FlexKomIsMotorola" SG_ 268 EngTrqMin_Rq_ESC 1;
BA_ "FlexKomSID" SG_ 268 EngTrqMin_Rq_ESC 1;
BA_ "FlexKomSigLaenge" SG_ 268 EngTrqMin_Rq_ESC 64;
BA_ "FlexKomSigName" SG_ 268 EngTrqMin_Rq_ESC "Eng_Trq_Rq";
BA_ "FlexKomSigStartPos" SG_ 268 EngTrqMin_Rq_ESC 7;
BA_ "FlexKomSigStartValue" SG_ 268 EngTrqMin_Rq_ESC "00000000FF0000FFh";
BA_ "GenSigCycleTime" SG_ 268 EngTrqMin_Rq_ESC 20;
BA_ "GenSigSNA" SG_ 268 EngTrqMin_Rq_ESC "0h";
BA_ "FlexKomComment" SG_ 268 EngTrq_Rq_ESC "Engine torque request from ESC";
BA_ "FlexKomIsMotorola" SG_ 268 EngTrq_Rq_ESC 1;
BA_ "FlexKomSID" SG_ 268 EngTrq_Rq_ESC 1;
BA_ "FlexKomSigLaenge" SG_ 268 EngTrq_Rq_ESC 64;
BA_ "FlexKomSigName" SG_ 268 EngTrq_Rq_ESC "Eng_Trq_Rq";
BA_ "FlexKomSigStartPos" SG_ 268 EngTrq_Rq_ESC 7;
BA_ "FlexKomSigStartValue" SG_ 268 EngTrq_Rq_ESC "00000000FF0000FFh";
BA_ "GenSigCycleTime" SG_ 268 EngTrq_Rq_ESC 20;
BA_ "GenSigSNA" SG_ 268 EngTrq_Rq_ESC "0h";
BA_ "GenSigTimeout_ETM" SG_ 268 EngTrq_Rq_ESC 210;
BA_ "FlexKomComment" SG_ 268 MC_ENG_RQ_ESC "Engine torque request from ESC";
BA_ "FlexKomIsMotorola" SG_ 268 MC_ENG_RQ_ESC 1;
BA_ "FlexKomSID" SG_ 268 MC_ENG_RQ_ESC 1;
BA_ "FlexKomSigLaenge" SG_ 268 MC_ENG_RQ_ESC 64;
BA_ "FlexKomSigName" SG_ 268 MC_ENG_RQ_ESC "Eng_Trq_Rq";
BA_ "FlexKomSigStartPos" SG_ 268 MC_ENG_RQ_ESC 7;
BA_ "FlexKomSigStartValue" SG_ 268 MC_ENG_RQ_ESC "00000000FF0000FFh";
BA_ "GenSigCycleTime" SG_ 268 MC_ENG_RQ_ESC 20;
BA_ "GenSigSNA" SG_ 268 MC_ENG_RQ_ESC "0h";
BA_ "FlexKomComment" SG_ 268 PrefillActive "Engine torque request from ESC";
BA_ "FlexKomIsMotorola" SG_ 268 PrefillActive 1;
BA_ "FlexKomSID" SG_ 268 PrefillActive 1;
BA_ "FlexKomSigLaenge" SG_ 268 PrefillActive 64;
BA_ "FlexKomSigName" SG_ 268 PrefillActive "Eng_Trq_Rq";
BA_ "FlexKomSigStartPos" SG_ 268 PrefillActive 7;
BA_ "FlexKomSigStartValue" SG_ 268 PrefillActive "00000000FF0000FFh";
BA_ "GenSigCycleTime" SG_ 268 PrefillActive 20;
BA_ "GenSigSNA" SG_ 268 PrefillActive "0h";
BA_ "FlexKomComment" SG_ 331 BrkPrss_TMC "ESC data";
BA_ "FlexKomIsMotorola" SG_ 331 BrkPrss_TMC 1;
BA_ "FlexKomSID" SG_ 331 BrkPrss_TMC 1416;
BA_ "FlexKomSigLaenge" SG_ 331 BrkPrss_TMC 64;
BA_ "FlexKomSigName" SG_ 331 BrkPrss_TMC "ESC_data";
BA_ "FlexKomSigStartPos" SG_ 331 BrkPrss_TMC 7;
BA_ "FlexKomSigStartValue" SG_ 331 BrkPrss_TMC "0000FFFF00FF00FFh";
BA_ "GenSigCycleTime" SG_ 331 BrkPrss_TMC 20;
BA_ "GenSigSNA" SG_ 331 BrkPrss_TMC "7FFh";
BA_ "GenSigTimeout_ETM" SG_ 331 BrkPrss_TMC 210;
BA_ "GenSigTimeout_IC" SG_ 331 BrkPrss_TMC 210;
BA_ "GenSigTimeout_ORC" SG_ 331 BrkPrss_TMC 70;
BA_ "FlexKomComment" SG_ 331 CRC_ESP_A3 "ESC data";
BA_ "FlexKomIsMotorola" SG_ 331 CRC_ESP_A3 1;
BA_ "FlexKomSID" SG_ 331 CRC_ESP_A3 1416;
BA_ "FlexKomSigLaenge" SG_ 331 CRC_ESP_A3 64;
BA_ "FlexKomSigName" SG_ 331 CRC_ESP_A3 "ESC_data";
BA_ "FlexKomSigStartPos" SG_ 331 CRC_ESP_A3 7;
BA_ "FlexKomSigStartValue" SG_ 331 CRC_ESP_A3 "0000FFFF00FF00FFh";
BA_ "GenSigCycleTime" SG_ 331 CRC_ESP_A3 20;
BA_ "GenSigSNA" SG_ 331 CRC_ESP_A3 "FFh";
BA_ "GenSigStartValue" SG_ 331 CRC_ESP_A3 255;
BA_ "GenSigTimeout_ORC" SG_ 331 CRC_ESP_A3 70;
BA_ "FlexKomComment" SG_ 331 HSA_BrkPrss "ESC data";
BA_ "FlexKomIsMotorola" SG_ 331 HSA_BrkPrss 1;
BA_ "FlexKomSID" SG_ 331 HSA_BrkPrss 1416;
BA_ "FlexKomSigLaenge" SG_ 331 HSA_BrkPrss 64;
BA_ "FlexKomSigName" SG_ 331 HSA_BrkPrss "ESC_data";
BA_ "FlexKomSigStartPos" SG_ 331 HSA_BrkPrss 7;
BA_ "FlexKomSigStartValue" SG_ 331 HSA_BrkPrss "0000FFFF00FF00FFh";
BA_ "GenSigCycleTime" SG_ 331 HSA_BrkPrss 20;
BA_ "GenSigSNA" SG_ 331 HSA_BrkPrss "3Fh";
BA_ "GenSigTimeout_ETM" SG_ 331 HSA_BrkPrss 210;
BA_ "GenSigTimeout_ORC" SG_ 331 HSA_BrkPrss 70;
BA_ "FlexKomComment" SG_ 331 MC_ESP_A3 "ESC data";
BA_ "FlexKomIsMotorola" SG_ 331 MC_ESP_A3 1;
BA_ "FlexKomSID" SG_ 331 MC_ESP_A3 1416;
BA_ "FlexKomSigLaenge" SG_ 331 MC_ESP_A3 64;
BA_ "FlexKomSigName" SG_ 331 MC_ESP_A3 "ESC_data";
BA_ "FlexKomSigStartPos" SG_ 331 MC_ESP_A3 7;
BA_ "FlexKomSigStartValue" SG_ 331 MC_ESP_A3 "0000FFFF00FF00FFh";
BA_ "GenSigCycleTime" SG_ 331 MC_ESP_A3 20;
BA_ "GenSigSNA" SG_ 331 MC_ESP_A3 "0h";
BA_ "GenSigTimeout_ORC" SG_ 331 MC_ESP_A3 70;
BA_ "FlexKomComment" SG_ 331 PTS_Brk_Rq_RspSts "ESC data";
BA_ "FlexKomIsMotorola" SG_ 331 PTS_Brk_Rq_RspSts 1;
BA_ "FlexKomSID" SG_ 331 PTS_Brk_Rq_RspSts 1416;
BA_ "FlexKomSigLaenge" SG_ 331 PTS_Brk_Rq_RspSts 64;
BA_ "FlexKomSigName" SG_ 331 PTS_Brk_Rq_RspSts "ESC_data";
BA_ "FlexKomSigStartPos" SG_ 331 PTS_Brk_Rq_RspSts 7;
BA_ "FlexKomSigStartValue" SG_ 331 PTS_Brk_Rq_RspSts "0000FFFF00FF00FFh";
BA_ "GenSigCycleTime" SG_ 331 PTS_Brk_Rq_RspSts 20;
BA_ "GenSigSNA" SG_ 331 PTS_Brk_Rq_RspSts "3h";
BA_ "GenSigTimeout_IC" SG_ 331 PTS_Brk_Rq_RspSts 210;
BA_ "GenSigTimeout_PTS" SG_ 331 PTS_Brk_Rq_RspSts 210;
BA_ "FlexKomComment" SG_ 332 MC_VEH_DYN_STAT "Message counter";
BA_ "FlexKomIsMotorola" SG_ 332 MC_VEH_DYN_STAT 1;
BA_ "FlexKomSID" SG_ 332 MC_VEH_DYN_STAT 1267;
BA_ "FlexKomSigLaenge" SG_ 332 MC_VEH_DYN_STAT 4;
BA_ "FlexKomSigName" SG_ 332 MC_VEH_DYN_STAT "MC_VEH_DYN_STAT";
BA_ "FlexKomSigStartPos" SG_ 332 MC_VEH_DYN_STAT 55;
BA_ "FlexKomSigStartValue" SG_ 332 MC_VEH_DYN_STAT "00h";
BA_ "GenSigCycleTime" SG_ 332 MC_VEH_DYN_STAT 20;
BA_ "GenSigSNA" SG_ 332 MC_VEH_DYN_STAT "0h";
BA_ "GenSigTimeout_ETM" SG_ 332 MC_VEH_DYN_STAT 210;
BA_ "GenSigTimeout_ORC" SG_ 332 MC_VEH_DYN_STAT 70;
BA_ "FlexKomComment" SG_ 332 VehAccel_X "Vehicle longitudinal acceleration (+ means forward";
BA_ "FlexKomIsMotorola" SG_ 332 VehAccel_X 1;
BA_ "FlexKomSID" SG_ 332 VehAccel_X 1265;
BA_ "FlexKomSigLaenge" SG_ 332 VehAccel_X 8;
BA_ "FlexKomSigName" SG_ 332 VehAccel_X "VehAccel_X";
BA_ "FlexKomSigStartPos" SG_ 332 VehAccel_X 39;
BA_ "FlexKomSigStartValue" SG_ 332 VehAccel_X "FFh";
BA_ "GenSigCycleTime" SG_ 332 VehAccel_X 20;
BA_ "GenSigSNA" SG_ 332 VehAccel_X "FFh";
BA_ "GenSigStartValue" SG_ 332 VehAccel_X 255;
BA_ "GenSigTimeout_CBC" SG_ 332 VehAccel_X 210;
BA_ "GenSigTimeout_IC" SG_ 332 VehAccel_X 210;
BA_ "GenSigTimeout_ORC" SG_ 332 VehAccel_X 70;
BA_ "RID" SG_ 332 VehAccel_X "1277";
BA_ "FlexKomComment" SG_ 332 VehAccel_X_Offset "Offset of vehicle longitudinal acceleration (+ mea";
BA_ "FlexKomIsMotorola" SG_ 332 VehAccel_X_Offset 1;
BA_ "FlexKomSID" SG_ 332 VehAccel_X_Offset 1264;
BA_ "FlexKomSigLaenge" SG_ 332 VehAccel_X_Offset 8;
BA_ "FlexKomSigName" SG_ 332 VehAccel_X_Offset "VehAccel_X_Offset";
BA_ "FlexKomSigStartPos" SG_ 332 VehAccel_X_Offset 31;
BA_ "FlexKomSigStartValue" SG_ 332 VehAccel_X_Offset "FFh";
BA_ "GenSigCycleTime" SG_ 332 VehAccel_X_Offset 20;
BA_ "GenSigSNA" SG_ 332 VehAccel_X_Offset "FFh";
BA_ "GenSigStartValue" SG_ 332 VehAccel_X_Offset 255;
BA_ "GenSigTimeout_ETM" SG_ 332 VehAccel_X_Offset 210;
BA_ "GenSigTimeout_IC" SG_ 332 VehAccel_X_Offset 210;
BA_ "GenSigTimeout_ORC" SG_ 332 VehAccel_X_Offset 70;
BA_ "FlexKomComment" SG_ 332 VehAccel_Y "Vehicle lateral acceleration (+ means left, specif";
BA_ "FlexKomIsMotorola" SG_ 332 VehAccel_Y 1;
BA_ "FlexKomSID" SG_ 332 VehAccel_Y 1266;
BA_ "FlexKomSigLaenge" SG_ 332 VehAccel_Y 8;
BA_ "FlexKomSigName" SG_ 332 VehAccel_Y "VehAccel_Y";
BA_ "FlexKomSigStartPos" SG_ 332 VehAccel_Y 47;
BA_ "FlexKomSigStartValue" SG_ 332 VehAccel_Y "FFh";
BA_ "GenSigCycleTime" SG_ 332 VehAccel_Y 20;
BA_ "GenSigSNA" SG_ 332 VehAccel_Y "FFh";
BA_ "GenSigStartValue" SG_ 332 VehAccel_Y 255;
BA_ "GenSigTimeout_CBC" SG_ 332 VehAccel_Y 210;
BA_ "GenSigTimeout_IC" SG_ 332 VehAccel_Y 210;
BA_ "GenSigTimeout_ORC" SG_ 332 VehAccel_Y 70;
BA_ "RID" SG_ 332 VehAccel_Y "1137";
BA_ "FlexKomComment" SG_ 332 VehAccel_Y_Offset "Offset of vehicle lateral acceleration (+ means le";
BA_ "FlexKomIsMotorola" SG_ 332 VehAccel_Y_Offset 1;
BA_ "FlexKomSID" SG_ 332 VehAccel_Y_Offset 1268;
BA_ "FlexKomSigLaenge" SG_ 332 VehAccel_Y_Offset 8;
BA_ "FlexKomSigName" SG_ 332 VehAccel_Y_Offset "VehAccel_Y_Offset";
BA_ "FlexKomSigStartPos" SG_ 332 VehAccel_Y_Offset 63;
BA_ "FlexKomSigStartValue" SG_ 332 VehAccel_Y_Offset "FFh";
BA_ "GenSigCycleTime" SG_ 332 VehAccel_Y_Offset 20;
BA_ "GenSigSNA" SG_ 332 VehAccel_Y_Offset "FFh";
BA_ "GenSigStartValue" SG_ 332 VehAccel_Y_Offset 255;
BA_ "GenSigTimeout_ETM" SG_ 332 VehAccel_Y_Offset 210;
BA_ "GenSigTimeout_IC" SG_ 332 VehAccel_Y_Offset 210;
BA_ "GenSigTimeout_ORC" SG_ 332 VehAccel_Y_Offset 70;
BA_ "FlexKomComment" SG_ 332 VehYawRate_Offset "Offset of vehicle yaw rate unfiltered/unadjusted (";
BA_ "FlexKomIsMotorola" SG_ 332 VehYawRate_Offset 1;
BA_ "FlexKomSID" SG_ 332 VehYawRate_Offset 1263;
BA_ "FlexKomSigLaenge" SG_ 332 VehYawRate_Offset 8;
BA_ "FlexKomSigName" SG_ 332 VehYawRate_Offset "VehYawRate_Offset";
BA_ "FlexKomSigStartPos" SG_ 332 VehYawRate_Offset 23;
BA_ "FlexKomSigStartValue" SG_ 332 VehYawRate_Offset "FFh";
BA_ "GenSigCycleTime" SG_ 332 VehYawRate_Offset 20;
BA_ "GenSigSNA" SG_ 332 VehYawRate_Offset "FFh";
BA_ "GenSigStartValue" SG_ 332 VehYawRate_Offset 255;
BA_ "GenSigTimeout_CBC" SG_ 332 VehYawRate_Offset 210;
BA_ "GenSigTimeout_ETM" SG_ 332 VehYawRate_Offset 210;
BA_ "GenSigTimeout_IC" SG_ 332 VehYawRate_Offset 210;
BA_ "GenSigTimeout_ORC" SG_ 332 VehYawRate_Offset 70;
BA_ "RID" SG_ 332 VehYawRate_Offset "1299 1710 5037";
BA_ "FlexKomComment" SG_ 332 VehYawRate_Raw "Vehicle yaw rate unfiltered/unadjusted (+ means le";
BA_ "FlexKomIsMotorola" SG_ 332 VehYawRate_Raw 1;
BA_ "FlexKomSID" SG_ 332 VehYawRate_Raw 1262;
BA_ "FlexKomSigLaenge" SG_ 332 VehYawRate_Raw 16;
BA_ "FlexKomSigName" SG_ 332 VehYawRate_Raw "VehYawRate_Raw";
BA_ "FlexKomSigStartPos" SG_ 332 VehYawRate_Raw 7;
BA_ "FlexKomSigStartValue" SG_ 332 VehYawRate_Raw "FFFFh";
BA_ "GenSigCycleTime" SG_ 332 VehYawRate_Raw 20;
BA_ "GenSigSNA" SG_ 332 VehYawRate_Raw "FFFFh";
BA_ "GenSigStartValue" SG_ 332 VehYawRate_Raw 65535;
BA_ "GenSigTimeout_CBC" SG_ 332 VehYawRate_Raw 210;
BA_ "GenSigTimeout_IC" SG_ 332 VehYawRate_Raw 210;
BA_ "GenSigTimeout_ORC" SG_ 332 VehYawRate_Raw 70;
BA_ "RID" SG_ 332 VehYawRate_Raw "1058 1289 1711";
BA_ "FlexKomComment" SG_ 292 WhlPlsCnt_FL "ESP Wheel pulse counts";
BA_ "FlexKomIsMotorola" SG_ 292 WhlPlsCnt_FL 1;
BA_ "FlexKomSID" SG_ 292 WhlPlsCnt_FL 65;
BA_ "FlexKomSigLaenge" SG_ 292 WhlPlsCnt_FL 32;
BA_ "FlexKomSigName" SG_ 292 WhlPlsCnt_FL "ESP_WHL_PULS";
BA_ "FlexKomSigStartPos" SG_ 292 WhlPlsCnt_FL 7;
BA_ "FlexKomSigStartValue" SG_ 292 WhlPlsCnt_FL "00000000h";
BA_ "GenSigCycleTime" SG_ 292 WhlPlsCnt_FL 20;
BA_ "GenSigSNA" SG_ 292 WhlPlsCnt_FL "FFh";
BA_ "GenSigTimeout_CBC" SG_ 292 WhlPlsCnt_FL 210;
BA_ "GenSigTimeout_IC" SG_ 292 WhlPlsCnt_FL 210;
BA_ "RID" SG_ 292 WhlPlsCnt_FL "1251";
BA_ "FlexKomComment" SG_ 292 WhlPlsCnt_FR "ESP Wheel pulse counts";
BA_ "FlexKomIsMotorola" SG_ 292 WhlPlsCnt_FR 1;
BA_ "FlexKomSID" SG_ 292 WhlPlsCnt_FR 65;
BA_ "FlexKomSigLaenge" SG_ 292 WhlPlsCnt_FR 32;
BA_ "FlexKomSigName" SG_ 292 WhlPlsCnt_FR "ESP_WHL_PULS";
BA_ "FlexKomSigStartPos" SG_ 292 WhlPlsCnt_FR 7;
BA_ "FlexKomSigStartValue" SG_ 292 WhlPlsCnt_FR "00000000h";
BA_ "GenSigCycleTime" SG_ 292 WhlPlsCnt_FR 20;
BA_ "GenSigSNA" SG_ 292 WhlPlsCnt_FR "FFh";
BA_ "GenSigTimeout_CBC" SG_ 292 WhlPlsCnt_FR 210;
BA_ "GenSigTimeout_IC" SG_ 292 WhlPlsCnt_FR 210;
BA_ "RID" SG_ 292 WhlPlsCnt_FR "1086";
BA_ "FlexKomComment" SG_ 292 WhlPlsCnt_RL "ESP Wheel pulse counts";
BA_ "FlexKomIsMotorola" SG_ 292 WhlPlsCnt_RL 1;
BA_ "FlexKomSID" SG_ 292 WhlPlsCnt_RL 65;
BA_ "FlexKomSigLaenge" SG_ 292 WhlPlsCnt_RL 32;
BA_ "FlexKomSigName" SG_ 292 WhlPlsCnt_RL "ESP_WHL_PULS";
BA_ "FlexKomSigStartPos" SG_ 292 WhlPlsCnt_RL 7;
BA_ "FlexKomSigStartValue" SG_ 292 WhlPlsCnt_RL "00000000h";
BA_ "GenSigCycleTime" SG_ 292 WhlPlsCnt_RL 20;
BA_ "GenSigSNA" SG_ 292 WhlPlsCnt_RL "FFh";
BA_ "GenSigTimeout_CBC" SG_ 292 WhlPlsCnt_RL 210;
BA_ "GenSigTimeout_IC" SG_ 292 WhlPlsCnt_RL 210;
BA_ "RID" SG_ 292 WhlPlsCnt_RL "1049";
BA_ "FlexKomComment" SG_ 292 WhlPlsCnt_RR "ESP Wheel pulse counts";
BA_ "FlexKomIsMotorola" SG_ 292 WhlPlsCnt_RR 1;
BA_ "FlexKomSID" SG_ 292 WhlPlsCnt_RR 65;
BA_ "FlexKomSigLaenge" SG_ 292 WhlPlsCnt_RR 32;
BA_ "FlexKomSigName" SG_ 292 WhlPlsCnt_RR "ESP_WHL_PULS";
BA_ "FlexKomSigStartPos" SG_ 292 WhlPlsCnt_RR 7;
BA_ "FlexKomSigStartValue" SG_ 292 WhlPlsCnt_RR "00000000h";
BA_ "GenSigCycleTime" SG_ 292 WhlPlsCnt_RR 20;
BA_ "GenSigSNA" SG_ 292 WhlPlsCnt_RR "FFh";
BA_ "GenSigTimeout_CBC" SG_ 292 WhlPlsCnt_RR 210;
BA_ "GenSigTimeout_IC" SG_ 292 WhlPlsCnt_RR 210;
BA_ "RID" SG_ 292 WhlPlsCnt_RR "1047";
BA_ "FlexKomComment" SG_ 344 WhlDir_FL_Stat "ESP Wheel Speed";
BA_ "FlexKomIsMotorola" SG_ 344 WhlDir_FL_Stat 1;
BA_ "FlexKomSID" SG_ 344 WhlDir_FL_Stat 64;
BA_ "FlexKomSigLaenge" SG_ 344 WhlDir_FL_Stat 64;
BA_ "FlexKomSigName" SG_ 344 WhlDir_FL_Stat "WHEEL_SPEED";
BA_ "FlexKomSigStartPos" SG_ 344 WhlDir_FL_Stat 7;
BA_ "FlexKomSigStartValue" SG_ 344 WhlDir_FL_Stat "FFFFFFFFFFFFFFFFh";
BA_ "GenSigCycleTime" SG_ 344 WhlDir_FL_Stat 20;
BA_ "GenSigSNA" SG_ 344 WhlDir_FL_Stat "3h";
BA_ "GenSigStartValue" SG_ 344 WhlDir_FL_Stat 3;
BA_ "GenSigTimeout_ORC" SG_ 344 WhlDir_FL_Stat 70;
BA_ "FlexKomComment" SG_ 344 WhlDir_FR_Stat "ESP Wheel Speed";
BA_ "FlexKomIsMotorola" SG_ 344 WhlDir_FR_Stat 1;
BA_ "FlexKomSID" SG_ 344 WhlDir_FR_Stat 64;
BA_ "FlexKomSigLaenge" SG_ 344 WhlDir_FR_Stat 64;
BA_ "FlexKomSigName" SG_ 344 WhlDir_FR_Stat "WHEEL_SPEED";
BA_ "FlexKomSigStartPos" SG_ 344 WhlDir_FR_Stat 7;
BA_ "FlexKomSigStartValue" SG_ 344 WhlDir_FR_Stat "FFFFFFFFFFFFFFFFh";
BA_ "GenSigCycleTime" SG_ 344 WhlDir_FR_Stat 20;
BA_ "GenSigSNA" SG_ 344 WhlDir_FR_Stat "3h";
BA_ "GenSigStartValue" SG_ 344 WhlDir_FR_Stat 3;
BA_ "GenSigTimeout_ORC" SG_ 344 WhlDir_FR_Stat 70;
BA_ "FlexKomComment" SG_ 344 WhlDir_RL_Stat "ESP Wheel Speed";
BA_ "FlexKomIsMotorola" SG_ 344 WhlDir_RL_Stat 1;
BA_ "FlexKomSID" SG_ 344 WhlDir_RL_Stat 64;
BA_ "FlexKomSigLaenge" SG_ 344 WhlDir_RL_Stat 64;
BA_ "FlexKomSigName" SG_ 344 WhlDir_RL_Stat "WHEEL_SPEED";
BA_ "FlexKomSigStartPos" SG_ 344 WhlDir_RL_Stat 7;
BA_ "FlexKomSigStartValue" SG_ 344 WhlDir_RL_Stat "FFFFFFFFFFFFFFFFh";
BA_ "GenSigCycleTime" SG_ 344 WhlDir_RL_Stat 20;
BA_ "GenSigSNA" SG_ 344 WhlDir_RL_Stat "3h";
BA_ "GenSigStartValue" SG_ 344 WhlDir_RL_Stat 3;
BA_ "GenSigTimeout_ORC" SG_ 344 WhlDir_RL_Stat 70;
BA_ "RID" SG_ 344 WhlDir_RL_Stat "9775";
BA_ "FlexKomComment" SG_ 344 WhlDir_RR_Stat "ESP Wheel Speed";
BA_ "FlexKomIsMotorola" SG_ 344 WhlDir_RR_Stat 1;
BA_ "FlexKomSID" SG_ 344 WhlDir_RR_Stat 64;
BA_ "FlexKomSigLaenge" SG_ 344 WhlDir_RR_Stat 64;
BA_ "FlexKomSigName" SG_ 344 WhlDir_RR_Stat "WHEEL_SPEED";
BA_ "FlexKomSigStartPos" SG_ 344 WhlDir_RR_Stat 7;
BA_ "FlexKomSigStartValue" SG_ 344 WhlDir_RR_Stat "FFFFFFFFFFFFFFFFh";
BA_ "GenSigCycleTime" SG_ 344 WhlDir_RR_Stat 20;
BA_ "GenSigSNA" SG_ 344 WhlDir_RR_Stat "3h";
BA_ "GenSigStartValue" SG_ 344 WhlDir_RR_Stat 3;
BA_ "GenSigTimeout_ORC" SG_ 344 WhlDir_RR_Stat 70;
BA_ "RID" SG_ 344 WhlDir_RR_Stat "9776";
BA_ "FlexKomComment" SG_ 344 WhlRPM_FL "ESP Wheel Speed";
BA_ "FlexKomIsMotorola" SG_ 344 WhlRPM_FL 1;
BA_ "FlexKomSID" SG_ 344 WhlRPM_FL 64;
BA_ "FlexKomSigLaenge" SG_ 344 WhlRPM_FL 64;
BA_ "FlexKomSigName" SG_ 344 WhlRPM_FL "WHEEL_SPEED";
BA_ "FlexKomSigStartPos" SG_ 344 WhlRPM_FL 7;
BA_ "FlexKomSigStartValue" SG_ 344 WhlRPM_FL "FFFFFFFFFFFFFFFFh";
BA_ "GenSigCycleTime" SG_ 344 WhlRPM_FL 20;
BA_ "GenSigSNA" SG_ 344 WhlRPM_FL "3FFFh";
BA_ "GenSigStartValue" SG_ 344 WhlRPM_FL 16383;
BA_ "GenSigTimeout_ESL" SG_ 344 WhlRPM_FL 210;
BA_ "GenSigTimeout_ORC" SG_ 344 WhlRPM_FL 70;
BA_ "FlexKomComment" SG_ 344 WhlRPM_FR "ESP Wheel Speed";
BA_ "FlexKomIsMotorola" SG_ 344 WhlRPM_FR 1;
BA_ "FlexKomSID" SG_ 344 WhlRPM_FR 64;
BA_ "FlexKomSigLaenge" SG_ 344 WhlRPM_FR 64;
BA_ "FlexKomSigName" SG_ 344 WhlRPM_FR "WHEEL_SPEED";
BA_ "FlexKomSigStartPos" SG_ 344 WhlRPM_FR 7;
BA_ "FlexKomSigStartValue" SG_ 344 WhlRPM_FR "FFFFFFFFFFFFFFFFh";
BA_ "GenSigCycleTime" SG_ 344 WhlRPM_FR 20;
BA_ "GenSigSNA" SG_ 344 WhlRPM_FR "3FFFh";
BA_ "GenSigStartValue" SG_ 344 WhlRPM_FR 16383;
BA_ "GenSigTimeout_ESL" SG_ 344 WhlRPM_FR 210;
BA_ "GenSigTimeout_ORC" SG_ 344 WhlRPM_FR 70;
BA_ "FlexKomComment" SG_ 344 WhlRPM_RL "ESP Wheel Speed";
BA_ "FlexKomIsMotorola" SG_ 344 WhlRPM_RL 1;
BA_ "FlexKomSID" SG_ 344 WhlRPM_RL 64;
BA_ "FlexKomSigLaenge" SG_ 344 WhlRPM_RL 64;
BA_ "FlexKomSigName" SG_ 344 WhlRPM_RL "WHEEL_SPEED";
BA_ "FlexKomSigStartPos" SG_ 344 WhlRPM_RL 7;
BA_ "FlexKomSigStartValue" SG_ 344 WhlRPM_RL "FFFFFFFFFFFFFFFFh";
BA_ "GenSigCycleTime" SG_ 344 WhlRPM_RL 20;
BA_ "GenSigSNA" SG_ 344 WhlRPM_RL "3FFFh";
BA_ "GenSigStartValue" SG_ 344 WhlRPM_RL 16383;
BA_ "GenSigTimeout_CBC" SG_ 344 WhlRPM_RL 110;
BA_ "GenSigTimeout_ESL" SG_ 344 WhlRPM_RL 210;
BA_ "GenSigTimeout_ORC" SG_ 344 WhlRPM_RL 70;
BA_ "FlexKomComment" SG_ 344 WhlRPM_RR "ESP Wheel Speed";
BA_ "FlexKomIsMotorola" SG_ 344 WhlRPM_RR 1;
BA_ "FlexKomSID" SG_ 344 WhlRPM_RR 64;
BA_ "FlexKomSigLaenge" SG_ 344 WhlRPM_RR 64;
BA_ "FlexKomSigName" SG_ 344 WhlRPM_RR "WHEEL_SPEED";
BA_ "FlexKomSigStartPos" SG_ 344 WhlRPM_RR 7;
BA_ "FlexKomSigStartValue" SG_ 344 WhlRPM_RR "FFFFFFFFFFFFFFFFh";
BA_ "GenSigCycleTime" SG_ 344 WhlRPM_RR 20;
BA_ "GenSigSNA" SG_ 344 WhlRPM_RR "3FFFh";
BA_ "GenSigStartValue" SG_ 344 WhlRPM_RR 16383;
BA_ "GenSigTimeout_CBC" SG_ 344 WhlRPM_RR 110;
BA_ "GenSigTimeout_ESL" SG_ 344 WhlRPM_RR 210;
BA_ "GenSigTimeout_ORC" SG_ 344 WhlRPM_RR 70;
BA_ "FlexKomComment" SG_ 284 BrkTrq "Vehicle Speed Packet";
BA_ "FlexKomIsMotorola" SG_ 284 BrkTrq 1;
BA_ "FlexKomSID" SG_ 284 BrkTrq 9006;
BA_ "FlexKomSigLaenge" SG_ 284 BrkTrq 64;
BA_ "FlexKomSigName" SG_ 284 BrkTrq "VEH_SPEED_PKT";
BA_ "FlexKomSigStartPos" SG_ 284 BrkTrq 7;
BA_ "FlexKomSigStartValue" SG_ 284 BrkTrq "0FFF0FFFFFFF00FFh";
BA_ "GenSigCycleTime" SG_ 284 BrkTrq 20;
BA_ "GenSigSNA" SG_ 284 BrkTrq "FFFh";
BA_ "GenSigStartValue" SG_ 284 BrkTrq 4095;
BA_ "GenSigTimeout_CBC" SG_ 284 BrkTrq 210;
BA_ "FlexKomComment" SG_ 284 BrkTrq_D "Vehicle Speed Packet";
BA_ "FlexKomIsMotorola" SG_ 284 BrkTrq_D 1;
BA_ "FlexKomSID" SG_ 284 BrkTrq_D 9006;
BA_ "FlexKomSigLaenge" SG_ 284 BrkTrq_D 64;
BA_ "FlexKomSigName" SG_ 284 BrkTrq_D "VEH_SPEED_PKT";
BA_ "FlexKomSigStartPos" SG_ 284 BrkTrq_D 7;
BA_ "FlexKomSigStartValue" SG_ 284 BrkTrq_D "0FFF0FFFFFFF00FFh";
BA_ "GenSigCycleTime" SG_ 284 BrkTrq_D 20;
BA_ "GenSigSNA" SG_ 284 BrkTrq_D "FFFh";
BA_ "GenSigStartValue" SG_ 284 BrkTrq_D 4095;
BA_ "FlexKomComment" SG_ 284 CRC_VEH_SPEED "Vehicle Speed Packet";
BA_ "FlexKomIsMotorola" SG_ 284 CRC_VEH_SPEED 1;
BA_ "FlexKomSID" SG_ 284 CRC_VEH_SPEED 9006;
BA_ "FlexKomSigLaenge" SG_ 284 CRC_VEH_SPEED 64;
BA_ "FlexKomSigName" SG_ 284 CRC_VEH_SPEED "VEH_SPEED_PKT";
BA_ "FlexKomSigStartPos" SG_ 284 CRC_VEH_SPEED 7;
BA_ "FlexKomSigStartValue" SG_ 284 CRC_VEH_SPEED "0FFF0FFFFFFF00FFh";
BA_ "GenSigCycleTime" SG_ 284 CRC_VEH_SPEED 20;
BA_ "GenSigSNA" SG_ 284 CRC_VEH_SPEED "FFh";
BA_ "GenSigStartValue" SG_ 284 CRC_VEH_SPEED 255;
BA_ "GenSigTimeout_CBC" SG_ 284 CRC_VEH_SPEED 110;
BA_ "GenSigTimeout_EPS" SG_ 284 CRC_VEH_SPEED 210;
BA_ "GenSigTimeout_ESL" SG_ 284 CRC_VEH_SPEED 110;
BA_ "GenSigTimeout_IC" SG_ 284 CRC_VEH_SPEED 210;
BA_ "GenSigTimeout_ORC" SG_ 284 CRC_VEH_SPEED 70;
BA_ "FlexKomComment" SG_ 284 MC_VEH_SPEED "Vehicle Speed Packet";
BA_ "FlexKomIsMotorola" SG_ 284 MC_VEH_SPEED 1;
BA_ "FlexKomSID" SG_ 284 MC_VEH_SPEED 9006;
BA_ "FlexKomSigLaenge" SG_ 284 MC_VEH_SPEED 64;
BA_ "FlexKomSigName" SG_ 284 MC_VEH_SPEED "VEH_SPEED_PKT";
BA_ "FlexKomSigStartPos" SG_ 284 MC_VEH_SPEED 7;
BA_ "FlexKomSigStartValue" SG_ 284 MC_VEH_SPEED "0FFF0FFFFFFF00FFh";
BA_ "GenSigCycleTime" SG_ 284 MC_VEH_SPEED 20;
BA_ "GenSigSNA" SG_ 284 MC_VEH_SPEED "0h";
BA_ "GenSigTimeout_CBC" SG_ 284 MC_VEH_SPEED 110;
BA_ "GenSigTimeout_EPS" SG_ 284 MC_VEH_SPEED 210;
BA_ "GenSigTimeout_ESL" SG_ 284 MC_VEH_SPEED 110;
BA_ "GenSigTimeout_IC" SG_ 284 MC_VEH_SPEED 210;
BA_ "GenSigTimeout_ORC" SG_ 284 MC_VEH_SPEED 70;
BA_ "RID" SG_ 284 MC_VEH_SPEED "9748";
BA_ "FlexKomComment" SG_ 284 VEH_SPEED "Vehicle Speed Packet";
BA_ "FlexKomIsMotorola" SG_ 284 VEH_SPEED 1;
BA_ "FlexKomSID" SG_ 284 VEH_SPEED 9006;
BA_ "FlexKomSigLaenge" SG_ 284 VEH_SPEED 64;
BA_ "FlexKomSigName" SG_ 284 VEH_SPEED "VEH_SPEED_PKT";
BA_ "FlexKomSigStartPos" SG_ 284 VEH_SPEED 7;
BA_ "FlexKomSigStartValue" SG_ 284 VEH_SPEED "0FFF0FFFFFFF00FFh";
BA_ "GenSigCycleTime" SG_ 284 VEH_SPEED 20;
BA_ "GenSigSNA" SG_ 284 VEH_SPEED "FFFFh";
BA_ "GenSigStartValue" SG_ 284 VEH_SPEED 65535;
BA_ "GenSigTimeout_CBC" SG_ 284 VEH_SPEED 110;
BA_ "GenSigTimeout_EPS" SG_ 284 VEH_SPEED 210;
BA_ "GenSigTimeout_ESL" SG_ 284 VEH_SPEED 110;
BA_ "GenSigTimeout_IC" SG_ 284 VEH_SPEED 210;
BA_ "GenSigTimeout_ORC" SG_ 284 VEH_SPEED 70;
BA_ "GenSigTimeout_RF_HUB" SG_ 284 VEH_SPEED 210;
BA_ "RID" SG_ 284 VEH_SPEED "2861 2862 2863";
BA_ "FlexKomComment" SG_ 284 VehSpSts "Vehicle Speed Packet";
BA_ "FlexKomIsMotorola" SG_ 284 VehSpSts 1;
BA_ "FlexKomSID" SG_ 284 VehSpSts 9006;
BA_ "FlexKomSigLaenge" SG_ 284 VehSpSts 64;
BA_ "FlexKomSigName" SG_ 284 VehSpSts "VEH_SPEED_PKT";
BA_ "FlexKomSigStartPos" SG_ 284 VehSpSts 7;
BA_ "FlexKomSigStartValue" SG_ 284 VehSpSts "0FFF0FFFFFFF00FFh";
BA_ "GenSigCycleTime" SG_ 284 VehSpSts 20;
BA_ "GenSigSNA" SG_ 284 VehSpSts "0h";
BA_ "FlexKomComment" SG_ 270 AHH_Status "ESP_A9_Pkt";
BA_ "FlexKomIsMotorola" SG_ 270 AHH_Status 1;
BA_ "FlexKomSID" SG_ 270 AHH_Status 2519;
BA_ "FlexKomSigLaenge" SG_ 270 AHH_Status 64;
BA_ "FlexKomSigName" SG_ 270 AHH_Status "ESP_A9_Pkt";
BA_ "FlexKomSigStartPos" SG_ 270 AHH_Status 7;
BA_ "FlexKomSigStartValue" SG_ 270 AHH_Status "00000000000000FFh";
BA_ "GenSigCycleTime" SG_ 270 AHH_Status 20;
BA_ "GenSigSNA" SG_ 270 AHH_Status "7h";
BA_ "FlexKomComment" SG_ 270 CRC_10Eh "ESP_A9_Pkt";
BA_ "FlexKomIsMotorola" SG_ 270 CRC_10Eh 1;
BA_ "FlexKomSID" SG_ 270 CRC_10Eh 2519;
BA_ "FlexKomSigLaenge" SG_ 270 CRC_10Eh 64;
BA_ "FlexKomSigName" SG_ 270 CRC_10Eh "ESP_A9_Pkt";
BA_ "FlexKomSigStartPos" SG_ 270 CRC_10Eh 7;
BA_ "FlexKomSigStartValue" SG_ 270 CRC_10Eh "00000000000000FFh";
BA_ "GenSigCycleTime" SG_ 270 CRC_10Eh 20;
BA_ "GenSigSNA" SG_ 270 CRC_10Eh "FFh";
BA_ "GenSigStartValue" SG_ 270 CRC_10Eh 255;
BA_ "FlexKomComment" SG_ 270 MC_10Eh "ESP_A9_Pkt";
BA_ "FlexKomIsMotorola" SG_ 270 MC_10Eh 1;
BA_ "FlexKomSID" SG_ 270 MC_10Eh 2519;
BA_ "FlexKomSigLaenge" SG_ 270 MC_10Eh 64;
BA_ "FlexKomSigName" SG_ 270 MC_10Eh "ESP_A9_Pkt";
BA_ "FlexKomSigStartPos" SG_ 270 MC_10Eh 7;
BA_ "FlexKomSigStartValue" SG_ 270 MC_10Eh "00000000000000FFh";
BA_ "GenSigCycleTime" SG_ 270 MC_10Eh 20;
BA_ "GenSigSNA" SG_ 270 MC_10Eh "0h";
BA_ "FlexKomComment" SG_ 270 WhlTrqAct_Rq_AS "ESP_A9_Pkt";
BA_ "FlexKomIsMotorola" SG_ 270 WhlTrqAct_Rq_AS 1;
BA_ "FlexKomSID" SG_ 270 WhlTrqAct_Rq_AS 2519;
BA_ "FlexKomSigLaenge" SG_ 270 WhlTrqAct_Rq_AS 64;
BA_ "FlexKomSigName" SG_ 270 WhlTrqAct_Rq_AS "ESP_A9_Pkt";
BA_ "FlexKomSigStartPos" SG_ 270 WhlTrqAct_Rq_AS 7;
BA_ "FlexKomSigStartValue" SG_ 270 WhlTrqAct_Rq_AS "00000000000000FFh";
BA_ "GenSigCycleTime" SG_ 270 WhlTrqAct_Rq_AS 20;
BA_ "GenSigSNA" SG_ 270 WhlTrqAct_Rq_AS "0h";
BA_ "FlexKomComment" SG_ 270 WhlTrqMax_Rq_ESC "ESP_A9_Pkt";
BA_ "FlexKomIsMotorola" SG_ 270 WhlTrqMax_Rq_ESC 1;
BA_ "FlexKomSID" SG_ 270 WhlTrqMax_Rq_ESC 2519;
BA_ "FlexKomSigLaenge" SG_ 270 WhlTrqMax_Rq_ESC 64;
BA_ "FlexKomSigName" SG_ 270 WhlTrqMax_Rq_ESC "ESP_A9_Pkt";
BA_ "FlexKomSigStartPos" SG_ 270 WhlTrqMax_Rq_ESC 7;
BA_ "FlexKomSigStartValue" SG_ 270 WhlTrqMax_Rq_ESC "00000000000000FFh";
BA_ "GenSigCycleTime" SG_ 270 WhlTrqMax_Rq_ESC 20;
BA_ "GenSigSNA" SG_ 270 WhlTrqMax_Rq_ESC "0h";
BA_ "GenSigTimeout_ORC" SG_ 270 WhlTrqMax_Rq_ESC 70;
BA_ "FlexKomComment" SG_ 270 WhlTrqMin_Rq_ESC "ESP_A9_Pkt";
BA_ "FlexKomIsMotorola" SG_ 270 WhlTrqMin_Rq_ESC 1;
BA_ "FlexKomSID" SG_ 270 WhlTrqMin_Rq_ESC 2519;
BA_ "FlexKomSigLaenge" SG_ 270 WhlTrqMin_Rq_ESC 64;
BA_ "FlexKomSigName" SG_ 270 WhlTrqMin_Rq_ESC "ESP_A9_Pkt";
BA_ "FlexKomSigStartPos" SG_ 270 WhlTrqMin_Rq_ESC 7;
BA_ "FlexKomSigStartValue" SG_ 270 WhlTrqMin_Rq_ESC "00000000000000FFh";
BA_ "GenSigCycleTime" SG_ 270 WhlTrqMin_Rq_ESC 20;
BA_ "GenSigSNA" SG_ 270 WhlTrqMin_Rq_ESC "0h";
BA_ "FlexKomComment" SG_ 270 WhlTrq_Rq_As "ESP_A9_Pkt";
BA_ "FlexKomIsMotorola" SG_ 270 WhlTrq_Rq_As 1;
BA_ "FlexKomSID" SG_ 270 WhlTrq_Rq_As 2519;
BA_ "FlexKomSigLaenge" SG_ 270 WhlTrq_Rq_As 64;
BA_ "FlexKomSigName" SG_ 270 WhlTrq_Rq_As "ESP_A9_Pkt";
BA_ "FlexKomSigStartPos" SG_ 270 WhlTrq_Rq_As 7;
BA_ "FlexKomSigStartValue" SG_ 270 WhlTrq_Rq_As "00000000000000FFh";
BA_ "GenSigCycleTime" SG_ 270 WhlTrq_Rq_As 20;
BA_ "GenSigSNA" SG_ 270 WhlTrq_Rq_As "7FFFh";
BA_ "GenSigTimeout_ORC" SG_ 270 WhlTrq_Rq_As 70;
BA_ "FlexKomComment" SG_ 270 WhlTrq_Rq_ESC "ESP_A9_Pkt";
BA_ "FlexKomIsMotorola" SG_ 270 WhlTrq_Rq_ESC 1;
BA_ "FlexKomSID" SG_ 270 WhlTrq_Rq_ESC 2519;
BA_ "FlexKomSigLaenge" SG_ 270 WhlTrq_Rq_ESC 64;
BA_ "FlexKomSigName" SG_ 270 WhlTrq_Rq_ESC "ESP_A9_Pkt";
BA_ "FlexKomSigStartPos" SG_ 270 WhlTrq_Rq_ESC 7;
BA_ "FlexKomSigStartValue" SG_ 270 WhlTrq_Rq_ESC "00000000000000FFh";
BA_ "GenSigCycleTime" SG_ 270 WhlTrq_Rq_ESC 20;
BA_ "GenSigSNA" SG_ 270 WhlTrq_Rq_ESC "7FFFh";
BA_ "FlexKomComment" SG_ 736 ABS_IndLmp_On_Rq "ESP Customer Indicators";
BA_ "FlexKomIsMotorola" SG_ 736 ABS_IndLmp_On_Rq 1;
BA_ "FlexKomSID" SG_ 736 ABS_IndLmp_On_Rq 397;
BA_ "FlexKomSigLaenge" SG_ 736 ABS_IndLmp_On_Rq 16;
BA_ "FlexKomSigName" SG_ 736 ABS_IndLmp_On_Rq "ESP_HMI";
BA_ "FlexKomSigStartPos" SG_ 736 ABS_IndLmp_On_Rq 55;
BA_ "FlexKomSigStartValue" SG_ 736 ABS_IndLmp_On_Rq "003Fh";
BA_ "GenSigCycleTime" SG_ 736 ABS_IndLmp_On_Rq 50;
BA_ "GenSigSNA" SG_ 736 ABS_IndLmp_On_Rq "3h";
BA_ "GenSigStartValue" SG_ 736 ABS_IndLmp_On_Rq 3;
BA_ "GenSigTimeout_ETM" SG_ 736 ABS_IndLmp_On_Rq 525;
BA_ "GenSigTimeout_IC" SG_ 736 ABS_IndLmp_On_Rq 275;
BA_ "FlexKomComment" SG_ 736 BrkIndLmp_On_Rq_ESC "ESP Customer Indicators";
BA_ "FlexKomIsMotorola" SG_ 736 BrkIndLmp_On_Rq_ESC 1;
BA_ "FlexKomSID" SG_ 736 BrkIndLmp_On_Rq_ESC 397;
BA_ "FlexKomSigLaenge" SG_ 736 BrkIndLmp_On_Rq_ESC 16;
BA_ "FlexKomSigName" SG_ 736 BrkIndLmp_On_Rq_ESC "ESP_HMI";
BA_ "FlexKomSigStartPos" SG_ 736 BrkIndLmp_On_Rq_ESC 55;
BA_ "FlexKomSigStartValue" SG_ 736 BrkIndLmp_On_Rq_ESC "003Fh";
BA_ "GenSigCycleTime" SG_ 736 BrkIndLmp_On_Rq_ESC 50;
BA_ "GenSigSNA" SG_ 736 BrkIndLmp_On_Rq_ESC "3h";
BA_ "GenSigStartValue" SG_ 736 BrkIndLmp_On_Rq_ESC 3;
BA_ "GenSigTimeout_ETM" SG_ 736 BrkIndLmp_On_Rq_ESC 525;
BA_ "GenSigTimeout_IC" SG_ 736 BrkIndLmp_On_Rq_ESC 275;
BA_ "FlexKomComment" SG_ 736 ESC_CtrlLmp_Info "ESP Customer Indicators";
BA_ "FlexKomIsMotorola" SG_ 736 ESC_CtrlLmp_Info 1;
BA_ "FlexKomSID" SG_ 736 ESC_CtrlLmp_Info 397;
BA_ "FlexKomSigLaenge" SG_ 736 ESC_CtrlLmp_Info 16;
BA_ "FlexKomSigName" SG_ 736 ESC_CtrlLmp_Info "ESP_HMI";
BA_ "FlexKomSigStartPos" SG_ 736 ESC_CtrlLmp_Info 55;
BA_ "FlexKomSigStartValue" SG_ 736 ESC_CtrlLmp_Info "003Fh";
BA_ "GenSigCycleTime" SG_ 736 ESC_CtrlLmp_Info 50;
BA_ "GenSigSNA" SG_ 736 ESC_CtrlLmp_Info "3h";
BA_ "GenSigStartValue" SG_ 736 ESC_CtrlLmp_Info 3;
BA_ "GenSigTimeout_ETM" SG_ 736 ESC_CtrlLmp_Info 525;
BA_ "GenSigTimeout_IC" SG_ 736 ESC_CtrlLmp_Info 275;
BA_ "GenSigTimeout_ORC" SG_ 736 ESC_CtrlLmp_Info 175;
BA_ "FlexKomComment" SG_ 736 ESP_Off_IndLmp_On_Rq "ESP Customer Indicators";
BA_ "FlexKomIsMotorola" SG_ 736 ESP_Off_IndLmp_On_Rq 1;
BA_ "FlexKomSID" SG_ 736 ESP_Off_IndLmp_On_Rq 397;
BA_ "FlexKomSigLaenge" SG_ 736 ESP_Off_IndLmp_On_Rq 16;
BA_ "FlexKomSigName" SG_ 736 ESP_Off_IndLmp_On_Rq "ESP_HMI";
BA_ "FlexKomSigStartPos" SG_ 736 ESP_Off_IndLmp_On_Rq 55;
BA_ "FlexKomSigStartValue" SG_ 736 ESP_Off_IndLmp_On_Rq "003Fh";
BA_ "GenSigCycleTime" SG_ 736 ESP_Off_IndLmp_On_Rq 50;
BA_ "GenSigSNA" SG_ 736 ESP_Off_IndLmp_On_Rq "0h";
BA_ "GenSigTimeout_ETM" SG_ 736 ESP_Off_IndLmp_On_Rq 525;
BA_ "GenSigTimeout_IC" SG_ 736 ESP_Off_IndLmp_On_Rq 275;
BA_ "GenSigTimeout_ORC" SG_ 736 ESP_Off_IndLmp_On_Rq 175;
BA_ "RID" SG_ 736 ESP_Off_IndLmp_On_Rq "1988";
BA_ "FlexKomComment" SG_ 736 HSA_EN "ESP feature present and enabled";
BA_ "FlexKomIsMotorola" SG_ 736 HSA_EN 1;
BA_ "FlexKomSID" SG_ 736 HSA_EN 396;
BA_ "FlexKomSigLaenge" SG_ 736 HSA_EN 8;
BA_ "FlexKomSigName" SG_ 736 HSA_EN "EBC_Feature_Status";
BA_ "FlexKomSigStartPos" SG_ 736 HSA_EN 47;
BA_ "FlexKomSigStartValue" SG_ 736 HSA_EN "00h";
BA_ "GenSigCycleTime" SG_ 736 HSA_EN 50;
BA_ "GenSigSNA" SG_ 736 HSA_EN "0h";
BA_ "GenSigTimeout_IC" SG_ 736 HSA_EN 525;
BA_ "RID" SG_ 736 HSA_EN "1063";
BA_ "FlexKomComment" SG_ 736 LT_DIST "Distance traveled by wheels";
BA_ "FlexKomIsMotorola" SG_ 736 LT_DIST 1;
BA_ "FlexKomSID" SG_ 736 LT_DIST 395;
BA_ "FlexKomSigLaenge" SG_ 736 LT_DIST 32;
BA_ "FlexKomSigName" SG_ 736 LT_DIST "ESP_DIST";
BA_ "FlexKomSigStartPos" SG_ 736 LT_DIST 7;
BA_ "FlexKomSigStartValue" SG_ 736 LT_DIST "FFFFFFFFh";
BA_ "GenSigCycleTime" SG_ 736 LT_DIST 50;
BA_ "GenSigSNA" SG_ 736 LT_DIST "FFFFh";
BA_ "GenSigStartValue" SG_ 736 LT_DIST 65535;
BA_ "GenSigTimeout_CBC" SG_ 736 LT_DIST 525;
BA_ "GenSigTimeout_IC" SG_ 736 LT_DIST 525;
BA_ "GenSigTimeout_PTS" SG_ 736 LT_DIST 525;
BA_ "RID" SG_ 736 LT_DIST "1233";
BA_ "FlexKomComment" SG_ 736 RT_DIST "Distance traveled by wheels";
BA_ "FlexKomIsMotorola" SG_ 736 RT_DIST 1;
BA_ "FlexKomSID" SG_ 736 RT_DIST 395;
BA_ "FlexKomSigLaenge" SG_ 736 RT_DIST 32;
BA_ "FlexKomSigName" SG_ 736 RT_DIST "ESP_DIST";
BA_ "FlexKomSigStartPos" SG_ 736 RT_DIST 7;
BA_ "FlexKomSigStartValue" SG_ 736 RT_DIST "FFFFFFFFh";
BA_ "GenSigCycleTime" SG_ 736 RT_DIST 50;
BA_ "GenSigSNA" SG_ 736 RT_DIST "FFFFh";
BA_ "GenSigStartValue" SG_ 736 RT_DIST 65535;
BA_ "GenSigTimeout_CBC" SG_ 736 RT_DIST 525;
BA_ "GenSigTimeout_IC" SG_ 736 RT_DIST 525;
BA_ "GenSigTimeout_PTS" SG_ 736 RT_DIST 525;
BA_ "RID" SG_ 736 RT_DIST "1113";
BA_ "FlexKomComment" SG_ 736 YRS_DataRq "Request from ESC for YRS information";
BA_ "FlexKomIsMotorola" SG_ 736 YRS_DataRq 1;
BA_ "FlexKomSID" SG_ 736 YRS_DataRq 1589;
BA_ "FlexKomSigLaenge" SG_ 736 YRS_DataRq 1;
BA_ "FlexKomSigName" SG_ 736 YRS_DataRq "YRS_DataRq";
BA_ "FlexKomSigStartPos" SG_ 736 YRS_DataRq 32;
BA_ "FlexKomSigStartValue" SG_ 736 YRS_DataRq "00h";
BA_ "GenSigCycleTime" SG_ 736 YRS_DataRq 50;
BA_ "GenSigSNA" SG_ 736 YRS_DataRq "0h";
BA_ "GenSigTimeout_ORC" SG_ 736 YRS_DataRq 175;
BA_ "FlexKomComment" SG_ 737 ESCSysEmsMlfAtv "ESC emissions related malfunction active";
BA_ "FlexKomIsMotorola" SG_ 737 ESCSysEmsMlfAtv 1;
BA_ "FlexKomSID" SG_ 737 ESCSysEmsMlfAtv 2376;
BA_ "FlexKomSigLaenge" SG_ 737 ESCSysEmsMlfAtv 1;
BA_ "FlexKomSigName" SG_ 737 ESCSysEmsMlfAtv "ESCSysEmsMlfAtv";
BA_ "FlexKomSigStartPos" SG_ 737 ESCSysEmsMlfAtv 18;
BA_ "FlexKomSigStartValue" SG_ 737 ESCSysEmsMlfAtv "00h";
BA_ "GenSigCycleTime" SG_ 737 ESCSysEmsMlfAtv 100;
BA_ "GenSigSNA" SG_ 737 ESCSysEmsMlfAtv "0h";
BA_ "FlexKomComment" SG_ 737 MIL_OnRq_ESC "MIL on request from the ESC";
BA_ "FlexKomIsMotorola" SG_ 737 MIL_OnRq_ESC 1;
BA_ "FlexKomSID" SG_ 737 MIL_OnRq_ESC 2375;
BA_ "FlexKomSigLaenge" SG_ 737 MIL_OnRq_ESC 1;
BA_ "FlexKomSigName" SG_ 737 MIL_OnRq_ESC "MIL_OnRq_ESC";
BA_ "FlexKomSigStartPos" SG_ 737 MIL_OnRq_ESC 2;
BA_ "FlexKomSigStartValue" SG_ 737 MIL_OnRq_ESC "00h";
BA_ "GenSigCycleTime" SG_ 737 MIL_OnRq_ESC 100;
BA_ "GenSigSNA" SG_ 737 MIL_OnRq_ESC "0h";
BA_ "FlexKomComment" SG_ 682 BrakeSysStatePrim "Message ESP_B5 packet";
BA_ "FlexKomIsMotorola" SG_ 682 BrakeSysStatePrim 1;
BA_ "FlexKomSID" SG_ 682 BrakeSysStatePrim 9205;
BA_ "FlexKomSigLaenge" SG_ 682 BrakeSysStatePrim 64;
BA_ "FlexKomSigName" SG_ 682 BrakeSysStatePrim "ESP_B5_Pkt";
BA_ "FlexKomSigStartPos" SG_ 682 BrakeSysStatePrim 7;
BA_ "FlexKomSigStartValue" SG_ 682 BrakeSysStatePrim "FFFF8000000000FFh";
BA_ "GenSigCycleTime" SG_ 682 BrakeSysStatePrim 20;
BA_ "GenSigSNA" SG_ 682 BrakeSysStatePrim "7h";
BA_ "GenSigTimeout_RHSC2" SG_ 682 BrakeSysStatePrim 70;
BA_ "FlexKomComment" SG_ 682 CRC_ESP_B5 "Message ESP_B5 packet";
BA_ "FlexKomIsMotorola" SG_ 682 CRC_ESP_B5 1;
BA_ "FlexKomSID" SG_ 682 CRC_ESP_B5 9205;
BA_ "FlexKomSigLaenge" SG_ 682 CRC_ESP_B5 64;
BA_ "FlexKomSigName" SG_ 682 CRC_ESP_B5 "ESP_B5_Pkt";
BA_ "FlexKomSigStartPos" SG_ 682 CRC_ESP_B5 7;
BA_ "FlexKomSigStartValue" SG_ 682 CRC_ESP_B5 "FFFF8000000000FFh";
BA_ "GenSigCycleTime" SG_ 682 CRC_ESP_B5 20;
BA_ "GenSigSNA" SG_ 682 CRC_ESP_B5 "FFh";
BA_ "GenSigStartValue" SG_ 682 CRC_ESP_B5 255;
BA_ "GenSigTimeout_RHSC2" SG_ 682 CRC_ESP_B5 70;
BA_ "FlexKomComment" SG_ 682 ESC_BrakeState "Message ESP_B5 packet";
BA_ "FlexKomIsMotorola" SG_ 682 ESC_BrakeState 1;
BA_ "FlexKomSID" SG_ 682 ESC_BrakeState 9205;
BA_ "FlexKomSigLaenge" SG_ 682 ESC_BrakeState 64;
BA_ "FlexKomSigName" SG_ 682 ESC_BrakeState "ESP_B5_Pkt";
BA_ "FlexKomSigStartPos" SG_ 682 ESC_BrakeState 7;
BA_ "FlexKomSigStartValue" SG_ 682 ESC_BrakeState "FFFF8000000000FFh";
BA_ "GenSigCycleTime" SG_ 682 ESC_BrakeState 20;
BA_ "GenSigSNA" SG_ 682 ESC_BrakeState "7h";
BA_ "GenSigTimeout_RHSC2" SG_ 682 ESC_BrakeState 70;
BA_ "FlexKomComment" SG_ 682 EsBrakeTorqueAppliedPrim "Message ESP_B5 packet";
BA_ "FlexKomIsMotorola" SG_ 682 EsBrakeTorqueAppliedPrim 1;
BA_ "FlexKomSID" SG_ 682 EsBrakeTorqueAppliedPrim 9205;
BA_ "FlexKomSigLaenge" SG_ 682 EsBrakeTorqueAppliedPrim 64;
BA_ "FlexKomSigName" SG_ 682 EsBrakeTorqueAppliedPrim "ESP_B5_Pkt";
BA_ "FlexKomSigStartPos" SG_ 682 EsBrakeTorqueAppliedPrim 7;
BA_ "FlexKomSigStartValue" SG_ 682 EsBrakeTorqueAppliedPrim "FFFF8000000000FFh";
BA_ "GenSigCycleTime" SG_ 682 EsBrakeTorqueAppliedPrim 20;
BA_ "GenSigSNA" SG_ 682 EsBrakeTorqueAppliedPrim "0h";
BA_ "FlexKomComment" SG_ 682 HoldSufficientStatus "Message ESP_B5 packet";
BA_ "FlexKomIsMotorola" SG_ 682 HoldSufficientStatus 1;
BA_ "FlexKomSID" SG_ 682 HoldSufficientStatus 9205;
BA_ "FlexKomSigLaenge" SG_ 682 HoldSufficientStatus 64;
BA_ "FlexKomSigName" SG_ 682 HoldSufficientStatus "ESP_B5_Pkt";
BA_ "FlexKomSigStartPos" SG_ 682 HoldSufficientStatus 7;
BA_ "FlexKomSigStartValue" SG_ 682 HoldSufficientStatus "FFFF8000000000FFh";
BA_ "GenSigCycleTime" SG_ 682 HoldSufficientStatus 20;
BA_ "GenSigSNA" SG_ 682 HoldSufficientStatus "0h";
BA_ "FlexKomComment" SG_ 682 MC_ESP_B5 "Message ESP_B5 packet";
BA_ "FlexKomIsMotorola" SG_ 682 MC_ESP_B5 1;
BA_ "FlexKomSID" SG_ 682 MC_ESP_B5 9205;
BA_ "FlexKomSigLaenge" SG_ 682 MC_ESP_B5 64;
BA_ "FlexKomSigName" SG_ 682 MC_ESP_B5 "ESP_B5_Pkt";
BA_ "FlexKomSigStartPos" SG_ 682 MC_ESP_B5 7;
BA_ "FlexKomSigStartValue" SG_ 682 MC_ESP_B5 "FFFF8000000000FFh";
BA_ "GenSigCycleTime" SG_ 682 MC_ESP_B5 20;
BA_ "GenSigSNA" SG_ 682 MC_ESP_B5 "0h";
BA_ "GenSigTimeout_RHSC2" SG_ 682 MC_ESP_B5 70;
BA_ "FlexKomComment" SG_ 682 SDS_Engaged_State_ESC "Message ESP_B5 packet";
BA_ "FlexKomIsMotorola" SG_ 682 SDS_Engaged_State_ESC 1;
BA_ "FlexKomSID" SG_ 682 SDS_Engaged_State_ESC 9205;
BA_ "FlexKomSigLaenge" SG_ 682 SDS_Engaged_State_ESC 64;
BA_ "FlexKomSigName" SG_ 682 SDS_Engaged_State_ESC "ESP_B5_Pkt";
BA_ "FlexKomSigStartPos" SG_ 682 SDS_Engaged_State_ESC 7;
BA_ "FlexKomSigStartValue" SG_ 682 SDS_Engaged_State_ESC "FFFF8000000000FFh";
BA_ "GenSigCycleTime" SG_ 682 SDS_Engaged_State_ESC 20;
BA_ "GenSigSNA" SG_ 682 SDS_Engaged_State_ESC "3h";
BA_ "GenSigTimeout_RHSC2" SG_ 682 SDS_Engaged_State_ESC 70;
BA_ "FlexKomComment" SG_ 682 ThermalCapacityPrim "Message ESP_B5 packet";
BA_ "FlexKomIsMotorola" SG_ 682 ThermalCapacityPrim 1;
BA_ "FlexKomSID" SG_ 682 ThermalCapacityPrim 9205;
BA_ "FlexKomSigLaenge" SG_ 682 ThermalCapacityPrim 64;
BA_ "FlexKomSigName" SG_ 682 ThermalCapacityPrim "ESP_B5_Pkt";
BA_ "FlexKomSigStartPos" SG_ 682 ThermalCapacityPrim 7;
BA_ "FlexKomSigStartValue" SG_ 682 ThermalCapacityPrim "FFFF8000000000FFh";
BA_ "GenSigCycleTime" SG_ 682 ThermalCapacityPrim 20;
BA_ "GenSigSNA" SG_ 682 ThermalCapacityPrim "0h";
BA_ "FlexKomComment" SG_ 682 qTargetExternal "Message ESP_B5 packet";
BA_ "FlexKomIsMotorola" SG_ 682 qTargetExternal 1;
BA_ "FlexKomSID" SG_ 682 qTargetExternal 9205;
BA_ "FlexKomSigLaenge" SG_ 682 qTargetExternal 64;
BA_ "FlexKomSigName" SG_ 682 qTargetExternal "ESP_B5_Pkt";
BA_ "FlexKomSigStartPos" SG_ 682 qTargetExternal 7;
BA_ "FlexKomSigStartValue" SG_ 682 qTargetExternal "FFFF8000000000FFh";
BA_ "GenSigCycleTime" SG_ 682 qTargetExternal 20;
BA_ "GenSigSNA" SG_ 682 qTargetExternal "0h";
BA_ "FlexKomComment" SG_ 682 qTargetExternal_Active "Message ESP_B5 packet";
BA_ "FlexKomIsMotorola" SG_ 682 qTargetExternal_Active 1;
BA_ "FlexKomSID" SG_ 682 qTargetExternal_Active 9205;
BA_ "FlexKomSigLaenge" SG_ 682 qTargetExternal_Active 64;
BA_ "FlexKomSigName" SG_ 682 qTargetExternal_Active "ESP_B5_Pkt";
BA_ "FlexKomSigStartPos" SG_ 682 qTargetExternal_Active 7;
BA_ "FlexKomSigStartValue" SG_ 682 qTargetExternal_Active "FFFF8000000000FFh";
BA_ "GenSigCycleTime" SG_ 682 qTargetExternal_Active 20;
BA_ "GenSigSNA" SG_ 682 qTargetExternal_Active "0h";
BA_ "FlexKomComment" SG_ 840 FailSafeError "Fail safe error";
BA_ "FlexKomIsMotorola" SG_ 840 FailSafeError 1;
BA_ "FlexKomSID" SG_ 840 FailSafeError 13;
BA_ "FlexKomSigLaenge" SG_ 840 FailSafeError 16;
BA_ "FlexKomSigName" SG_ 840 FailSafeError "FailSafeError";
BA_ "FlexKomSigStartPos" SG_ 840 FailSafeError 7;
BA_ "FlexKomSigStartValue" SG_ 840 FailSafeError "0000h";
BA_ "GenSigSendType" SG_ 840 FailSafeError 1;
BA_ "GenSigSNA" SG_ 840 FailSafeError "FFFFh";
BA_ "FlexKomComment" SG_ 1016 EC_BU_CBC1A "Backup for CBC ecu configuration 1";
BA_ "FlexKomIsMotorola" SG_ 1016 EC_BU_CBC1A 1;
BA_ "FlexKomSID" SG_ 1016 EC_BU_CBC1A 907;
BA_ "FlexKomSigLaenge" SG_ 1016 EC_BU_CBC1A 32;
BA_ "FlexKomSigName" SG_ 1016 EC_BU_CBC1A "EC_BU_CBC1";
BA_ "FlexKomSigStartPos" SG_ 1016 EC_BU_CBC1A 7;
BA_ "FlexKomSigStartValue" SG_ 1016 EC_BU_CBC1A "00000000h";
BA_ "GenSigSendType" SG_ 1016 EC_BU_CBC1A 1;
BA_ "GenSigSNA" SG_ 1016 EC_BU_CBC1A "0h";
BA_ "FlexKomComment" SG_ 1016 EC_BU_CBC1B "Backup for CBC ecu configuration 1";
BA_ "FlexKomIsMotorola" SG_ 1016 EC_BU_CBC1B 1;
BA_ "FlexKomSID" SG_ 1016 EC_BU_CBC1B 907;
BA_ "FlexKomSigLaenge" SG_ 1016 EC_BU_CBC1B 32;
BA_ "FlexKomSigName" SG_ 1016 EC_BU_CBC1B "EC_BU_CBC1";
BA_ "FlexKomSigStartPos" SG_ 1016 EC_BU_CBC1B 7;
BA_ "FlexKomSigStartValue" SG_ 1016 EC_BU_CBC1B "00000000h";
BA_ "GenSigSendType" SG_ 1016 EC_BU_CBC1B 1;
BA_ "GenSigSNA" SG_ 1016 EC_BU_CBC1B "0h";
BA_ "FlexKomComment" SG_ 1016 EC_BU_CBC2 "Backup for CBC ecu configuration 2";
BA_ "FlexKomIsMotorola" SG_ 1016 EC_BU_CBC2 1;
BA_ "FlexKomSID" SG_ 1016 EC_BU_CBC2 908;
BA_ "FlexKomSigLaenge" SG_ 1016 EC_BU_CBC2 32;
BA_ "FlexKomSigName" SG_ 1016 EC_BU_CBC2 "EC_BU_CBC2";
BA_ "FlexKomSigStartPos" SG_ 1016 EC_BU_CBC2 39;
BA_ "FlexKomSigStartValue" SG_ 1016 EC_BU_CBC2 "00000000h";
BA_ "GenSigSendType" SG_ 1016 EC_BU_CBC2 1;
BA_ "GenSigSNA" SG_ 1016 EC_BU_CBC2 "0h";
BA_ "FlexKomComment" SG_ 1016 EC_BU_ECUCfg1_Stat "Backup for ECU Configuration messages status 1";
BA_ "FlexKomIsMotorola" SG_ 1016 EC_BU_ECUCfg1_Stat 1;
BA_ "FlexKomSID" SG_ 1016 EC_BU_ECUCfg1_Stat 1064;
BA_ "FlexKomSigLaenge" SG_ 1016 EC_BU_ECUCfg1_Stat 2;
BA_ "FlexKomSigName" SG_ 1016 EC_BU_ECUCfg1_Stat "EC_BU_ECUCfg1_Stat";
BA_ "FlexKomSigStartPos" SG_ 1016 EC_BU_ECUCfg1_Stat 1;
BA_ "FlexKomSigStartValue" SG_ 1016 EC_BU_ECUCfg1_Stat "03h";
BA_ "GenSigSendType" SG_ 1016 EC_BU_ECUCfg1_Stat 1;
BA_ "GenSigSNA" SG_ 1016 EC_BU_ECUCfg1_Stat "3h";
BA_ "GenSigStartValue" SG_ 1016 EC_BU_ECUCfg1_Stat 3;
BA_ "FlexKomComment" SG_ 989 EC_BU_Cluster3A "Backup for Instrument cluster ecu configuration 3";
BA_ "FlexKomIsMotorola" SG_ 989 EC_BU_Cluster3A 1;
BA_ "FlexKomSID" SG_ 989 EC_BU_Cluster3A 1305;
BA_ "FlexKomSigLaenge" SG_ 989 EC_BU_Cluster3A 32;
BA_ "FlexKomSigName" SG_ 989 EC_BU_Cluster3A "EC_BU_Cluster3";
BA_ "FlexKomSigStartPos" SG_ 989 EC_BU_Cluster3A 7;
BA_ "FlexKomSigStartValue" SG_ 989 EC_BU_Cluster3A "00000000h";
BA_ "GenSigSendType" SG_ 989 EC_BU_Cluster3A 1;
BA_ "GenSigSNA" SG_ 989 EC_BU_Cluster3A "0h";
BA_ "FlexKomComment" SG_ 989 EC_BU_Cluster3B "Backup for Instrument cluster ecu configuration 3";
BA_ "FlexKomIsMotorola" SG_ 989 EC_BU_Cluster3B 1;
BA_ "FlexKomSID" SG_ 989 EC_BU_Cluster3B 1305;
BA_ "FlexKomSigLaenge" SG_ 989 EC_BU_Cluster3B 32;
BA_ "FlexKomSigName" SG_ 989 EC_BU_Cluster3B "EC_BU_Cluster3";
BA_ "FlexKomSigStartPos" SG_ 989 EC_BU_Cluster3B 7;
BA_ "FlexKomSigStartValue" SG_ 989 EC_BU_Cluster3B "00000000h";
BA_ "GenSigSendType" SG_ 989 EC_BU_Cluster3B 1;
BA_ "GenSigSNA" SG_ 989 EC_BU_Cluster3B "0h";
BA_ "FlexKomComment" SG_ 989 EC_BU_Cluster4 "Backup for Instrument cluster ecu configuration 4";
BA_ "FlexKomIsMotorola" SG_ 989 EC_BU_Cluster4 1;
BA_ "FlexKomSID" SG_ 989 EC_BU_Cluster4 1304;
BA_ "FlexKomSigLaenge" SG_ 989 EC_BU_Cluster4 32;
BA_ "FlexKomSigName" SG_ 989 EC_BU_Cluster4 "EC_BU_Cluster4";
BA_ "FlexKomSigStartPos" SG_ 989 EC_BU_Cluster4 39;
BA_ "FlexKomSigStartValue" SG_ 989 EC_BU_Cluster4 "00000000h";
BA_ "GenSigSendType" SG_ 989 EC_BU_Cluster4 1;
BA_ "GenSigSNA" SG_ 989 EC_BU_Cluster4 "0h";
BA_ "FlexKomComment" SG_ 989 EC_BU_ECUCfg10_Stat "Backup for ECU Configuration messages status 10";
BA_ "FlexKomIsMotorola" SG_ 989 EC_BU_ECUCfg10_Stat 1;
BA_ "FlexKomSID" SG_ 989 EC_BU_ECUCfg10_Stat 1302;
BA_ "FlexKomSigLaenge" SG_ 989 EC_BU_ECUCfg10_Stat 2;
BA_ "FlexKomSigName" SG_ 989 EC_BU_ECUCfg10_Stat "EC_BU_ECUCfg10_Stat";
BA_ "FlexKomSigStartPos" SG_ 989 EC_BU_ECUCfg10_Stat 1;
BA_ "FlexKomSigStartValue" SG_ 989 EC_BU_ECUCfg10_Stat "03h";
BA_ "GenSigSendType" SG_ 989 EC_BU_ECUCfg10_Stat 1;
BA_ "GenSigSNA" SG_ 989 EC_BU_ECUCfg10_Stat "3h";
BA_ "GenSigStartValue" SG_ 989 EC_BU_ECUCfg10_Stat 3;
BA_ "FlexKomComment" SG_ 988 EC_BU_CBC10A "Backup for CBC ecu configuration 10";
BA_ "FlexKomIsMotorola" SG_ 988 EC_BU_CBC10A 1;
BA_ "FlexKomSID" SG_ 988 EC_BU_CBC10A 1712;
BA_ "FlexKomSigLaenge" SG_ 988 EC_BU_CBC10A 32;
BA_ "FlexKomSigName" SG_ 988 EC_BU_CBC10A "EC_BU_CBC10";
BA_ "FlexKomSigStartPos" SG_ 988 EC_BU_CBC10A 7;
BA_ "FlexKomSigStartValue" SG_ 988 EC_BU_CBC10A "00000000h";
BA_ "GenSigSendType" SG_ 988 EC_BU_CBC10A 1;
BA_ "GenSigSNA" SG_ 988 EC_BU_CBC10A "0h";
BA_ "FlexKomComment" SG_ 988 EC_BU_CBC10B "Backup for CBC ecu configuration 10";
BA_ "FlexKomIsMotorola" SG_ 988 EC_BU_CBC10B 1;
BA_ "FlexKomSID" SG_ 988 EC_BU_CBC10B 1712;
BA_ "FlexKomSigLaenge" SG_ 988 EC_BU_CBC10B 32;
BA_ "FlexKomSigName" SG_ 988 EC_BU_CBC10B "EC_BU_CBC10";
BA_ "FlexKomSigStartPos" SG_ 988 EC_BU_CBC10B 7;
BA_ "FlexKomSigStartValue" SG_ 988 EC_BU_CBC10B "00000000h";
BA_ "GenSigSendType" SG_ 988 EC_BU_CBC10B 1;
BA_ "GenSigSNA" SG_ 988 EC_BU_CBC10B "0h";
BA_ "FlexKomComment" SG_ 988 EC_BU_CBC11 "Backup for CBC ecu configuration 11";
BA_ "FlexKomIsMotorola" SG_ 988 EC_BU_CBC11 1;
BA_ "FlexKomSID" SG_ 988 EC_BU_CBC11 1713;
BA_ "FlexKomSigLaenge" SG_ 988 EC_BU_CBC11 32;
BA_ "FlexKomSigName" SG_ 988 EC_BU_CBC11 "EC_BU_CBC11";
BA_ "FlexKomSigStartPos" SG_ 988 EC_BU_CBC11 39;
BA_ "FlexKomSigStartValue" SG_ 988 EC_BU_CBC11 "00000000h";
BA_ "GenSigSendType" SG_ 988 EC_BU_CBC11 1;
BA_ "GenSigSNA" SG_ 988 EC_BU_CBC11 "0h";
BA_ "FlexKomComment" SG_ 988 EC_BU_ECUCfg11_Stat "Backup for ECU Configuration messages status 11";
BA_ "FlexKomIsMotorola" SG_ 988 EC_BU_ECUCfg11_Stat 1;
BA_ "FlexKomSID" SG_ 988 EC_BU_ECUCfg11_Stat 1711;
BA_ "FlexKomSigLaenge" SG_ 988 EC_BU_ECUCfg11_Stat 2;
BA_ "FlexKomSigName" SG_ 988 EC_BU_ECUCfg11_Stat "EC_BU_ECUCfg11_Stat";
BA_ "FlexKomSigStartPos" SG_ 988 EC_BU_ECUCfg11_Stat 1;
BA_ "FlexKomSigStartValue" SG_ 988 EC_BU_ECUCfg11_Stat "03h";
BA_ "GenSigSendType" SG_ 988 EC_BU_ECUCfg11_Stat 1;
BA_ "GenSigSNA" SG_ 988 EC_BU_ECUCfg11_Stat "3h";
BA_ "GenSigStartValue" SG_ 988 EC_BU_ECUCfg11_Stat 3;
BA_ "FlexKomComment" SG_ 987 EC_BU_Cluster5A "Backup for Instrument cluster ecu configuration 5";
BA_ "FlexKomIsMotorola" SG_ 987 EC_BU_Cluster5A 1;
BA_ "FlexKomSID" SG_ 987 EC_BU_Cluster5A 1837;
BA_ "FlexKomSigLaenge" SG_ 987 EC_BU_Cluster5A 64;
BA_ "FlexKomSigName" SG_ 987 EC_BU_Cluster5A "EC_BU_Cluster5";
BA_ "FlexKomSigStartPos" SG_ 987 EC_BU_Cluster5A 7;
BA_ "FlexKomSigStartValue" SG_ 987 EC_BU_Cluster5A "0000000000000000h";
BA_ "GenSigSendType" SG_ 987 EC_BU_Cluster5A 1;
BA_ "GenSigSNA" SG_ 987 EC_BU_Cluster5A "0h";
BA_ "FlexKomComment" SG_ 987 EC_BU_Cluster5B "Backup for Instrument cluster ecu configuration 5";
BA_ "FlexKomIsMotorola" SG_ 987 EC_BU_Cluster5B 1;
BA_ "FlexKomSID" SG_ 987 EC_BU_Cluster5B 1837;
BA_ "FlexKomSigLaenge" SG_ 987 EC_BU_Cluster5B 64;
BA_ "FlexKomSigName" SG_ 987 EC_BU_Cluster5B "EC_BU_Cluster5";
BA_ "FlexKomSigStartPos" SG_ 987 EC_BU_Cluster5B 7;
BA_ "FlexKomSigStartValue" SG_ 987 EC_BU_Cluster5B "0000000000000000h";
BA_ "GenSigSendType" SG_ 987 EC_BU_Cluster5B 1;
BA_ "GenSigSNA" SG_ 987 EC_BU_Cluster5B "0h";
BA_ "FlexKomComment" SG_ 987 EC_BU_Cluster5C "Backup for Instrument cluster ecu configuration 5";
BA_ "FlexKomIsMotorola" SG_ 987 EC_BU_Cluster5C 1;
BA_ "FlexKomSID" SG_ 987 EC_BU_Cluster5C 1837;
BA_ "FlexKomSigLaenge" SG_ 987 EC_BU_Cluster5C 64;
BA_ "FlexKomSigName" SG_ 987 EC_BU_Cluster5C "EC_BU_Cluster5";
BA_ "FlexKomSigStartPos" SG_ 987 EC_BU_Cluster5C 7;
BA_ "FlexKomSigStartValue" SG_ 987 EC_BU_Cluster5C "0000000000000000h";
BA_ "GenSigSendType" SG_ 987 EC_BU_Cluster5C 1;
BA_ "GenSigSNA" SG_ 987 EC_BU_Cluster5C "0h";
BA_ "FlexKomComment" SG_ 987 EC_BU_ECUCfg12_Stat "Backup for ECU Configuration messages status 12";
BA_ "FlexKomIsMotorola" SG_ 987 EC_BU_ECUCfg12_Stat 1;
BA_ "FlexKomSID" SG_ 987 EC_BU_ECUCfg12_Stat 1836;
BA_ "FlexKomSigLaenge" SG_ 987 EC_BU_ECUCfg12_Stat 2;
BA_ "FlexKomSigName" SG_ 987 EC_BU_ECUCfg12_Stat "EC_BU_ECUCfg12_Stat";
BA_ "FlexKomSigStartPos" SG_ 987 EC_BU_ECUCfg12_Stat 1;
BA_ "FlexKomSigStartValue" SG_ 987 EC_BU_ECUCfg12_Stat "03h";
BA_ "GenSigSendType" SG_ 987 EC_BU_ECUCfg12_Stat 1;
BA_ "GenSigSNA" SG_ 987 EC_BU_ECUCfg12_Stat "3h";
BA_ "GenSigStartValue" SG_ 987 EC_BU_ECUCfg12_Stat 3;
BA_ "FlexKomComment" SG_ 986 EC_BU_CBC13A "CBC ecu configuration 13";
BA_ "FlexKomIsMotorola" SG_ 986 EC_BU_CBC13A 1;
BA_ "FlexKomSID" SG_ 986 EC_BU_CBC13A 1991;
BA_ "FlexKomSigLaenge" SG_ 986 EC_BU_CBC13A 64;
BA_ "FlexKomSigName" SG_ 986 EC_BU_CBC13A "EC_BU_CBC13";
BA_ "FlexKomSigStartPos" SG_ 986 EC_BU_CBC13A 7;
BA_ "FlexKomSigStartValue" SG_ 986 EC_BU_CBC13A "0000000000000000h";
BA_ "GenSigSendType" SG_ 986 EC_BU_CBC13A 1;
BA_ "GenSigSNA" SG_ 986 EC_BU_CBC13A "0h";
BA_ "FlexKomComment" SG_ 986 EC_BU_CBC13B "CBC ecu configuration 13";
BA_ "FlexKomIsMotorola" SG_ 986 EC_BU_CBC13B 1;
BA_ "FlexKomSID" SG_ 986 EC_BU_CBC13B 1991;
BA_ "FlexKomSigLaenge" SG_ 986 EC_BU_CBC13B 64;
BA_ "FlexKomSigName" SG_ 986 EC_BU_CBC13B "EC_BU_CBC13";
BA_ "FlexKomSigStartPos" SG_ 986 EC_BU_CBC13B 7;
BA_ "FlexKomSigStartValue" SG_ 986 EC_BU_CBC13B "0000000000000000h";
BA_ "GenSigSendType" SG_ 986 EC_BU_CBC13B 1;
BA_ "GenSigSNA" SG_ 986 EC_BU_CBC13B "0h";
BA_ "FlexKomComment" SG_ 986 EC_BU_ECUCfg13_Stat "Backup for ECU Configuration messages status 13";
BA_ "FlexKomIsMotorola" SG_ 986 EC_BU_ECUCfg13_Stat 1;
BA_ "FlexKomSID" SG_ 986 EC_BU_ECUCfg13_Stat 1871;
BA_ "FlexKomSigLaenge" SG_ 986 EC_BU_ECUCfg13_Stat 2;
BA_ "FlexKomSigName" SG_ 986 EC_BU_ECUCfg13_Stat "EC_BU_ECUCfg13_Stat";
BA_ "FlexKomSigStartPos" SG_ 986 EC_BU_ECUCfg13_Stat 1;
BA_ "FlexKomSigStartValue" SG_ 986 EC_BU_ECUCfg13_Stat "03h";
BA_ "GenSigSendType" SG_ 986 EC_BU_ECUCfg13_Stat 1;
BA_ "GenSigSNA" SG_ 986 EC_BU_ECUCfg13_Stat "3h";
BA_ "GenSigStartValue" SG_ 986 EC_BU_ECUCfg13_Stat 3;
BA_ "FlexKomComment" SG_ 985 EC_BU_CBC14A "CBC ecu configuration 14";
BA_ "FlexKomIsMotorola" SG_ 985 EC_BU_CBC14A 1;
BA_ "FlexKomSID" SG_ 985 EC_BU_CBC14A 1953;
BA_ "FlexKomSigLaenge" SG_ 985 EC_BU_CBC14A 64;
BA_ "FlexKomSigName" SG_ 985 EC_BU_CBC14A "EC_BU_CBC14";
BA_ "FlexKomSigStartPos" SG_ 985 EC_BU_CBC14A 7;
BA_ "FlexKomSigStartValue" SG_ 985 EC_BU_CBC14A "0000000000000000h";
BA_ "GenSigSendType" SG_ 985 EC_BU_CBC14A 1;
BA_ "GenSigSNA" SG_ 985 EC_BU_CBC14A "0h";
BA_ "FlexKomComment" SG_ 985 EC_BU_CBC14B "CBC ecu configuration 14";
BA_ "FlexKomIsMotorola" SG_ 985 EC_BU_CBC14B 1;
BA_ "FlexKomSID" SG_ 985 EC_BU_CBC14B 1953;
BA_ "FlexKomSigLaenge" SG_ 985 EC_BU_CBC14B 64;
BA_ "FlexKomSigName" SG_ 985 EC_BU_CBC14B "EC_BU_CBC14";
BA_ "FlexKomSigStartPos" SG_ 985 EC_BU_CBC14B 7;
BA_ "FlexKomSigStartValue" SG_ 985 EC_BU_CBC14B "0000000000000000h";
BA_ "GenSigSendType" SG_ 985 EC_BU_CBC14B 1;
BA_ "GenSigSNA" SG_ 985 EC_BU_CBC14B "0h";
BA_ "FlexKomComment" SG_ 985 EC_BU_ECUCfg14_Stat "Backup for ECU Configuration messages status 14";
BA_ "FlexKomIsMotorola" SG_ 985 EC_BU_ECUCfg14_Stat 1;
BA_ "FlexKomSID" SG_ 985 EC_BU_ECUCfg14_Stat 1952;
BA_ "FlexKomSigLaenge" SG_ 985 EC_BU_ECUCfg14_Stat 2;
BA_ "FlexKomSigName" SG_ 985 EC_BU_ECUCfg14_Stat "EC_BU_ECUCfg14_Stat";
BA_ "FlexKomSigStartPos" SG_ 985 EC_BU_ECUCfg14_Stat 1;
BA_ "FlexKomSigStartValue" SG_ 985 EC_BU_ECUCfg14_Stat "03h";
BA_ "GenSigSendType" SG_ 985 EC_BU_ECUCfg14_Stat 1;
BA_ "GenSigSNA" SG_ 985 EC_BU_ECUCfg14_Stat "3h";
BA_ "GenSigStartValue" SG_ 985 EC_BU_ECUCfg14_Stat 3;
BA_ "FlexKomComment" SG_ 707 EC_BU_CBC15A "CBC ecu configuration 15";
BA_ "FlexKomIsMotorola" SG_ 707 EC_BU_CBC15A 1;
BA_ "FlexKomSID" SG_ 707 EC_BU_CBC15A 2075;
BA_ "FlexKomSigLaenge" SG_ 707 EC_BU_CBC15A 48;
BA_ "FlexKomSigName" SG_ 707 EC_BU_CBC15A "EC_BU_CBC15";
BA_ "FlexKomSigStartPos" SG_ 707 EC_BU_CBC15A 7;
BA_ "FlexKomSigStartValue" SG_ 707 EC_BU_CBC15A "000000000000h";
BA_ "GenSigSendType" SG_ 707 EC_BU_CBC15A 1;
BA_ "GenSigSNA" SG_ 707 EC_BU_CBC15A "0h";
BA_ "FlexKomComment" SG_ 707 EC_BU_CBC15B "CBC ecu configuration 15";
BA_ "FlexKomIsMotorola" SG_ 707 EC_BU_CBC15B 1;
BA_ "FlexKomSID" SG_ 707 EC_BU_CBC15B 2075;
BA_ "FlexKomSigLaenge" SG_ 707 EC_BU_CBC15B 48;
BA_ "FlexKomSigName" SG_ 707 EC_BU_CBC15B "EC_BU_CBC15";
BA_ "FlexKomSigStartPos" SG_ 707 EC_BU_CBC15B 7;
BA_ "FlexKomSigStartValue" SG_ 707 EC_BU_CBC15B "000000000000h";
BA_ "GenSigSendType" SG_ 707 EC_BU_CBC15B 1;
BA_ "GenSigSNA" SG_ 707 EC_BU_CBC15B "0h";
BA_ "FlexKomComment" SG_ 707 EC_BU_ECUCfg15_Stat "Backup for ECU Configuration messages status 15";
BA_ "FlexKomIsMotorola" SG_ 707 EC_BU_ECUCfg15_Stat 1;
BA_ "FlexKomSID" SG_ 707 EC_BU_ECUCfg15_Stat 2074;
BA_ "FlexKomSigLaenge" SG_ 707 EC_BU_ECUCfg15_Stat 2;
BA_ "FlexKomSigName" SG_ 707 EC_BU_ECUCfg15_Stat "EC_BU_ECUCfg15_Stat";
BA_ "FlexKomSigStartPos" SG_ 707 EC_BU_ECUCfg15_Stat 1;
BA_ "FlexKomSigStartValue" SG_ 707 EC_BU_ECUCfg15_Stat "03h";
BA_ "GenSigSendType" SG_ 707 EC_BU_ECUCfg15_Stat 1;
BA_ "GenSigSNA" SG_ 707 EC_BU_ECUCfg15_Stat "3h";
BA_ "GenSigStartValue" SG_ 707 EC_BU_ECUCfg15_Stat 3;
BA_ "FlexKomComment" SG_ 707 EC_BU_Suspension "Backup for Suspension ecu configuration";
BA_ "FlexKomIsMotorola" SG_ 707 EC_BU_Suspension 1;
BA_ "FlexKomSID" SG_ 707 EC_BU_Suspension 914;
BA_ "FlexKomSigLaenge" SG_ 707 EC_BU_Suspension 16;
BA_ "FlexKomSigName" SG_ 707 EC_BU_Suspension "EC_BU_Suspension";
BA_ "FlexKomSigStartPos" SG_ 707 EC_BU_Suspension 55;
BA_ "FlexKomSigStartValue" SG_ 707 EC_BU_Suspension "0000h";
BA_ "GenSigSendType" SG_ 707 EC_BU_Suspension 1;
BA_ "GenSigSNA" SG_ 707 EC_BU_Suspension "0h";
BA_ "FlexKomComment" SG_ 714 EC_BU_AudTel3A "Backup for audio and telematics ecu configuration ";
BA_ "FlexKomIsMotorola" SG_ 714 EC_BU_AudTel3A 1;
BA_ "FlexKomSID" SG_ 714 EC_BU_AudTel3A 2287;
BA_ "FlexKomSigLaenge" SG_ 714 EC_BU_AudTel3A 64;
BA_ "FlexKomSigName" SG_ 714 EC_BU_AudTel3A "EC_BU_AudTel3";
BA_ "FlexKomSigStartPos" SG_ 714 EC_BU_AudTel3A 7;
BA_ "FlexKomSigStartValue" SG_ 714 EC_BU_AudTel3A "0000000000000000h";
BA_ "GenSigSendType" SG_ 714 EC_BU_AudTel3A 1;
BA_ "GenSigSNA" SG_ 714 EC_BU_AudTel3A "0h";
BA_ "FlexKomComment" SG_ 714 EC_BU_AudTel3B "Backup for audio and telematics ecu configuration ";
BA_ "FlexKomIsMotorola" SG_ 714 EC_BU_AudTel3B 1;
BA_ "FlexKomSID" SG_ 714 EC_BU_AudTel3B 2287;
BA_ "FlexKomSigLaenge" SG_ 714 EC_BU_AudTel3B 64;
BA_ "FlexKomSigName" SG_ 714 EC_BU_AudTel3B "EC_BU_AudTel3";
BA_ "FlexKomSigStartPos" SG_ 714 EC_BU_AudTel3B 7;
BA_ "FlexKomSigStartValue" SG_ 714 EC_BU_AudTel3B "0000000000000000h";
BA_ "GenSigSendType" SG_ 714 EC_BU_AudTel3B 1;
BA_ "GenSigSNA" SG_ 714 EC_BU_AudTel3B "0h";
BA_ "FlexKomComment" SG_ 714 EC_BU_ECUCfg16_Stat "Backup for ECU Configuration messages status 16";
BA_ "FlexKomIsMotorola" SG_ 714 EC_BU_ECUCfg16_Stat 1;
BA_ "FlexKomSID" SG_ 714 EC_BU_ECUCfg16_Stat 2289;
BA_ "FlexKomSigLaenge" SG_ 714 EC_BU_ECUCfg16_Stat 2;
BA_ "FlexKomSigName" SG_ 714 EC_BU_ECUCfg16_Stat "EC_BU_ECUCfg16_Stat";
BA_ "FlexKomSigStartPos" SG_ 714 EC_BU_ECUCfg16_Stat 1;
BA_ "FlexKomSigStartValue" SG_ 714 EC_BU_ECUCfg16_Stat "03h";
BA_ "GenSigSendType" SG_ 714 EC_BU_ECUCfg16_Stat 1;
BA_ "GenSigSNA" SG_ 714 EC_BU_ECUCfg16_Stat "3h";
BA_ "GenSigStartValue" SG_ 714 EC_BU_ECUCfg16_Stat 3;
BA_ "FlexKomComment" SG_ 715 EC_BU_ECUCfg17_Stat "ECU backup configuration 17 packet";
BA_ "FlexKomIsMotorola" SG_ 715 EC_BU_ECUCfg17_Stat 1;
BA_ "FlexKomSID" SG_ 715 EC_BU_ECUCfg17_Stat 2479;
BA_ "FlexKomSigLaenge" SG_ 715 EC_BU_ECUCfg17_Stat 64;
BA_ "FlexKomSigName" SG_ 715 EC_BU_ECUCfg17_Stat "EcuBuCfg17Pkt";
BA_ "FlexKomSigStartPos" SG_ 715 EC_BU_ECUCfg17_Stat 7;
BA_ "FlexKomSigStartValue" SG_ 715 EC_BU_ECUCfg17_Stat "0300000000000000h";
BA_ "GenSigSendType" SG_ 715 EC_BU_ECUCfg17_Stat 1;
BA_ "GenSigSNA" SG_ 715 EC_BU_ECUCfg17_Stat "3h";
BA_ "GenSigStartValue" SG_ 715 EC_BU_ECUCfg17_Stat 3;
BA_ "FlexKomComment" SG_ 715 EC_BU_PTS "ECU backup configuration 17 packet";
BA_ "FlexKomIsMotorola" SG_ 715 EC_BU_PTS 1;
BA_ "FlexKomSID" SG_ 715 EC_BU_PTS 2479;
BA_ "FlexKomSigLaenge" SG_ 715 EC_BU_PTS 64;
BA_ "FlexKomSigName" SG_ 715 EC_BU_PTS "EcuBuCfg17Pkt";
BA_ "FlexKomSigStartPos" SG_ 715 EC_BU_PTS 7;
BA_ "FlexKomSigStartValue" SG_ 715 EC_BU_PTS "0300000000000000h";
BA_ "GenSigSendType" SG_ 715 EC_BU_PTS 1;
BA_ "GenSigSNA" SG_ 715 EC_BU_PTS "0h";
BA_ "FlexKomComment" SG_ 1017 EC_BU_CBC3A "Backup for CBC ecu configuration 3";
BA_ "FlexKomIsMotorola" SG_ 1017 EC_BU_CBC3A 1;
BA_ "FlexKomSID" SG_ 1017 EC_BU_CBC3A 909;
BA_ "FlexKomSigLaenge" SG_ 1017 EC_BU_CBC3A 32;
BA_ "FlexKomSigName" SG_ 1017 EC_BU_CBC3A "EC_BU_CBC3";
BA_ "FlexKomSigStartPos" SG_ 1017 EC_BU_CBC3A 7;
BA_ "FlexKomSigStartValue" SG_ 1017 EC_BU_CBC3A "00000000h";
BA_ "GenSigSendType" SG_ 1017 EC_BU_CBC3A 1;
BA_ "GenSigSNA" SG_ 1017 EC_BU_CBC3A "0h";
BA_ "FlexKomComment" SG_ 1017 EC_BU_CBC3B "Backup for CBC ecu configuration 3";
BA_ "FlexKomIsMotorola" SG_ 1017 EC_BU_CBC3B 1;
BA_ "FlexKomSID" SG_ 1017 EC_BU_CBC3B 909;
BA_ "FlexKomSigLaenge" SG_ 1017 EC_BU_CBC3B 32;
BA_ "FlexKomSigName" SG_ 1017 EC_BU_CBC3B "EC_BU_CBC3";
BA_ "FlexKomSigStartPos" SG_ 1017 EC_BU_CBC3B 7;
BA_ "FlexKomSigStartValue" SG_ 1017 EC_BU_CBC3B "00000000h";
BA_ "GenSigSendType" SG_ 1017 EC_BU_CBC3B 1;
BA_ "GenSigSNA" SG_ 1017 EC_BU_CBC3B "0h";
BA_ "FlexKomComment" SG_ 1017 EC_BU_CBC4 "Backup for CBC ecu configuration 4";
BA_ "FlexKomIsMotorola" SG_ 1017 EC_BU_CBC4 1;
BA_ "FlexKomSID" SG_ 1017 EC_BU_CBC4 910;
BA_ "FlexKomSigLaenge" SG_ 1017 EC_BU_CBC4 32;
BA_ "FlexKomSigName" SG_ 1017 EC_BU_CBC4 "EC_BU_CBC4";
BA_ "FlexKomSigStartPos" SG_ 1017 EC_BU_CBC4 39;
BA_ "FlexKomSigStartValue" SG_ 1017 EC_BU_CBC4 "00000000h";
BA_ "GenSigSendType" SG_ 1017 EC_BU_CBC4 1;
BA_ "GenSigSNA" SG_ 1017 EC_BU_CBC4 "0h";
BA_ "FlexKomComment" SG_ 1017 EC_BU_ECUCfg2_Stat "Backup for ECU Configuration messages status 2";
BA_ "FlexKomIsMotorola" SG_ 1017 EC_BU_ECUCfg2_Stat 1;
BA_ "FlexKomSID" SG_ 1017 EC_BU_ECUCfg2_Stat 1065;
BA_ "FlexKomSigLaenge" SG_ 1017 EC_BU_ECUCfg2_Stat 2;
BA_ "FlexKomSigName" SG_ 1017 EC_BU_ECUCfg2_Stat "EC_BU_ECUCfg2_Stat";
BA_ "FlexKomSigStartPos" SG_ 1017 EC_BU_ECUCfg2_Stat 1;
BA_ "FlexKomSigStartValue" SG_ 1017 EC_BU_ECUCfg2_Stat "03h";
BA_ "GenSigSendType" SG_ 1017 EC_BU_ECUCfg2_Stat 1;
BA_ "GenSigSNA" SG_ 1017 EC_BU_ECUCfg2_Stat "3h";
BA_ "GenSigStartValue" SG_ 1017 EC_BU_ECUCfg2_Stat 3;
BA_ "FlexKomComment" SG_ 1018 EC_BU_AudTel1A "Backup for Audio and telematics ecu configuration ";
BA_ "FlexKomIsMotorola" SG_ 1018 EC_BU_AudTel1A 1;
BA_ "FlexKomSID" SG_ 1018 EC_BU_AudTel1A 904;
BA_ "FlexKomSigLaenge" SG_ 1018 EC_BU_AudTel1A 32;
BA_ "FlexKomSigName" SG_ 1018 EC_BU_AudTel1A "EC_BU_AudTel1";
BA_ "FlexKomSigStartPos" SG_ 1018 EC_BU_AudTel1A 7;
BA_ "FlexKomSigStartValue" SG_ 1018 EC_BU_AudTel1A "00000000h";
BA_ "GenSigSendType" SG_ 1018 EC_BU_AudTel1A 1;
BA_ "GenSigSNA" SG_ 1018 EC_BU_AudTel1A "0h";
BA_ "FlexKomComment" SG_ 1018 EC_BU_AudTel1B "Backup for Audio and telematics ecu configuration ";
BA_ "FlexKomIsMotorola" SG_ 1018 EC_BU_AudTel1B 1;
BA_ "FlexKomSID" SG_ 1018 EC_BU_AudTel1B 904;
BA_ "FlexKomSigLaenge" SG_ 1018 EC_BU_AudTel1B 32;
BA_ "FlexKomSigName" SG_ 1018 EC_BU_AudTel1B "EC_BU_AudTel1";
BA_ "FlexKomSigStartPos" SG_ 1018 EC_BU_AudTel1B 7;
BA_ "FlexKomSigStartValue" SG_ 1018 EC_BU_AudTel1B "00000000h";
BA_ "GenSigSendType" SG_ 1018 EC_BU_AudTel1B 1;
BA_ "GenSigSNA" SG_ 1018 EC_BU_AudTel1B "0h";
BA_ "FlexKomComment" SG_ 1018 EC_BU_AudTel2 "Backup for Audio and telematics ecu configuration ";
BA_ "FlexKomIsMotorola" SG_ 1018 EC_BU_AudTel2 1;
BA_ "FlexKomSID" SG_ 1018 EC_BU_AudTel2 905;
BA_ "FlexKomSigLaenge" SG_ 1018 EC_BU_AudTel2 32;
BA_ "FlexKomSigName" SG_ 1018 EC_BU_AudTel2 "EC_BU_AudTel2";
BA_ "FlexKomSigStartPos" SG_ 1018 EC_BU_AudTel2 39;
BA_ "FlexKomSigStartValue" SG_ 1018 EC_BU_AudTel2 "00000000h";
BA_ "GenSigSendType" SG_ 1018 EC_BU_AudTel2 1;
BA_ "GenSigSNA" SG_ 1018 EC_BU_AudTel2 "0h";
BA_ "FlexKomComment" SG_ 1018 EC_BU_ECUCfg3_Stat "Backup for ECU Configuration messages status 3";
BA_ "FlexKomIsMotorola" SG_ 1018 EC_BU_ECUCfg3_Stat 1;
BA_ "FlexKomSID" SG_ 1018 EC_BU_ECUCfg3_Stat 1066;
BA_ "FlexKomSigLaenge" SG_ 1018 EC_BU_ECUCfg3_Stat 2;
BA_ "FlexKomSigName" SG_ 1018 EC_BU_ECUCfg3_Stat "EC_BU_ECUCfg3_Stat";
BA_ "FlexKomSigStartPos" SG_ 1018 EC_BU_ECUCfg3_Stat 1;
BA_ "FlexKomSigStartValue" SG_ 1018 EC_BU_ECUCfg3_Stat "03h";
BA_ "GenSigSendType" SG_ 1018 EC_BU_ECUCfg3_Stat 1;
BA_ "GenSigSNA" SG_ 1018 EC_BU_ECUCfg3_Stat "3h";
BA_ "GenSigStartValue" SG_ 1018 EC_BU_ECUCfg3_Stat 3;
BA_ "FlexKomComment" SG_ 1019 EC_BU_Cluster1A "Backup for Instrument cluster ecu configuration 1";
BA_ "FlexKomIsMotorola" SG_ 1019 EC_BU_Cluster1A 1;
BA_ "FlexKomSID" SG_ 1019 EC_BU_Cluster1A 911;
BA_ "FlexKomSigLaenge" SG_ 1019 EC_BU_Cluster1A 32;
BA_ "FlexKomSigName" SG_ 1019 EC_BU_Cluster1A "EC_BU_Cluster1";
BA_ "FlexKomSigStartPos" SG_ 1019 EC_BU_Cluster1A 7;
BA_ "FlexKomSigStartValue" SG_ 1019 EC_BU_Cluster1A "00000000h";
BA_ "GenSigSendType" SG_ 1019 EC_BU_Cluster1A 1;
BA_ "GenSigSNA" SG_ 1019 EC_BU_Cluster1A "0h";
BA_ "FlexKomComment" SG_ 1019 EC_BU_Cluster1B "Backup for Instrument cluster ecu configuration 1";
BA_ "FlexKomIsMotorola" SG_ 1019 EC_BU_Cluster1B 1;
BA_ "FlexKomSID" SG_ 1019 EC_BU_Cluster1B 911;
BA_ "FlexKomSigLaenge" SG_ 1019 EC_BU_Cluster1B 32;
BA_ "FlexKomSigName" SG_ 1019 EC_BU_Cluster1B "EC_BU_Cluster1";
BA_ "FlexKomSigStartPos" SG_ 1019 EC_BU_Cluster1B 7;
BA_ "FlexKomSigStartValue" SG_ 1019 EC_BU_Cluster1B "00000000h";
BA_ "GenSigSendType" SG_ 1019 EC_BU_Cluster1B 1;
BA_ "GenSigSNA" SG_ 1019 EC_BU_Cluster1B "0h";
BA_ "FlexKomComment" SG_ 1019 EC_BU_Cluster2 "Backup for Instrument cluster ecu configuration 2";
BA_ "FlexKomIsMotorola" SG_ 1019 EC_BU_Cluster2 1;
BA_ "FlexKomSID" SG_ 1019 EC_BU_Cluster2 912;
BA_ "FlexKomSigLaenge" SG_ 1019 EC_BU_Cluster2 32;
BA_ "FlexKomSigName" SG_ 1019 EC_BU_Cluster2 "EC_BU_Cluster2";
BA_ "FlexKomSigStartPos" SG_ 1019 EC_BU_Cluster2 39;
BA_ "FlexKomSigStartValue" SG_ 1019 EC_BU_Cluster2 "00000000h";
BA_ "GenSigSendType" SG_ 1019 EC_BU_Cluster2 1;
BA_ "GenSigSNA" SG_ 1019 EC_BU_Cluster2 "0h";
BA_ "FlexKomComment" SG_ 1019 EC_BU_ECUCfg4_Stat "Backup for ECU Configuration messages status 4";
BA_ "FlexKomIsMotorola" SG_ 1019 EC_BU_ECUCfg4_Stat 1;
BA_ "FlexKomSID" SG_ 1019 EC_BU_ECUCfg4_Stat 1067;
BA_ "FlexKomSigLaenge" SG_ 1019 EC_BU_ECUCfg4_Stat 2;
BA_ "FlexKomSigName" SG_ 1019 EC_BU_ECUCfg4_Stat "EC_BU_ECUCfg4_Stat";
BA_ "FlexKomSigStartPos" SG_ 1019 EC_BU_ECUCfg4_Stat 1;
BA_ "FlexKomSigStartValue" SG_ 1019 EC_BU_ECUCfg4_Stat "03h";
BA_ "GenSigSendType" SG_ 1019 EC_BU_ECUCfg4_Stat 1;
BA_ "GenSigSNA" SG_ 1019 EC_BU_ECUCfg4_Stat "3h";
BA_ "GenSigStartValue" SG_ 1019 EC_BU_ECUCfg4_Stat 3;
BA_ "FlexKomComment" SG_ 1020 EC_BU_Doors "Backup for Doors ecu configuration";
BA_ "FlexKomIsMotorola" SG_ 1020 EC_BU_Doors 1;
BA_ "FlexKomSID" SG_ 1020 EC_BU_Doors 913;
BA_ "FlexKomSigLaenge" SG_ 1020 EC_BU_Doors 24;
BA_ "FlexKomSigName" SG_ 1020 EC_BU_Doors "EC_BU_Doors";
BA_ "FlexKomSigStartPos" SG_ 1020 EC_BU_Doors 31;
BA_ "FlexKomSigStartValue" SG_ 1020 EC_BU_Doors "000000h";
BA_ "GenSigSendType" SG_ 1020 EC_BU_Doors 1;
BA_ "GenSigSNA" SG_ 1020 EC_BU_Doors "0h";
BA_ "FlexKomComment" SG_ 1020 EC_BU_ECUCfg5_Stat "Backup for ECU Configuration messages status 5";
BA_ "FlexKomIsMotorola" SG_ 1020 EC_BU_ECUCfg5_Stat 1;
BA_ "FlexKomSID" SG_ 1020 EC_BU_ECUCfg5_Stat 1068;
BA_ "FlexKomSigLaenge" SG_ 1020 EC_BU_ECUCfg5_Stat 2;
BA_ "FlexKomSigName" SG_ 1020 EC_BU_ECUCfg5_Stat "EC_BU_ECUCfg5_Stat";
BA_ "FlexKomSigStartPos" SG_ 1020 EC_BU_ECUCfg5_Stat 1;
BA_ "FlexKomSigStartValue" SG_ 1020 EC_BU_ECUCfg5_Stat "03h";
BA_ "GenSigSendType" SG_ 1020 EC_BU_ECUCfg5_Stat 1;
BA_ "GenSigSNA" SG_ 1020 EC_BU_ECUCfg5_Stat "3h";
BA_ "GenSigStartValue" SG_ 1020 EC_BU_ECUCfg5_Stat 3;
BA_ "FlexKomComment" SG_ 1020 EC_BU_Memory "Backup for Memory ecu configuration";
BA_ "FlexKomIsMotorola" SG_ 1020 EC_BU_Memory 1;
BA_ "FlexKomSID" SG_ 1020 EC_BU_Memory 916;
BA_ "FlexKomSigLaenge" SG_ 1020 EC_BU_Memory 16;
BA_ "FlexKomSigName" SG_ 1020 EC_BU_Memory "EC_BU_Memory";
BA_ "FlexKomSigStartPos" SG_ 1020 EC_BU_Memory 55;
BA_ "FlexKomSigStartValue" SG_ 1020 EC_BU_Memory "0000h";
BA_ "GenSigSendType" SG_ 1020 EC_BU_Memory 1;
BA_ "GenSigSNA" SG_ 1020 EC_BU_Memory "0h";
BA_ "FlexKomComment" SG_ 1020 EC_BU_WirelessA "Backup for Wireless ecu configuration";
BA_ "FlexKomIsMotorola" SG_ 1020 EC_BU_WirelessA 1;
BA_ "FlexKomSID" SG_ 1020 EC_BU_WirelessA 915;
BA_ "FlexKomSigLaenge" SG_ 1020 EC_BU_WirelessA 24;
BA_ "FlexKomSigName" SG_ 1020 EC_BU_WirelessA "EC_BU_Wireless";
BA_ "FlexKomSigStartPos" SG_ 1020 EC_BU_WirelessA 7;
BA_ "FlexKomSigStartValue" SG_ 1020 EC_BU_WirelessA "000000h";
BA_ "GenSigSendType" SG_ 1020 EC_BU_WirelessA 1;
BA_ "GenSigSNA" SG_ 1020 EC_BU_WirelessA "0h";
BA_ "FlexKomComment" SG_ 1020 EC_BU_WirelessB "Backup for Wireless ecu configuration";
BA_ "FlexKomIsMotorola" SG_ 1020 EC_BU_WirelessB 1;
BA_ "FlexKomSID" SG_ 1020 EC_BU_WirelessB 915;
BA_ "FlexKomSigLaenge" SG_ 1020 EC_BU_WirelessB 24;
BA_ "FlexKomSigName" SG_ 1020 EC_BU_WirelessB "EC_BU_Wireless";
BA_ "FlexKomSigStartPos" SG_ 1020 EC_BU_WirelessB 7;
BA_ "FlexKomSigStartValue" SG_ 1020 EC_BU_WirelessB "000000h";
BA_ "GenSigSendType" SG_ 1020 EC_BU_WirelessB 1;
BA_ "GenSigSNA" SG_ 1020 EC_BU_WirelessB "0h";
BA_ "FlexKomComment" SG_ 1021 EC_BU_BrakesA "Backup for Brake system ecu configuration";
BA_ "FlexKomIsMotorola" SG_ 1021 EC_BU_BrakesA 1;
BA_ "FlexKomSID" SG_ 1021 EC_BU_BrakesA 906;
BA_ "FlexKomSigLaenge" SG_ 1021 EC_BU_BrakesA 16;
BA_ "FlexKomSigName" SG_ 1021 EC_BU_BrakesA "EC_BU_Brakes";
BA_ "FlexKomSigStartPos" SG_ 1021 EC_BU_BrakesA 7;
BA_ "FlexKomSigStartValue" SG_ 1021 EC_BU_BrakesA "0000h";
BA_ "GenSigSendType" SG_ 1021 EC_BU_BrakesA 1;
BA_ "GenSigSNA" SG_ 1021 EC_BU_BrakesA "0h";
BA_ "FlexKomComment" SG_ 1021 EC_BU_BrakesB "Backup for Brake system ecu configuration";
BA_ "FlexKomIsMotorola" SG_ 1021 EC_BU_BrakesB 1;
BA_ "FlexKomSID" SG_ 1021 EC_BU_BrakesB 906;
BA_ "FlexKomSigLaenge" SG_ 1021 EC_BU_BrakesB 16;
BA_ "FlexKomSigName" SG_ 1021 EC_BU_BrakesB "EC_BU_Brakes";
BA_ "FlexKomSigStartPos" SG_ 1021 EC_BU_BrakesB 7;
BA_ "FlexKomSigStartValue" SG_ 1021 EC_BU_BrakesB "0000h";
BA_ "GenSigSendType" SG_ 1021 EC_BU_BrakesB 1;
BA_ "GenSigSNA" SG_ 1021 EC_BU_BrakesB "0h";
BA_ "FlexKomComment" SG_ 1021 EC_BU_ECUCfg6_Stat "Backup for ECU Configuration messages status 6";
BA_ "FlexKomIsMotorola" SG_ 1021 EC_BU_ECUCfg6_Stat 1;
BA_ "FlexKomSID" SG_ 1021 EC_BU_ECUCfg6_Stat 1069;
BA_ "FlexKomSigLaenge" SG_ 1021 EC_BU_ECUCfg6_Stat 2;
BA_ "FlexKomSigName" SG_ 1021 EC_BU_ECUCfg6_Stat "EC_BU_ECUCfg6_Stat";
BA_ "FlexKomSigStartPos" SG_ 1021 EC_BU_ECUCfg6_Stat 1;
BA_ "FlexKomSigStartValue" SG_ 1021 EC_BU_ECUCfg6_Stat "03h";
BA_ "GenSigSendType" SG_ 1021 EC_BU_ECUCfg6_Stat 1;
BA_ "GenSigSNA" SG_ 1021 EC_BU_ECUCfg6_Stat "3h";
BA_ "GenSigStartValue" SG_ 1021 EC_BU_ECUCfg6_Stat 3;
BA_ "FlexKomComment" SG_ 1021 EC_BU_Powertrain "Backup for Powertrain ecu configuration";
BA_ "FlexKomIsMotorola" SG_ 1021 EC_BU_Powertrain 1;
BA_ "FlexKomSID" SG_ 1021 EC_BU_Powertrain 917;
BA_ "FlexKomSigLaenge" SG_ 1021 EC_BU_Powertrain 16;
BA_ "FlexKomSigName" SG_ 1021 EC_BU_Powertrain "EC_BU_Powertrain";
BA_ "FlexKomSigStartPos" SG_ 1021 EC_BU_Powertrain 39;
BA_ "FlexKomSigStartValue" SG_ 1021 EC_BU_Powertrain "0000h";
BA_ "GenSigSendType" SG_ 1021 EC_BU_Powertrain 1;
BA_ "GenSigSNA" SG_ 1021 EC_BU_Powertrain "0h";
BA_ "FlexKomComment" SG_ 1021 EC_BU_Safety "Backup for Safety ecu configuration";
BA_ "FlexKomIsMotorola" SG_ 1021 EC_BU_Safety 1;
BA_ "FlexKomSID" SG_ 1021 EC_BU_Safety 918;
BA_ "FlexKomSigLaenge" SG_ 1021 EC_BU_Safety 16;
BA_ "FlexKomSigName" SG_ 1021 EC_BU_Safety "EC_BU_Safety";
BA_ "FlexKomSigStartPos" SG_ 1021 EC_BU_Safety 55;
BA_ "FlexKomSigStartValue" SG_ 1021 EC_BU_Safety "0000h";
BA_ "GenSigSendType" SG_ 1021 EC_BU_Safety 1;
BA_ "GenSigSNA" SG_ 1021 EC_BU_Safety "0h";
BA_ "FlexKomComment" SG_ 1021 EC_BU_Steering "Backup for steering ecu configuration";
BA_ "FlexKomIsMotorola" SG_ 1021 EC_BU_Steering 1;
BA_ "FlexKomSID" SG_ 1021 EC_BU_Steering 1981;
BA_ "FlexKomSigLaenge" SG_ 1021 EC_BU_Steering 16;
BA_ "FlexKomSigName" SG_ 1021 EC_BU_Steering "EC_BU_Steering";
BA_ "FlexKomSigStartPos" SG_ 1021 EC_BU_Steering 23;
BA_ "FlexKomSigStartValue" SG_ 1021 EC_BU_Steering "0000h";
BA_ "GenSigSendType" SG_ 1021 EC_BU_Steering 1;
BA_ "GenSigSNA" SG_ 1021 EC_BU_Steering "0h";
BA_ "FlexKomComment" SG_ 1022 EC_BU_CBC5A "Backup for CBC ecu configuration 5";
BA_ "FlexKomIsMotorola" SG_ 1022 EC_BU_CBC5A 1;
BA_ "FlexKomSID" SG_ 1022 EC_BU_CBC5A 1099;
BA_ "FlexKomSigLaenge" SG_ 1022 EC_BU_CBC5A 32;
BA_ "FlexKomSigName" SG_ 1022 EC_BU_CBC5A "EC_BU_CBC5";
BA_ "FlexKomSigStartPos" SG_ 1022 EC_BU_CBC5A 7;
BA_ "FlexKomSigStartValue" SG_ 1022 EC_BU_CBC5A "00000000h";
BA_ "GenSigSendType" SG_ 1022 EC_BU_CBC5A 1;
BA_ "GenSigSNA" SG_ 1022 EC_BU_CBC5A "0h";
BA_ "FlexKomComment" SG_ 1022 EC_BU_CBC5B "Backup for CBC ecu configuration 5";
BA_ "FlexKomIsMotorola" SG_ 1022 EC_BU_CBC5B 1;
BA_ "FlexKomSID" SG_ 1022 EC_BU_CBC5B 1099;
BA_ "FlexKomSigLaenge" SG_ 1022 EC_BU_CBC5B 32;
BA_ "FlexKomSigName" SG_ 1022 EC_BU_CBC5B "EC_BU_CBC5";
BA_ "FlexKomSigStartPos" SG_ 1022 EC_BU_CBC5B 7;
BA_ "FlexKomSigStartValue" SG_ 1022 EC_BU_CBC5B "00000000h";
BA_ "GenSigSendType" SG_ 1022 EC_BU_CBC5B 1;
BA_ "GenSigSNA" SG_ 1022 EC_BU_CBC5B "0h";
BA_ "FlexKomComment" SG_ 1022 EC_BU_CBC6 "Backup for CBC ecu configuration 6";
BA_ "FlexKomIsMotorola" SG_ 1022 EC_BU_CBC6 1;
BA_ "FlexKomSID" SG_ 1022 EC_BU_CBC6 1096;
BA_ "FlexKomSigLaenge" SG_ 1022 EC_BU_CBC6 32;
BA_ "FlexKomSigName" SG_ 1022 EC_BU_CBC6 "EC_BU_CBC6";
BA_ "FlexKomSigStartPos" SG_ 1022 EC_BU_CBC6 39;
BA_ "FlexKomSigStartValue" SG_ 1022 EC_BU_CBC6 "00000000h";
BA_ "GenSigSendType" SG_ 1022 EC_BU_CBC6 1;
BA_ "GenSigSNA" SG_ 1022 EC_BU_CBC6 "0h";
BA_ "FlexKomComment" SG_ 1022 EC_BU_ECUCfg7_Stat "Backup for ECU Configuration messages status 7";
BA_ "FlexKomIsMotorola" SG_ 1022 EC_BU_ECUCfg7_Stat 1;
BA_ "FlexKomSID" SG_ 1022 EC_BU_ECUCfg7_Stat 1097;
BA_ "FlexKomSigLaenge" SG_ 1022 EC_BU_ECUCfg7_Stat 2;
BA_ "FlexKomSigName" SG_ 1022 EC_BU_ECUCfg7_Stat "EC_BU_ECUCfg7_Stat";
BA_ "FlexKomSigStartPos" SG_ 1022 EC_BU_ECUCfg7_Stat 1;
BA_ "FlexKomSigStartValue" SG_ 1022 EC_BU_ECUCfg7_Stat "03h";
BA_ "GenSigSendType" SG_ 1022 EC_BU_ECUCfg7_Stat 1;
BA_ "GenSigSNA" SG_ 1022 EC_BU_ECUCfg7_Stat "3h";
BA_ "GenSigStartValue" SG_ 1022 EC_BU_ECUCfg7_Stat 3;
BA_ "FlexKomComment" SG_ 1023 EC_BU_CBC7A "Backup for CBC ecu configuration 7";
BA_ "FlexKomIsMotorola" SG_ 1023 EC_BU_CBC7A 1;
BA_ "FlexKomSID" SG_ 1023 EC_BU_CBC7A 1100;
BA_ "FlexKomSigLaenge" SG_ 1023 EC_BU_CBC7A 32;
BA_ "FlexKomSigName" SG_ 1023 EC_BU_CBC7A "EC_BU_CBC7";
BA_ "FlexKomSigStartPos" SG_ 1023 EC_BU_CBC7A 7;
BA_ "FlexKomSigStartValue" SG_ 1023 EC_BU_CBC7A "00000000h";
BA_ "GenSigSendType" SG_ 1023 EC_BU_CBC7A 1;
BA_ "GenSigSNA" SG_ 1023 EC_BU_CBC7A "0h";
BA_ "FlexKomComment" SG_ 1023 EC_BU_CBC7B "Backup for CBC ecu configuration 7";
BA_ "FlexKomIsMotorola" SG_ 1023 EC_BU_CBC7B 1;
BA_ "FlexKomSID" SG_ 1023 EC_BU_CBC7B 1100;
BA_ "FlexKomSigLaenge" SG_ 1023 EC_BU_CBC7B 32;
BA_ "FlexKomSigName" SG_ 1023 EC_BU_CBC7B "EC_BU_CBC7";
BA_ "FlexKomSigStartPos" SG_ 1023 EC_BU_CBC7B 7;
BA_ "FlexKomSigStartValue" SG_ 1023 EC_BU_CBC7B "00000000h";
BA_ "GenSigSendType" SG_ 1023 EC_BU_CBC7B 1;
BA_ "GenSigSNA" SG_ 1023 EC_BU_CBC7B "0h";
BA_ "FlexKomComment" SG_ 1023 EC_BU_CBC8 "Backup for CBC ecu configuration 8";
BA_ "FlexKomIsMotorola" SG_ 1023 EC_BU_CBC8 1;
BA_ "FlexKomSID" SG_ 1023 EC_BU_CBC8 1095;
BA_ "FlexKomSigLaenge" SG_ 1023 EC_BU_CBC8 32;
BA_ "FlexKomSigName" SG_ 1023 EC_BU_CBC8 "EC_BU_CBC8";
BA_ "FlexKomSigStartPos" SG_ 1023 EC_BU_CBC8 39;
BA_ "FlexKomSigStartValue" SG_ 1023 EC_BU_CBC8 "00000000h";
BA_ "GenSigSendType" SG_ 1023 EC_BU_CBC8 1;
BA_ "GenSigSNA" SG_ 1023 EC_BU_CBC8 "0h";
BA_ "FlexKomComment" SG_ 1023 EC_BU_ECUCfg8_Stat "Backup for ECU Configuration messages status 8";
BA_ "FlexKomIsMotorola" SG_ 1023 EC_BU_ECUCfg8_Stat 1;
BA_ "FlexKomSID" SG_ 1023 EC_BU_ECUCfg8_Stat 1098;
BA_ "FlexKomSigLaenge" SG_ 1023 EC_BU_ECUCfg8_Stat 2;
BA_ "FlexKomSigName" SG_ 1023 EC_BU_ECUCfg8_Stat "EC_BU_ECUCfg8_Stat";
BA_ "FlexKomSigStartPos" SG_ 1023 EC_BU_ECUCfg8_Stat 1;
BA_ "FlexKomSigStartValue" SG_ 1023 EC_BU_ECUCfg8_Stat "03h";
BA_ "GenSigSendType" SG_ 1023 EC_BU_ECUCfg8_Stat 1;
BA_ "GenSigSNA" SG_ 1023 EC_BU_ECUCfg8_Stat "3h";
BA_ "GenSigStartValue" SG_ 1023 EC_BU_ECUCfg8_Stat 3;
BA_ "FlexKomComment" SG_ 991 EC_BU_CBC9A1 "Backup for CBC configuration 9A";
BA_ "FlexKomIsMotorola" SG_ 991 EC_BU_CBC9A1 1;
BA_ "FlexKomSID" SG_ 991 EC_BU_CBC9A1 1419;
BA_ "FlexKomSigLaenge" SG_ 991 EC_BU_CBC9A1 32;
BA_ "FlexKomSigName" SG_ 991 EC_BU_CBC9A1 "EC_BU_CBC9A";
BA_ "FlexKomSigStartPos" SG_ 991 EC_BU_CBC9A1 7;
BA_ "FlexKomSigStartValue" SG_ 991 EC_BU_CBC9A1 "00000000h";
BA_ "GenSigSendType" SG_ 991 EC_BU_CBC9A1 1;
BA_ "GenSigSNA" SG_ 991 EC_BU_CBC9A1 "0h";
BA_ "FlexKomComment" SG_ 991 EC_BU_CBC9A2 "Backup for CBC configuration 9A";
BA_ "FlexKomIsMotorola" SG_ 991 EC_BU_CBC9A2 1;
BA_ "FlexKomSID" SG_ 991 EC_BU_CBC9A2 1419;
BA_ "FlexKomSigLaenge" SG_ 991 EC_BU_CBC9A2 32;
BA_ "FlexKomSigName" SG_ 991 EC_BU_CBC9A2 "EC_BU_CBC9A";
BA_ "FlexKomSigStartPos" SG_ 991 EC_BU_CBC9A2 7;
BA_ "FlexKomSigStartValue" SG_ 991 EC_BU_CBC9A2 "00000000h";
BA_ "GenSigSendType" SG_ 991 EC_BU_CBC9A2 1;
BA_ "GenSigSNA" SG_ 991 EC_BU_CBC9A2 "0h";
BA_ "FlexKomComment" SG_ 991 EC_BU_CBC9B "Backup for CBC configuration 9B";
BA_ "FlexKomIsMotorola" SG_ 991 EC_BU_CBC9B 1;
BA_ "FlexKomSID" SG_ 991 EC_BU_CBC9B 1420;
BA_ "FlexKomSigLaenge" SG_ 991 EC_BU_CBC9B 16;
BA_ "FlexKomSigName" SG_ 991 EC_BU_CBC9B "EC_BU_CBC9B";
BA_ "FlexKomSigStartPos" SG_ 991 EC_BU_CBC9B 39;
BA_ "FlexKomSigStartValue" SG_ 991 EC_BU_CBC9B "0000h";
BA_ "GenSigSendType" SG_ 991 EC_BU_CBC9B 1;
BA_ "GenSigSNA" SG_ 991 EC_BU_CBC9B "0h";
BA_ "FlexKomComment" SG_ 991 EC_BU_ECUCfg9_Stat "Backup for ECU Configuration messages status 9";
BA_ "FlexKomIsMotorola" SG_ 991 EC_BU_ECUCfg9_Stat 1;
BA_ "FlexKomSID" SG_ 991 EC_BU_ECUCfg9_Stat 1216;
BA_ "FlexKomSigLaenge" SG_ 991 EC_BU_ECUCfg9_Stat 2;
BA_ "FlexKomSigName" SG_ 991 EC_BU_ECUCfg9_Stat "EC_BU_ECUCfg9_Stat";
BA_ "FlexKomSigStartPos" SG_ 991 EC_BU_ECUCfg9_Stat 1;
BA_ "FlexKomSigStartValue" SG_ 991 EC_BU_ECUCfg9_Stat "03h";
BA_ "GenSigSendType" SG_ 991 EC_BU_ECUCfg9_Stat 1;
BA_ "GenSigSNA" SG_ 991 EC_BU_ECUCfg9_Stat "3h";
BA_ "GenSigStartValue" SG_ 991 EC_BU_ECUCfg9_Stat 3;
BA_ "FlexKomComment" SG_ 991 EC_BU_ITM "Backup for ITM ecu configuration";
BA_ "FlexKomIsMotorola" SG_ 991 EC_BU_ITM 1;
BA_ "FlexKomSID" SG_ 991 EC_BU_ITM 1220;
BA_ "FlexKomSigLaenge" SG_ 991 EC_BU_ITM 16;
BA_ "FlexKomSigName" SG_ 991 EC_BU_ITM "EC_BU_ITM";
BA_ "FlexKomSigStartPos" SG_ 991 EC_BU_ITM 55;
BA_ "FlexKomSigStartValue" SG_ 991 EC_BU_ITM "0000h";
BA_ "GenSigSendType" SG_ 991 EC_BU_ITM 1;
BA_ "GenSigSNA" SG_ 991 EC_BU_ITM "0h";
BA_ "FlexKomComment" SG_ 1008 EC_CBC1A "CBC ecu configuration 1";
BA_ "FlexKomIsMotorola" SG_ 1008 EC_CBC1A 1;
BA_ "FlexKomSID" SG_ 1008 EC_CBC1A 899;
BA_ "FlexKomSigLaenge" SG_ 1008 EC_CBC1A 32;
BA_ "FlexKomSigName" SG_ 1008 EC_CBC1A "EC_CBC1";
BA_ "FlexKomSigStartPos" SG_ 1008 EC_CBC1A 7;
BA_ "FlexKomSigStartValue" SG_ 1008 EC_CBC1A "00000000h";
BA_ "GenSigCycleTime" SG_ 1008 EC_CBC1A 2000;
BA_ "GenSigSNA" SG_ 1008 EC_CBC1A "0h";
BA_ "FlexKomComment" SG_ 1008 EC_CBC1B "CBC ecu configuration 1";
BA_ "FlexKomIsMotorola" SG_ 1008 EC_CBC1B 1;
BA_ "FlexKomSID" SG_ 1008 EC_CBC1B 899;
BA_ "FlexKomSigLaenge" SG_ 1008 EC_CBC1B 32;
BA_ "FlexKomSigName" SG_ 1008 EC_CBC1B "EC_CBC1";
BA_ "FlexKomSigStartPos" SG_ 1008 EC_CBC1B 7;
BA_ "FlexKomSigStartValue" SG_ 1008 EC_CBC1B "00000000h";
BA_ "GenSigCycleTime" SG_ 1008 EC_CBC1B 2000;
BA_ "GenSigSNA" SG_ 1008 EC_CBC1B "0h";
BA_ "FlexKomComment" SG_ 1008 EC_CBC2 "CBC ecu configuration 2";
BA_ "FlexKomIsMotorola" SG_ 1008 EC_CBC2 1;
BA_ "FlexKomSID" SG_ 1008 EC_CBC2 900;
BA_ "FlexKomSigLaenge" SG_ 1008 EC_CBC2 32;
BA_ "FlexKomSigName" SG_ 1008 EC_CBC2 "EC_CBC2";
BA_ "FlexKomSigStartPos" SG_ 1008 EC_CBC2 39;
BA_ "FlexKomSigStartValue" SG_ 1008 EC_CBC2 "00000000h";
BA_ "GenSigCycleTime" SG_ 1008 EC_CBC2 2000;
BA_ "GenSigSNA" SG_ 1008 EC_CBC2 "0h";
BA_ "FlexKomComment" SG_ 1008 EC_ECUCfg1_Stat "ECU Configuration messages status 1";
BA_ "FlexKomIsMotorola" SG_ 1008 EC_ECUCfg1_Stat 1;
BA_ "FlexKomSID" SG_ 1008 EC_ECUCfg1_Stat 1058;
BA_ "FlexKomSigLaenge" SG_ 1008 EC_ECUCfg1_Stat 2;
BA_ "FlexKomSigName" SG_ 1008 EC_ECUCfg1_Stat "EC_ECUCfg1_Stat";
BA_ "FlexKomSigStartPos" SG_ 1008 EC_ECUCfg1_Stat 1;
BA_ "FlexKomSigStartValue" SG_ 1008 EC_ECUCfg1_Stat "03h";
BA_ "GenSigCycleTime" SG_ 1008 EC_ECUCfg1_Stat 2000;
BA_ "GenSigSNA" SG_ 1008 EC_ECUCfg1_Stat "3h";
BA_ "GenSigStartValue" SG_ 1008 EC_ECUCfg1_Stat 3;
VAL_ 993 DISPLACEMENT 255 "SNA" ;
VAL_ 993 ECM_Vehi_Type 0 "STANDARD" 1 "EVEHICLE" 3 "SNA" ;
VAL_ 993 ENG_ASP 0 "INTAKE_NORM" 1 "TURBO1" 2 "TURBO2" 3 "SUPER" 7 "SNA" ;
VAL_ 993 EngStyle 0 "CHOICE1" 1 "CHOICE2" 2 "CHOICE3" 3 "CHOICE4" 4 "CHOICE5" 5 "CHOICE6" 7 "SNA" ;
VAL_ 993 FUEL_TYPE 0 "UNLEADED" 1 "DIESEL" 2 "FLEX" 3 "CNG" 7 "SNA" ;
VAL_ 993 Manufacture 0 "ENG_DCA" 1 "ENG_DCS" 2 "ENG_MMC" 3 "ENG_HY" 7 "ENG_NP" ;
VAL_ 993 NUM_CYL 15 "SNA" ;
VAL_ 993 NUM_VALVE 7 "SNA" ;
VAL_ 770 AutoParkSts 0 "OFF" 1 "ON" 2 "GRADE" 3 "SNA" ;
VAL_ 770 EPBWarningLampReq 0 "OFF" 1 "CONT" 2 "BLINK" 3 "SNA" ;
VAL_ 770 EPB_Sw_Stat 0 "Not_Active" 1 "Active" 2 "S_FAULT" 3 "SNA" ;
VAL_ 770 FunctionLamp 0 "OFF" 1 "CONT" 2 "BLINK" 3 "SNA" ;
VAL_ 770 TextDisplay 0 "NONE" 1 "TxtMsg_1" 2 "TxtMsg_2" 3 "TxtMsg_3" 4 "TxtMsg_4" 5 "TxtMsg_5" 6 "TxtMsg_6" 7 "TxtMsg_7" 8 "TxtMsg_8" 9 "TxtMsg_9" 10 "TxtMsg_10" 11 "TxtMsg_11" 12 "TxtMsg_12" 13 "TxtMsg_13" 14 "TxtMsg_14" 15 "TxtMsg_15" 16 "TxtMsg_16" 17 "TxtMsg_17" 18 "TxtMsg_18" 19 "TxtMsg_19" 20 "TxtMsg_20" 21 "TxtMsg_21" 22 "TxtMsg_22" 23 "TxtMsg_23" 24 "TxtMsg_24" 25 "TxtMsg_25" 26 "TxtMsg_26" 27 "TxtMsg_27" 28 "TxtMsg_28" 29 "TxtMsg_29" 30 "TxtMsg_30" 31 "SNA" ;
VAL_ 669 EPBActivation 0 "NONE" 1 "STATIC_APPLY" 2 "STATIC_RELEASE" 3 "AUTO_APPLY_BTN" 4 "AUTO_APPLY_SHFT" 5 "AUTO_RELEASE_SHFT" 6 "DAR" 7 "SAFE_HOLD" 8 "TSA_APPLY" 9 "TSA_RELEASE" 10 "TSA_PERMANENT_APPLY" 11 "AHH_REQUEST" 12 "ACC_REQUEST" 13 "ESS_HSA_REQUEST" 14 "CDP" 15 "ESS_EPB_REQUEST" 16 "ADBF" 17 "ASSEMBLY_CHECK" 18 "DIAG_OPEN_BOTH" 19 "DIAG_CLOSE_BOTH" 20 "DIAG_OPEN_LEFT" 21 "DIAG_OPEN_RIGHT" 22 "DIAG_CLOSE_LEFT" 23 "DIAG_CLOSE_RIGHT" ;
VAL_ 669 EPBHoldSts 0 "REL" 1 "APPLIED" 2 "Applying" 3 "Releasing" 4 "DC" 5 "BSU" ;
VAL_ 544 AssistanceTorque 4095 "SNA" ;
VAL_ 544 TOI_Act_Sts 15 "SNA" 8 "INACT" 7 "DST_TOI_UCF" 6 "DSt_TOI_OCF" 5 "DST_TOI_MCF" 4 "DENIED" 3 "READY" 2 "DST_TOI_PNA" 1 "DST_TOI_TNA" 0 "TOI_DEACT" ;
VAL_ 544 EPSTemporaryDeactivationLDW 0 "False" 1 "True" ;
VAL_ 544 StrClmTrq 2047 "SNA" ;
VAL_ 544 StrClmTrqVD 0 "SNA" ;
VAL_ 300 EPS_AsstStat 0 "AST_ACT" 1 "AST_OFF" 2 "AST_RT" 7 "SNA" ;
VAL_ 300 EPS_Curr 255 "SNA" ;
VAL_ 300 EPS_ErrStat 0 "OK" 1 "ERR" 2 "ERR2" 3 "SERV_HI" 7 "SNA" ;
VAL_ 300 EPS_MODE_STAT 0 "MODE_1" 1 "MODE_2" 2 "MODE_3" 3 "LAST" 7 "SNA" ;
VAL_ 300 EPS_ModuleVoltage 255 "SNA" ;
VAL_ 300 EPS_Warn_Disp_Rq 0 "OK" 1 "ERR" 2 "ERR2" 3 "SERV_HI" 7 "SNA" ;
VAL_ 463 CodeCheckStsESL 0 "No_Code" 1 "CodeCheck_OK" 2 "CodeCheck_Fault" ;
VAL_ 463 ESLFeedbackCmd 0 "Undefined_Position" 3 "Lock" 5 "Unlock" 7 "SNA" ;
VAL_ 320 BrkPdl_Stat 0 "UPSTOP" 1 "PSD" 2 "NDEF2" 3 "SNA" ;
VAL_ 320 Brk_Stat 0 "IDLE" 1 "BRAKING" 2 "NDEF2" 3 "SNA" ;
VAL_ 320 DTR_CC_Enabled 0 "SNA" ;
VAL_ 320 DTR_CC_Engaged 0 "SNA" ;
VAL_ 320 ESP_Sys_Stat 0 "ABSERR" 1 "NORM" 2 "HALF" 3 "ABGAS" ;
VAL_ 320 REF_VEH_SPEED 1023 "SNA" ;
VAL_ 320 RollTestMd_Actv 0 "OFF" 1 "ON" 2 "NDEF2" 3 "SNA" ;
VAL_ 320 SPCR_AS_Off_Rq 0 "IDLE" 1 "AS_TMP_OFF" 2 "AS_CNTS_OFF" 3 "SPCR_NA" ;
VAL_ 268 DAS_RqActv 0 "IDLE" 1 "LFC" 2 "CMS" 3 "ABA" 4 "LSCM" 5 "VJC_Open_Loop" 6 "RHSC_Override" 7 "SNA" ;
VAL_ 268 EngTrq_Rq_ESC 8191 "SNA" ;
VAL_ 331 BrkPrss_TMC 2047 "SNA" ;
VAL_ 331 HSA_BrkPrss 63 "SNA" ;
VAL_ 331 PTS_Brk_Rq_RspSts 0 "OFF" 1 "ACTIVE" 2 "FAULTED" 3 "SNA" ;
VAL_ 332 VehAccel_X 255 "SNA" ;
VAL_ 332 VehAccel_X_Offset 255 "SNA" ;
VAL_ 332 VehAccel_Y 255 "SNA" ;
VAL_ 332 VehAccel_Y_Offset 255 "SNA" ;
VAL_ 332 VehYawRate_Offset 255 "SNA" ;
VAL_ 332 VehYawRate_Raw 65535 "SNA" ;
VAL_ 292 WhlPlsCnt_FL 255 "SNA" ;
VAL_ 292 WhlPlsCnt_FR 255 "SNA" ;
VAL_ 292 WhlPlsCnt_RL 255 "SNA" ;
VAL_ 292 WhlPlsCnt_RR 255 "SNA" ;
VAL_ 344 WhlDir_FL_Stat 0 "VOID" 1 "FORWARD" 2 "BACKWARD" 3 "SNA" ;
VAL_ 344 WhlDir_FR_Stat 0 "VOID" 1 "FORWARD" 2 "BACKWARD" 3 "SNA" ;
VAL_ 344 WhlDir_RL_Stat 0 "VOID" 1 "FORWARD" 2 "BACKWARD" 3 "SNA" ;
VAL_ 344 WhlDir_RR_Stat 0 "VOID" 1 "FORWARD" 2 "BACKWARD" 3 "SNA" ;
VAL_ 344 WhlRPM_FL 16383 "SNA" ;
VAL_ 344 WhlRPM_FR 16383 "SNA" ;
VAL_ 344 WhlRPM_RL 16383 "SNA" ;
VAL_ 344 WhlRPM_RR 16383 "SNA" ;
VAL_ 284 BrkTrq 4095 "SNA" ;
VAL_ 284 BrkTrq_D 4095 "SNA" ;
VAL_ 284 VEH_SPEED 65535 "SNA" ;
VAL_ 270 AHH_Status 0 "Not_Ready" 1 "Ready" 2 "Active" 3 "EPB_Ready" 4 "HYD_Ready" 7 "SNA" ;
VAL_ 270 WhlTrq_Rq_As 32767 "SNA" ;
VAL_ 270 WhlTrq_Rq_ESC 32767 "SNA" ;
VAL_ 736 ABS_IndLmp_On_Rq 0 "OFF" 1 "CONT" 2 "BLINK" 3 "SNA" ;
VAL_ 736 BrkIndLmp_On_Rq_ESC 0 "OFF" 1 "CONT" 2 "BLINK" 3 "SNA" ;
VAL_ 736 ESC_CtrlLmp_Info 0 "OFF" 1 "CONT" 2 "BLINK" 3 "SNA" ;
VAL_ 736 ESP_Off_IndLmp_On_Rq 0 "SNA" ;
VAL_ 736 LT_DIST 65535 "SNA" ;
VAL_ 736 RT_DIST 65535 "SNA" ;
VAL_ 682 BrakeSysStatePrim 0 "BrkSysPrim_Off" 1 "BrkSysPrim_Unavailable" 2 "BrkSysPrim_FailedDegraded" 3 "BrkSysPrim_FailedOperational" 4 "BrkSysPrim_FullSystem" 5 "BrkSysPrim_EmergencyMode" 7 "SNA" ;
VAL_ 682 ESC_BrakeState 0 "ESC_Off" 1 "ESC_Unavailable" 2 "ESC_FailedDegraded" 3 "ESC_FailedOperational" 4 "ESC_FullSystem" 5 "ESC_EmergencyMode" 7 "SNA" ;
VAL_ 682 SDS_Engaged_State_ESC 0 "Disengaged" 1 "Engaged_with_Driver" 2 "Engaged_Driverless" 3 "SNA" ;
VAL_ 682 qTargetExternal_Active 0 "qTarget_Off" 1 "qTarget_EBR" 2 "qTarget_EBRmaxPerformance" ;
VAL_ 840 FailSafeError 65535 "SNA" ;
VAL_ 1016 EC_BU_ECUCfg1_Stat 0 "NA" 1 "PROGAMMED" 2 "NA1" 3 "SNA" ;
VAL_ 989 EC_BU_ECUCfg10_Stat 0 "NA" 1 "PROGAMMED" 2 "NA1" 3 "SNA" ;
VAL_ 988 EC_BU_ECUCfg11_Stat 0 "NA" 1 "PROGAMMED" 2 "REQUEST_DATA" 3 "SNA" ;
VAL_ 987 EC_BU_ECUCfg12_Stat 0 "NA" 1 "PROGAMMED" 2 "NA1" 3 "SNA" ;
VAL_ 986 EC_BU_ECUCfg13_Stat 0 "NA" 1 "PROGAMMED" 2 "NA1" 3 "SNA" ;
VAL_ 985 EC_BU_ECUCfg14_Stat 0 "NA" 1 "PROGAMMED" 2 "NA1" 3 "SNA" ;
VAL_ 707 EC_BU_ECUCfg15_Stat 0 "NA" 1 "PROGAMMED" 2 "NA1" 3 "SNA" ;
VAL_ 714 EC_BU_ECUCfg16_Stat 0 "NA" 1 "PROGAMMED" 2 "NA1" 3 "SNA" ;
VAL_ 715 EC_BU_ECUCfg17_Stat 0 "NA" 1 "PROGAMMED" 2 "REQUEST_DATA" 3 "SNA" ;
VAL_ 1017 EC_BU_ECUCfg2_Stat 0 "NA" 1 "PROGAMMED" 2 "NA1" 3 "SNA" ;
VAL_ 1018 EC_BU_ECUCfg3_Stat 0 "NA" 1 "PROGAMMED" 2 "NA1" 3 "SNA" ;
VAL_ 1019 EC_BU_ECUCfg4_Stat 0 "NA" 1 "PROGAMMED" 2 "NA1" 3 "SNA" ;
VAL_ 1020 EC_BU_ECUCfg5_Stat 0 "NA" 1 "PROGAMMED" 2 "NA1" 3 "SNA" ;
VAL_ 1021 EC_BU_ECUCfg6_Stat 0 "NA" 1 "PROGAMMED" 2 "NA1" 3 "SNA" ;
VAL_ 1022 EC_BU_ECUCfg7_Stat 0 "NA" 1 "PROGAMMED" 2 "NA1" 3 "SNA" ;
VAL_ 1023 EC_BU_ECUCfg8_Stat 0 "NA" 1 "PROGAMMED" 2 "NA1" 3 "SNA" ;
VAL_ 991 EC_BU_ECUCfg9_Stat 0 "NA" 1 "PROGAMMED" 2 "NA1" 3 "SNA" ;
VAL_ 1008 EC_ECUCfg1_Stat 0 "NA" 1 "PROGAMMED" 2 "REQUEST_DATA" 3 "SNA" ;
